[part 3 of 23: packages /E3_1_1_UNECE_Gen2 to /Cluster]
AUTOSAR XML (schema 4-3-0)
package /E3_1_1_UNECE_Gen2  (continued)
  system System  (continued)
    system mapping System_Mappings  (continued)
      data-mappings:  (continued)
        communication-direction=IN, data-element=Grundumfang_XIX_Klima.Geltungsbereich_E3_1_1_UNECE_Gen2.RP_IF_PTC_HVb_Err_Intern_TNCTOC_XIX_Grundumfang_XIX_Klima.DE_PTC_HVb_Err_Intern_TNCTOC, system-signal=PTC_HVb_Err_Intern_TNCTOC
        communication-direction=IN, data-element=Grundumfang_XIX_Klima.Geltungsbereich_E3_1_1_UNECE_Gen2.RP_IF_PTC_HVb_Err_Leckagestrom_XIX_Grundumfang_XIX_Klima.DE_PTC_HVb_Err_Leckagestrom, system-signal=PTC_HVb_Err_Leckagestrom
        communication-direction=IN, data-element=Grundumfang_XIX_Klima.Geltungsbereich_E3_1_1_UNECE_Gen2.RP_IF_PTC_HVb_Err_Leckagestrom_TNCTOC_XIX_Grundumfang_XIX_Klima.DE_PTC_HVb_Err_Leckagestrom_TNCTOC, system-signal=PTC_HVb_Err_Leckagestrom_TNCTOC
        communication-direction=IN, data-element=Grundumfang_XIX_Klima.Geltungsbereich_E3_1_1_UNECE_Gen2.RP_IF_PTC_HVb_Err_Temperaturschutz_XIX_Grundumfang_XIX_Klima.DE_PTC_HVb_Err_Temperaturschutz, system-signal=PTC_HVb_Err_Temperaturschutz
        communication-direction=IN, data-element=Grundumfang_XIX_Klima.Geltungsbereich_E3_1_1_UNECE_Gen2.RP_IF_PTC_HVb_Err_TempSchutz_TNCTOC_XIX_Grundumfang_XIX_Klima.DE_PTC_HVb_Err_TempSchutz_TNCTOC, system-signal=PTC_HVb_Err_TempSchutz_TNCTOC
        communication-direction=IN, data-element=Grundumfang_XIX_Klima.Geltungsbereich_E3_1_1_UNECE_Gen2.RP_IF_PTC_HVb_ERR_TNCTOC_XIX_Grundumfang_XIX_Klima.DE_PTC_HVb_ERR_TNCTOC, system-signal=PTC_HVb_ERR_TNCTOC
        communication-direction=IN, data-element=Grundumfang_XIX_Klima.Geltungsbereich_E3_1_1_UNECE_Gen2.RP_IF_PTC_HVb_Err_Ueberstromabs_TNCTOC_XIX_Grundumfang_XIX_Klima.DE_PTC_HVb_Err_Ueberstromabs_TNCTOC, system-signal=PTC_HVb_Err_Ueberstromabs_TNCTOC
        communication-direction=IN, data-element=Grundumfang_XIX_Klima.Geltungsbereich_E3_1_1_UNECE_Gen2.RP_IF_PTC_HVb_Err_Ueberstromabschaltung_XIX_Grundumfang_XIX_Klima.DE_PTC_HVb_Err_Ueberstromabschaltung, system-signal=PTC_HVb_Err_Ueberstromabschaltung
        communication-direction=IN, data-element=Grundumfang_XIX_Klima.Geltungsbereich_E3_1_1_UNECE_Gen2.RP_IF_PTC_HVb_Heizmedium_Sensor_1_XIX_Grundumfang_XIX_Klima.DE_PTC_HVb_Heizmedium_Sensor_1, system-signal=PTC_HVb_Heizmedium_Sensor_1
        communication-direction=IN, data-element=Grundumfang_XIX_Klima.Geltungsbereich_E3_1_1_UNECE_Gen2.RP_IF_PTC_HVb_Heizmedium_Sensor_2_XIX_Grundumfang_XIX_Klima.DE_PTC_HVb_Heizmedium_Sensor_2, system-signal=PTC_HVb_Heizmedium_Sensor_2
        communication-direction=IN, data-element=Grundumfang_XIX_Klima.Geltungsbereich_E3_1_1_UNECE_Gen2.RP_IF_PTC_HVb_I_ist_XIX_Grundumfang_XIX_Klima.DE_PTC_HVb_I_ist, system-signal=PTC_HVb_I_ist
        communication-direction=IN, data-element=Grundumfang_XIX_Klima.Geltungsbereich_E3_1_1_UNECE_Gen2.RP_IF_PTC_HVb_ResponseError_XIX_Grundumfang_XIX_Klima.DE_PTC_HVb_ResponseError, system-signal=PTC_HVb_ResponseError
        communication-direction=IN, data-element=Grundumfang_XIX_Klima.Geltungsbereich_E3_1_1_UNECE_Gen2.RP_IF_PTC_HVb_Status_PTC_XIX_Grundumfang_XIX_Klima.DE_PTC_HVb_Status_PTC, system-signal=PTC_HVb_Status_PTC
        communication-direction=IN, data-element=Grundumfang_XIX_Klima.Geltungsbereich_E3_1_1_UNECE_Gen2.RP_IF_PTC_HVb_Status_UBatt_XIX_Grundumfang_XIX_Klima.DE_PTC_HVb_Status_UBatt, system-signal=PTC_HVb_Status_UBatt
        communication-direction=IN, data-element=Grundumfang_XIX_Klima.Geltungsbereich_E3_1_1_UNECE_Gen2.RP_IF_PTC_HVb_Temp_PCB_XIX_Grundumfang_XIX_Klima.DE_PTC_HVb_Temp_PCB, system-signal=PTC_HVb_Temp_PCB
        communication-direction=IN, data-element=Grundumfang_XIX_Klima.Geltungsbereich_E3_1_1_UNECE_Gen2.RP_IF_PTC_HVb_TimeOut_Fehler_XIX_Grundumfang_XIX_Klima.DE_PTC_HVb_TimeOut_Fehler, system-signal=PTC_HVb_TimeOut_Fehler
        communication-direction=IN, data-element=Grundumfang_XIX_Klima.Geltungsbereich_E3_1_1_UNECE_Gen2.RP_IF_PTC_HVb_UBatt_XIX_Grundumfang_XIX_Klima.DE_PTC_HVb_UBatt, system-signal=PTC_HVb_UBatt
        communication-direction=IN, data-element=Grundumfang_XIX_Klima.Geltungsbereich_E3_1_1_UNECE_Gen2.RP_IF_PTC_HW_XIX_Grundumfang_XIX_Klima.DE_PTC_HW, system-signal=PTC_HW
        communication-direction=IN, data-element=Grundumfang_XIX_Klima.Geltungsbereich_E3_1_1_UNECE_Gen2.RP_IF_PTC_I_ist_XIX_Grundumfang_XIX_Klima.DE_PTC_I_ist, system-signal=PTC_I_ist
        communication-direction=OUT, data-element=Grundumfang_XIX_Klima.Geltungsbereich_E3_1_1_UNECE_Gen2.SP_IF_PTC_I_ist_XIX_Grundumfang_XIX_Klima.DE_PTC_I_ist, system-signal=PTC_I_ist
        communication-direction=OUT, data-element=Grundumfang_XIX_Klima.Geltungsbereich_E3_1_1_UNECE_Gen2.SP_IF_PTC_Nenn_Strom_XIX_Grundumfang_XIX_Klima.DE_PTC_Nenn_Strom, system-signal=PTC_Nenn_Strom
        communication-direction=IN, data-element=Grundumfang_XIX_Klima.Geltungsbereich_E3_1_1_UNECE_Gen2.RP_IF_PTC_P_ist_XIX_Grundumfang_XIX_Klima.DE_PTC_P_ist, system-signal=PTC_P_ist
        communication-direction=OUT, data-element=Grundumfang_XIX_Klima.Geltungsbereich_E3_1_1_UNECE_Gen2.SP_IF_PTC_P_ist_XIX_Grundumfang_XIX_Klima.DE_PTC_P_ist, system-signal=PTC_P_ist
        communication-direction=IN, data-element=Grundumfang_XIX_Klima.Geltungsbereich_E3_1_1_UNECE_Gen2.RP_IF_PTC_ResponseError_XIX_Grundumfang_XIX_Klima.DE_PTC_ResponseError, system-signal=PTC_ResponseError
        communication-direction=IN, data-element=Grundumfang_XIX_Klima.Geltungsbereich_E3_1_1_UNECE_Gen2.RP_IF_PTC_Status_XIX_Grundumfang_XIX_Klima.DE_PTC_Status, system-signal=PTC_Status
        communication-direction=IN, data-element=Grundumfang_XIX_Klima.Geltungsbereich_E3_1_1_UNECE_Gen2.RP_IF_PTC_Status_PTC_XIX_Grundumfang_XIX_Klima.DE_PTC_Status_PTC, system-signal=PTC_Status_PTC
        communication-direction=IN, data-element=Grundumfang_XIX_Klima.Geltungsbereich_E3_1_1_UNECE_Gen2.RP_IF_PTC_Status_UBatt_XIX_Grundumfang_XIX_Klima.DE_PTC_Status_UBatt, system-signal=PTC_Status_UBatt
        communication-direction=IN, data-element=Grundumfang_XIX_Klima.Geltungsbereich_E3_1_1_UNECE_Gen2.RP_IF_PTC_SW_XIX_Grundumfang_XIX_Klima.DE_PTC_SW, system-signal=PTC_SW
        communication-direction=IN, data-element=Grundumfang_XIX_Klima.Geltungsbereich_E3_1_1_UNECE_Gen2.RP_IF_PTC_Temp_PCB_XIX_Grundumfang_XIX_Klima.DE_PTC_Temp_PCB, system-signal=PTC_Temp_PCB
        communication-direction=IN, data-element=Grundumfang_XIX_Klima.Geltungsbereich_E3_1_1_UNECE_Gen2.RP_IF_PTC_TimeOut_Fehler_XIX_Grundumfang_XIX_Klima.DE_PTC_TimeOut_Fehler, system-signal=PTC_TimeOut_Fehler
        communication-direction=IN, data-element=Grundumfang_XIX_Klima.Geltungsbereich_E3_1_1_UNECE_Gen2.RP_IF_PTC_UBatt_XIX_Grundumfang_XIX_Klima.DE_PTC_UBatt, system-signal=PTC_UBatt
        communication-direction=OUT, data-element=Grundumfang_XIX_Klima.Geltungsbereich_E3_1_1_UNECE_Gen2.SP_IF_PTCs_01_alt_XIX_Grundumfang_XIX_Klima.DE_PTCs_01_alt, system-signal=PTCs_01_alt
        communication-direction=IN, data-element=Grundumfang_XIX_Klima.Geltungsbereich_E3_1_1_UNECE_Gen2.RP_IF_RS_defekt_XIX_Grundumfang_XIX_Klima.DE_RS_defekt, system-signal=RS_defekt
        communication-direction=IN, data-element=Grundumfang_XIX_Klima.Geltungsbereich_E3_1_1_UNECE_Gen2.RP_IF_RS_Regenmenge_XIX_Grundumfang_XIX_Klima.DE_RS_Regenmenge, system-signal=RS_Regenmenge
        communication-direction=IN, data-element=Grundumfang_XIX_Klima.Geltungsbereich_E3_1_1_UNECE_Gen2.RP_IF_RS_Wischergeschwindigkeit_XIX_Grundumfang_XIX_Klima.DE_RS_Wischergeschwindigkeit, system-signal=RS_Wischergeschwindigkeit
        communication-direction=OUT, data-element=Grundumfang_XIX_Klima.Geltungsbereich_E3_1_1_UNECE_Gen2.SP_IF_Scheibenreinigung_XIX_Grundumfang_XIX_Klima.DE_Scheibenreinigung, system-signal=Scheibenreinigung
        communication-direction=IN, data-element=Grundumfang_XIX_Klima.Geltungsbereich_E3_1_1_UNECE_Gen2.RP_IF_SI_BUS_04_XIX_Grundumfang_XIX_Klima.DE_SI_BUS_04, system-signal=SI_BUS_04
        communication-direction=IN, data-element=Grundumfang_XIX_Klima.Geltungsbereich_E3_1_1_UNECE_Gen2.RP_IF_SI_CAB_V15_XIX_Grundumfang_XIX_Klima.DE_SI_CAB_V15, system-signal=SI_CAB_V15
        communication-direction=IN, data-element=Grundumfang_XIX_Klima.Geltungsbereich_E3_1_1_UNECE_Gen2.RP_IF_SI_NWDF_XIX_Grundumfang_XIX_Klima.DE_SI_NWDF, system-signal=SI_NWDF
        communication-direction=IN, data-element=Grundumfang_XIX_Klima.Geltungsbereich_E3_1_1_UNECE_Gen2.RP_IF_SI_NWDF_gueltig_XIX_Grundumfang_XIX_Klima.DE_SI_NWDF_gueltig, system-signal=SI_NWDF_gueltig
        communication-direction=IN, data-element=Grundumfang_XIX_Klima.Geltungsbereich_E3_1_1_UNECE_Gen2.RP_IF_SI_P_Mode_XIX_Grundumfang_XIX_Klima.DE_SI_P_Mode, system-signal=SI_P_Mode
        communication-direction=IN, data-element=Grundumfang_XIX_Klima.Geltungsbereich_E3_1_1_UNECE_Gen2.RP_IF_SI_P_Mode_gueltig_XIX_Grundumfang_XIX_Klima.DE_SI_P_Mode_gueltig, system-signal=SI_P_Mode_gueltig
        communication-direction=IN, data-element=Grundumfang_XIX_Klima.Geltungsbereich_E3_1_1_UNECE_Gen2.RP_IF_SI_QRS_Mode_XIX_Grundumfang_XIX_Klima.DE_SI_QRS_Mode, system-signal=SI_QRS_Mode
        communication-direction=IN, data-element=Grundumfang_XIX_Klima.Geltungsbereich_E3_1_1_UNECE_Gen2.RP_IF_SI_T_Mode_XIX_Grundumfang_XIX_Klima.DE_SI_T_Mode, system-signal=SI_T_Mode
        communication-direction=OUT, data-element=Grundumfang_XIX_Klima.Geltungsbereich_E3_1_1_UNECE_Gen2.SP_IF_SI_T_Mode_XIX_Grundumfang_XIX_Klima.DE_SI_T_Mode, system-signal=SI_T_Mode
        communication-direction=IN, data-element=Grundumfang_XIX_Klima.Geltungsbereich_E3_1_1_UNECE_Gen2.RP_IF_SI_T_Schutz_XIX_Grundumfang_XIX_Klima.DE_SI_T_Schutz, system-signal=SI_T_Schutz
        communication-direction=OUT, data-element=Grundumfang_XIX_Klima.Geltungsbereich_E3_1_1_UNECE_Gen2.SP_IF_SI_T_Schutz_XIX_Grundumfang_XIX_Klima.DE_SI_T_Schutz, system-signal=SI_T_Schutz
        communication-direction=OUT, data-element=Grundumfang_XIX_Klima.Geltungsbereich_E3_1_1_UNECE_Gen2.SP_IF_SIL_Stufe_LED_HL_XIX_Grundumfang_XIX_Klima.DE_SIL_Stufe_LED_HL, system-signal=SIL_Stufe_LED_HL
        communication-direction=OUT, data-element=Grundumfang_XIX_Klima.Geltungsbereich_E3_1_1_UNECE_Gen2.SP_IF_SIL_Stufe_LED_HR_XIX_Grundumfang_XIX_Klima.DE_SIL_Stufe_LED_HR, system-signal=SIL_Stufe_LED_HR
        communication-direction=IN, data-element=Grundumfang_XIX_Klima.Geltungsbereich_E3_1_1_UNECE_Gen2.RP_IF_SIL_Stufe_LED_li_XIX_Grundumfang_XIX_Klima.DE_SIL_Stufe_LED_li, system-signal=SIL_Stufe_LED_li
        communication-direction=IN, data-element=Grundumfang_XIX_Klima.Geltungsbereich_E3_1_1_UNECE_Gen2.RP_IF_SIL_Stufe_LED_re_XIX_Grundumfang_XIX_Klima.DE_SIL_Stufe_LED_re, system-signal=SIL_Stufe_LED_re
        communication-direction=IN, data-element=Grundumfang_XIX_Klima.Geltungsbereich_E3_1_1_UNECE_Gen2.RP_IF_SMod_SIH_Stufe_hl_XIX_Grundumfang_XIX_Klima.DE_SMod_SIH_Stufe_hl, system-signal=SMod_SIH_Stufe_hl
        communication-direction=IN, data-element=Grundumfang_XIX_Klima.Geltungsbereich_E3_1_1_UNECE_Gen2.RP_IF_SMod_SIH_Stufe_hr_XIX_Grundumfang_XIX_Klima.DE_SMod_SIH_Stufe_hr, system-signal=SMod_SIH_Stufe_hr
        communication-direction=IN, data-element=Grundumfang_XIX_Klima.Geltungsbereich_E3_1_1_UNECE_Gen2.RP_IF_SMod_SIL_Stufe_hl_XIX_Grundumfang_XIX_Klima.DE_SMod_SIL_Stufe_hl, system-signal=SMod_SIL_Stufe_hl
        communication-direction=IN, data-element=Grundumfang_XIX_Klima.Geltungsbereich_E3_1_1_UNECE_Gen2.RP_IF_SMod_SIL_Stufe_hr_XIX_Grundumfang_XIX_Klima.DE_SMod_SIL_Stufe_hr, system-signal=SMod_SIL_Stufe_hr
        communication-direction=IN, data-element=Grundumfang_XIX_Klima.Geltungsbereich_E3_1_1_UNECE_Gen2.RP_IF_SMod_SRH_Fehler_XIX_Grundumfang_XIX_Klima.DE_SMod_SRH_Fehler, system-signal=SMod_SRH_Fehler
        communication-direction=IN, data-element=Grundumfang_XIX_Klima.Geltungsbereich_E3_1_1_UNECE_Gen2.RP_IF_SMod_SRH_ResponseError_XIX_Grundumfang_XIX_Klima.DE_SMod_SRH_ResponseError, system-signal=SMod_SRH_ResponseError
        communication-direction=OUT, data-element=Grundumfang_XIX_Klima.Geltungsbereich_E3_1_1_UNECE_Gen2.SP_IF_SOK_FoD_Klima_Req_Challenge_XIX_Grundumfang_XIX_Klima.DE_SOK_FoD_Klima_Req_Challenge, system-signal=SOK_FoD_Klima_Req_Challenge
        communication-direction=IN, data-element=Grundumfang_XIX_Klima.Geltungsbereich_E3_1_1_UNECE_Gen2.RP_IF_SOK_FoD_Klima_Resp_Challenge_XIX_Grundumfang_XIX_Klima.DE_SOK_FoD_Klima_Resp_Challenge, system-signal=SOK_FoD_Klima_Resp_Challenge
        communication-direction=OUT, data-element=Grundumfang_XIX_Klima.Geltungsbereich_E3_1_1_UNECE_Gen2.SP_IF_Soll_Lehne_LLR_li_1_XIX_Grundumfang_XIX_Klima.DE_Soll_Lehne_LLR_li_1, system-signal=Soll_Lehne_LLR_li_1
        communication-direction=OUT, data-element=Grundumfang_XIX_Klima.Geltungsbereich_E3_1_1_UNECE_Gen2.SP_IF_Soll_Lehne_LLR_li_2_XIX_Grundumfang_XIX_Klima.DE_Soll_Lehne_LLR_li_2, system-signal=Soll_Lehne_LLR_li_2
        communication-direction=OUT, data-element=Grundumfang_XIX_Klima.Geltungsbereich_E3_1_1_UNECE_Gen2.SP_IF_Soll_Lehne_LLR_re_1_XIX_Grundumfang_XIX_Klima.DE_Soll_Lehne_LLR_re_1, system-signal=Soll_Lehne_LLR_re_1
        communication-direction=OUT, data-element=Grundumfang_XIX_Klima.Geltungsbereich_E3_1_1_UNECE_Gen2.SP_IF_Soll_Lehne_LLR_re_2_XIX_Grundumfang_XIX_Klima.DE_Soll_Lehne_LLR_re_2, system-signal=Soll_Lehne_LLR_re_2
        communication-direction=OUT, data-element=Grundumfang_XIX_Klima.Geltungsbereich_E3_1_1_UNECE_Gen2.SP_IF_Soll_Sitz_LLR_li_1_XIX_Grundumfang_XIX_Klima.DE_Soll_Sitz_LLR_li_1, system-signal=Soll_Sitz_LLR_li_1
        communication-direction=OUT, data-element=Grundumfang_XIX_Klima.Geltungsbereich_E3_1_1_UNECE_Gen2.SP_IF_Soll_Sitz_LLR_li_2_XIX_Grundumfang_XIX_Klima.DE_Soll_Sitz_LLR_li_2, system-signal=Soll_Sitz_LLR_li_2
        communication-direction=OUT, data-element=Grundumfang_XIX_Klima.Geltungsbereich_E3_1_1_UNECE_Gen2.SP_IF_Soll_Sitz_LLR_re_1_XIX_Grundumfang_XIX_Klima.DE_Soll_Sitz_LLR_re_1, system-signal=Soll_Sitz_LLR_re_1
        communication-direction=OUT, data-element=Grundumfang_XIX_Klima.Geltungsbereich_E3_1_1_UNECE_Gen2.SP_IF_Soll_Sitz_LLR_re_2_XIX_Grundumfang_XIX_Klima.DE_Soll_Sitz_LLR_re_2, system-signal=Soll_Sitz_LLR_re_2
        communication-direction=IN, data-element=Grundumfang_XIX_Klima.Geltungsbereich_E3_1_1_UNECE_Gen2.RP_IF_SoSe_SunInt_2D_Li_XIX_Grundumfang_XIX_Klima.DE_SoSe_SunInt_2D_Li, system-signal=SoSe_SunInt_2D_Li
        communication-direction=IN, data-element=Grundumfang_XIX_Klima.Geltungsbereich_E3_1_1_UNECE_Gen2.RP_IF_SoSe_SunInt_2D_Re_XIX_Grundumfang_XIX_Klima.DE_SoSe_SunInt_2D_Re, system-signal=SoSe_SunInt_2D_Re
        communication-direction=IN, data-element=Grundumfang_XIX_Klima.Geltungsbereich_E3_1_1_UNECE_Gen2.RP_IF_ST_VLD_BLW_CTRL_1_LIN_XIX_Grundumfang_XIX_Klima.DE_ST_VLD_BLW_CTRL_1_LIN, system-signal=ST_VLD_BLW_CTRL_1_LIN
        communication-direction=IN, data-element=Grundumfang_XIX_Klima.Geltungsbereich_E3_1_1_UNECE_Gen2.RP_IF_ST_VLD_BLWb_CTRL_1_LIN_XIX_Grundumfang_XIX_Klima.DE_ST_VLD_BLWb_CTRL_1_LIN, system-signal=ST_VLD_BLWb_CTRL_1_LIN
        communication-direction=IN, data-element=Grundumfang_XIX_Klima.Geltungsbereich_E3_1_1_UNECE_Gen2.RP_IF_ST_VLD_BLWc_CTRL_1_LIN_XIX_Grundumfang_XIX_Klima.DE_ST_VLD_BLWc_CTRL_1_LIN, system-signal=ST_VLD_BLWc_CTRL_1_LIN
        communication-direction=IN, data-element=Grundumfang_XIX_Klima.Geltungsbereich_E3_1_1_UNECE_Gen2.RP_IF_STK_AirCLeaner_Anf_XIX_Grundumfang_XIX_Klima.DE_STK_AirCLeaner_Anf, system-signal=STK_AirCLeaner_Anf
        communication-direction=IN, data-element=Grundumfang_XIX_Klima.Geltungsbereich_E3_1_1_UNECE_Gen2.RP_IF_STK_Anf_AussenspiegelHZ_XIX_Grundumfang_XIX_Klima.DE_STK_Anf_AussenspiegelHZ, system-signal=STK_Anf_AussenspiegelHZ
        communication-direction=IN, data-element=Grundumfang_XIX_Klima.Geltungsbereich_E3_1_1_UNECE_Gen2.RP_IF_STK_Berechnungsphase_XIX_Grundumfang_XIX_Klima.DE_STK_Berechnungsphase, system-signal=STK_Berechnungsphase
        communication-direction=IN, data-element=Grundumfang_XIX_Klima.Geltungsbereich_E3_1_1_UNECE_Gen2.RP_IF_STK_Betriebsdauer_XIX_Grundumfang_XIX_Klima.DE_STK_Betriebsdauer, system-signal=STK_Betriebsdauer
        communication-direction=IN, data-element=Grundumfang_XIX_Klima.Geltungsbereich_E3_1_1_UNECE_Gen2.RP_IF_STK_ErwVK_Anf_XIX_Grundumfang_XIX_Klima.DE_STK_ErwVK_Anf, system-signal=STK_ErwVK_Anf
        communication-direction=IN, data-element=Grundumfang_XIX_Klima.Geltungsbereich_E3_1_1_UNECE_Gen2.RP_IF_STK_ErwVK_Beifahrerzone_XIX_Grundumfang_XIX_Klima.DE_STK_ErwVK_Beifahrerzone, system-signal=STK_ErwVK_Beifahrerzone
        communication-direction=IN, data-element=Grundumfang_XIX_Klima.Geltungsbereich_E3_1_1_UNECE_Gen2.RP_IF_STK_ErwVK_Fahrerzone_XIX_Grundumfang_XIX_Klima.DE_STK_ErwVK_Fahrerzone, system-signal=STK_ErwVK_Fahrerzone
        communication-direction=IN, data-element=Grundumfang_XIX_Klima.Geltungsbereich_E3_1_1_UNECE_Gen2.RP_IF_STK_ErwVK_Heckzone_links_XIX_Grundumfang_XIX_Klima.DE_STK_ErwVK_Heckzone_links, system-signal=STK_ErwVK_Heckzone_links
        communication-direction=IN, data-element=Grundumfang_XIX_Klima.Geltungsbereich_E3_1_1_UNECE_Gen2.RP_IF_STK_ErwVK_Heckzone_rechts_XIX_Grundumfang_XIX_Klima.DE_STK_ErwVK_Heckzone_rechts, system-signal=STK_ErwVK_Heckzone_rechts
        communication-direction=IN, data-element=Grundumfang_XIX_Klima.Geltungsbereich_E3_1_1_UNECE_Gen2.RP_IF_STK_ErwVK_Modus_XIX_Grundumfang_XIX_Klima.DE_STK_ErwVK_Modus, system-signal=STK_ErwVK_Modus
        communication-direction=IN, data-element=Grundumfang_XIX_Klima.Geltungsbereich_E3_1_1_UNECE_Gen2.RP_IF_STK_ErwVK_Scheibenheizung_XIX_Grundumfang_XIX_Klima.DE_STK_ErwVK_Scheibenheizung, system-signal=STK_ErwVK_Scheibenheizung
        communication-direction=IN, data-element=Grundumfang_XIX_Klima.Geltungsbereich_E3_1_1_UNECE_Gen2.RP_IF_STK_FSH_Anf_XIX_Grundumfang_XIX_Klima.DE_STK_FSH_Anf, system-signal=STK_FSH_Anf
        communication-direction=IN, data-element=Grundumfang_XIX_Klima.Geltungsbereich_E3_1_1_UNECE_Gen2.RP_IF_STK_HSH_Anf_XIX_Grundumfang_XIX_Klima.DE_STK_HSH_Anf, system-signal=STK_HSH_Anf
        communication-direction=IN, data-element=Grundumfang_XIX_Klima.Geltungsbereich_E3_1_1_UNECE_Gen2.RP_IF_STK_Klima_Temp_XIX_Grundumfang_XIX_Klima.DE_STK_Klima_Temp, system-signal=STK_Klima_Temp
        communication-direction=IN, data-element=Grundumfang_XIX_Klima.Geltungsbereich_E3_1_1_UNECE_Gen2.RP_IF_STK_KurzVK_Anf_XIX_Grundumfang_XIX_Klima.DE_STK_KurzVK_Anf, system-signal=STK_KurzVK_Anf
        communication-direction=IN, data-element=KlimaStandklimatisierung_Klima_C_XIX_Standklima_XIX_Klima.Geltungsbereich_E3_1_1_UNECE_Gen2.RP_IF_STK_Sofortstart_Sperre_FFB_XIX_KlimaStandklimatisierung_Klima_C_XIX_Standklima_XIX_Klima.DE_STK_Sofortstart_Sperre_FFB, system-signal=STK_Sofortstart_Sperre_FFB
        communication-direction=IN, data-element=Grundumfang_XIX_Klima.Geltungsbereich_E3_1_1_UNECE_Gen2.RP_IF_STK_Standklima_Anf_XIX_Grundumfang_XIX_Klima.DE_STK_Standklima_Anf, system-signal=STK_Standklima_Anf
        communication-direction=IN, data-element=Grundumfang_XIX_Klima.Geltungsbereich_E3_1_1_UNECE_Gen2.RP_IF_STK_Standklima_Timer_Status_XIX_Grundumfang_XIX_Klima.DE_STK_Standklima_Timer_Status, system-signal=STK_Standklima_Timer_Status
        communication-direction=IN, data-element=Grundumfang_XIX_Klima.Geltungsbereich_E3_1_1_UNECE_Gen2.RP_IF_STK_VK_Modus_XIX_Grundumfang_XIX_Klima.DE_STK_VK_Modus, system-signal=STK_VK_Modus
        communication-direction=OUT, data-element=Grundumfang_XIX_Klima.Geltungsbereich_E3_1_1_UNECE_Gen2.SP_IF_STRG1_Adresse_Aktuator_XIX_Grundumfang_XIX_Klima.DE_STRG1_Adresse_Aktuator, system-signal=STRG1_Adresse_Aktuator
        communication-direction=OUT, data-element=Grundumfang_XIX_Klima.Geltungsbereich_E3_1_1_UNECE_Gen2.SP_IF_STRG1_Geschwindigkeitsvorgabe_XIX_Grundumfang_XIX_Klima.DE_STRG1_Geschwindigkeitsvorgabe, system-signal=STRG1_Geschwindigkeitsvorgabe
        communication-direction=OUT, data-element=Grundumfang_XIX_Klima.Geltungsbereich_E3_1_1_UNECE_Gen2.SP_IF_STRG1_Notlauffreigabe_XIX_Grundumfang_XIX_Klima.DE_STRG1_Notlauffreigabe, system-signal=STRG1_Notlauffreigabe
        communication-direction=OUT, data-element=Grundumfang_XIX_Klima.Geltungsbereich_E3_1_1_UNECE_Gen2.SP_IF_STRG1_Select_Positionsvorgabe_XIX_Grundumfang_XIX_Klima.DE_STRG1_Select_Positionsvorgabe, system-signal=STRG1_Select_Positionsvorgabe
        communication-direction=OUT, data-element=Grundumfang_XIX_Klima.Geltungsbereich_E3_1_1_UNECE_Gen2.SP_IF_STRG1_Soll_Position_Aktuator_XIX_Grundumfang_XIX_Klima.DE_STRG1_Soll_Position_Aktuator, system-signal=STRG1_Soll_Position_Aktuator
        communication-direction=OUT, data-element=Grundumfang_XIX_Klima.Geltungsbereich_E3_1_1_UNECE_Gen2.SP_IF_STRG1_Spulenbestromung_XIX_Grundumfang_XIX_Klima.DE_STRG1_Spulenbestromung, system-signal=STRG1_Spulenbestromung
        communication-direction=OUT, data-element=Grundumfang_XIX_Klima.Geltungsbereich_E3_1_1_UNECE_Gen2.SP_IF_STRG4_Adresse_Aktuator_XIX_Grundumfang_XIX_Klima.DE_STRG4_Adresse_Aktuator, system-signal=STRG4_Adresse_Aktuator
        communication-direction=OUT, data-element=Grundumfang_XIX_Klima.Geltungsbereich_E3_1_1_UNECE_Gen2.SP_IF_STRG4_Clear_Event_Flags_XIX_Grundumfang_XIX_Klima.DE_STRG4_Clear_Event_Flags, system-signal=STRG4_Clear_Event_Flags
        communication-direction=OUT, data-element=Grundumfang_XIX_Klima.Geltungsbereich_E3_1_1_UNECE_Gen2.SP_IF_STRG4_Drehrichtung_XIX_Grundumfang_XIX_Klima.DE_STRG4_Drehrichtung, system-signal=STRG4_Drehrichtung
        communication-direction=OUT, data-element=Grundumfang_XIX_Klima.Geltungsbereich_E3_1_1_UNECE_Gen2.SP_IF_STRG4_Freigabe_Blockiererkennung_XIX_Grundumfang_XIX_Klima.DE_STRG4_Freigabe_Blockiererkennung, system-signal=STRG4_Freigabe_Blockiererkennung
        communication-direction=OUT, data-element=Grundumfang_XIX_Klima.Geltungsbereich_E3_1_1_UNECE_Gen2.SP_IF_STRG4_Geschwindigkeitsvorgabe_XIX_Grundumfang_XIX_Klima.DE_STRG4_Geschwindigkeitsvorgabe, system-signal=STRG4_Geschwindigkeitsvorgabe
        communication-direction=OUT, data-element=Grundumfang_XIX_Klima.Geltungsbereich_E3_1_1_UNECE_Gen2.SP_IF_STRG4_Notlauffreigabe_XIX_Grundumfang_XIX_Klima.DE_STRG4_Notlauffreigabe, system-signal=STRG4_Notlauffreigabe
        communication-direction=OUT, data-element=Grundumfang_XIX_Klima.Geltungsbereich_E3_1_1_UNECE_Gen2.SP_IF_STRG4_Notlaufposition_XIX_Grundumfang_XIX_Klima.DE_STRG4_Notlaufposition, system-signal=STRG4_Notlaufposition
        communication-direction=OUT, data-element=Grundumfang_XIX_Klima.Geltungsbereich_E3_1_1_UNECE_Gen2.SP_IF_STRG4_Programmierdaten_speichern_XIX_Grundumfang_XIX_Klima.DE_STRG4_Programmierdaten_speichern, system-signal=STRG4_Programmierdaten_speichern
        communication-direction=OUT, data-element=Grundumfang_XIX_Klima.Geltungsbereich_E3_1_1_UNECE_Gen2.SP_IF_STRG4_Select_Positionsvorgabe_XIX_Grundumfang_XIX_Klima.DE_STRG4_Select_Positionsvorgabe, system-signal=STRG4_Select_Positionsvorgabe
        communication-direction=OUT, data-element=Grundumfang_XIX_Klima.Geltungsbereich_E3_1_1_UNECE_Gen2.SP_IF_STRG4_Soll_Position_Aktuator_XIX_Grundumfang_XIX_Klima.DE_STRG4_Soll_Position_Aktuator, system-signal=STRG4_Soll_Position_Aktuator
        communication-direction=OUT, data-element=Grundumfang_XIX_Klima.Geltungsbereich_E3_1_1_UNECE_Gen2.SP_IF_STRG4_Spulenbestromung_XIX_Grundumfang_XIX_Klima.DE_STRG4_Spulenbestromung, system-signal=STRG4_Spulenbestromung
        communication-direction=OUT, data-element=Grundumfang_XIX_Klima.Geltungsbereich_E3_1_1_UNECE_Gen2.SP_IF_STRG4_Start_Position_Aktuator_XIX_Grundumfang_XIX_Klima.DE_STRG4_Start_Position_Aktuator, system-signal=STRG4_Start_Position_Aktuator
        communication-direction=OUT, data-element=Grundumfang_XIX_Klima.Geltungsbereich_E3_1_1_UNECE_Gen2.SP_IF_STRG4_Stopmodus_XIX_Grundumfang_XIX_Klima.DE_STRG4_Stopmodus, system-signal=STRG4_Stopmodus
        communication-direction=OUT, data-element=Grundumfang_XIX_Klima.Geltungsbereich_E3_1_1_UNECE_Gen2.SP_IF_Thermo_Pred_Innen_Kunde_Anf_XIX_Grundumfang_XIX_Klima.DE_Thermo_Pred_Innen_Kunde_Anf, system-signal=Thermo_Pred_Innen_Kunde_Anf
        communication-direction=OUT, data-element=Grundumfang_XIX_Klima.Geltungsbereich_E3_1_1_UNECE_Gen2.SP_IF_Thermo_Pred_Innen_System_Anf_XIX_Grundumfang_XIX_Klima.DE_Thermo_Pred_Innen_System_Anf, system-signal=Thermo_Pred_Innen_System_Anf
        communication-direction=OUT, data-element=Grundumfang_XIX_Klima.Geltungsbereich_E3_1_1_UNECE_Gen2.SP_IF_Thermo_Pred_P_dyn_In_Efficien1_XIX_Grundumfang_XIX_Klima.DE_Thermo_Pred_P_dyn_In_Efficien1, system-signal=Thermo_Pred_P_dyn_In_Efficien1
        communication-direction=OUT, data-element=Grundumfang_XIX_Klima.Geltungsbereich_E3_1_1_UNECE_Gen2.SP_IF_Thermo_Pred_P_dyn_In_Efficien2_XIX_Grundumfang_XIX_Klima.DE_Thermo_Pred_P_dyn_In_Efficien2, system-signal=Thermo_Pred_P_dyn_In_Efficien2
        communication-direction=OUT, data-element=Grundumfang_XIX_Klima.Geltungsbereich_E3_1_1_UNECE_Gen2.SP_IF_Thermo_Pred_P_dyn_In_Standard_XIX_Grundumfang_XIX_Klima.DE_Thermo_Pred_P_dyn_In_Standard, system-signal=Thermo_Pred_P_dyn_In_Standard
        communication-direction=OUT, data-element=Grundumfang_XIX_Klima.Geltungsbereich_E3_1_1_UNECE_Gen2.SP_IF_Thermo_Pred_P_dyn_Innen_XIX_Grundumfang_XIX_Klima.DE_Thermo_Pred_P_dyn_Innen, system-signal=Thermo_Pred_P_dyn_Innen
        communication-direction=OUT, data-element=Grundumfang_XIX_Klima.Geltungsbereich_E3_1_1_UNECE_Gen2.SP_IF_Thermo_Pred_P_stat_In_Efficien1_XIX_Grundumfang_XIX_Klima.DE_Thermo_Pred_P_stat_In_Efficien1, system-signal=Thermo_Pred_P_stat_In_Efficien1
        communication-direction=OUT, data-element=Grundumfang_XIX_Klima.Geltungsbereich_E3_1_1_UNECE_Gen2.SP_IF_Thermo_Pred_P_stat_In_Efficien2_XIX_Grundumfang_XIX_Klima.DE_Thermo_Pred_P_stat_In_Efficien2, system-signal=Thermo_Pred_P_stat_In_Efficien2
        communication-direction=OUT, data-element=Grundumfang_XIX_Klima.Geltungsbereich_E3_1_1_UNECE_Gen2.SP_IF_Thermo_Pred_P_stat_In_Standard_XIX_Grundumfang_XIX_Klima.DE_Thermo_Pred_P_stat_In_Standard, system-signal=Thermo_Pred_P_stat_In_Standard
        communication-direction=OUT, data-element=Grundumfang_XIX_Klima.Geltungsbereich_E3_1_1_UNECE_Gen2.SP_IF_Thermo_Pred_P_stat_Innen_XIX_Grundumfang_XIX_Klima.DE_Thermo_Pred_P_stat_Innen, system-signal=Thermo_Pred_P_stat_Innen
        communication-direction=OUT, data-element=Grundumfang_XIX_Klima.Geltungsbereich_E3_1_1_UNECE_Gen2.SP_IF_Thermo_Pred_T_dyn_In_Efficien1_XIX_Grundumfang_XIX_Klima.DE_Thermo_Pred_T_dyn_In_Efficien1, system-signal=Thermo_Pred_T_dyn_In_Efficien1
        communication-direction=OUT, data-element=Grundumfang_XIX_Klima.Geltungsbereich_E3_1_1_UNECE_Gen2.SP_IF_Thermo_Pred_T_dyn_In_Efficien2_XIX_Grundumfang_XIX_Klima.DE_Thermo_Pred_T_dyn_In_Efficien2, system-signal=Thermo_Pred_T_dyn_In_Efficien2
        communication-direction=OUT, data-element=Grundumfang_XIX_Klima.Geltungsbereich_E3_1_1_UNECE_Gen2.SP_IF_Thermo_Pred_T_dyn_In_Standard_XIX_Grundumfang_XIX_Klima.DE_Thermo_Pred_T_dyn_In_Standard, system-signal=Thermo_Pred_T_dyn_In_Standard
        communication-direction=OUT, data-element=Grundumfang_XIX_Klima.Geltungsbereich_E3_1_1_UNECE_Gen2.SP_IF_Thermo_Pred_T_dyn_Innen_XIX_Grundumfang_XIX_Klima.DE_Thermo_Pred_T_dyn_Innen, system-signal=Thermo_Pred_T_dyn_Innen
        communication-direction=OUT, data-element=Grundumfang_XIX_Klima.Geltungsbereich_E3_1_1_UNECE_Gen2.SP_IF_Thermo_Verbrauch_BTL_XIX_Grundumfang_XIX_Klima.DE_Thermo_Verbrauch_BTL, system-signal=Thermo_Verbrauch_BTL
        communication-direction=OUT, data-element=Grundumfang_XIX_Klima.Geltungsbereich_E3_1_1_UNECE_Gen2.SP_IF_Thermo_Verbrauch_BTL_Ueberlauf_XIX_Grundumfang_XIX_Klima.DE_Thermo_Verbrauch_BTL_Ueberlauf, system-signal=Thermo_Verbrauch_BTL_Ueberlauf
        communication-direction=OUT, data-element=Grundumfang_XIX_Klima.Geltungsbereich_E3_1_1_UNECE_Gen2.SP_IF_Thermo_Verbrauch_Innen_XIX_Grundumfang_XIX_Klima.DE_Thermo_Verbrauch_Innen, system-signal=Thermo_Verbrauch_Innen
        communication-direction=OUT, data-element=Grundumfang_XIX_Klima.Geltungsbereich_E3_1_1_UNECE_Gen2.SP_IF_Thermo_Verbrauch_Innen_Ueberlauf_XIX_Grundumfang_XIX_Klima.DE_Thermo_Verbrauch_Innen_Ueberlauf, system-signal=Thermo_Verbrauch_Innen_Ueberlauf
        communication-direction=IN, data-element=Grundumfang_XIX_Klima.Geltungsbereich_E3_1_1_UNECE_Gen2.RP_IF_TSK_QBit_Steigung_XIX_Grundumfang_XIX_Klima.DE_TSK_QBit_Steigung, system-signal=TSK_QBit_Steigung
        communication-direction=IN, data-element=Grundumfang_XIX_Klima.Geltungsbereich_E3_1_1_UNECE_Gen2.RP_IF_TSK_Steigung_02_XIX_Grundumfang_XIX_Klima.DE_TSK_Steigung_02, system-signal=TSK_Steigung_02
        communication-direction=IN, data-element=Grundumfang_XIX_Klima.Geltungsbereich_E3_1_1_UNECE_Gen2.RP_IF_UH_Jahr_XIX_Grundumfang_XIX_Klima.DE_UH_Jahr, system-signal=UH_Jahr
        communication-direction=OUT, data-element=Grundumfang_XIX_Klima.Geltungsbereich_E3_1_1_UNECE_Gen2.SP_IF_UH_Jahr_XIX_Grundumfang_XIX_Klima.DE_UH_Jahr, system-signal=UH_Jahr
        communication-direction=IN, data-element=Grundumfang_XIX_Klima.Geltungsbereich_E3_1_1_UNECE_Gen2.RP_IF_UH_Minute_XIX_Grundumfang_XIX_Klima.DE_UH_Minute, system-signal=UH_Minute
        communication-direction=IN, data-element=Grundumfang_XIX_Klima.Geltungsbereich_E3_1_1_UNECE_Gen2.RP_IF_UH_Monat_XIX_Grundumfang_XIX_Klima.DE_UH_Monat, system-signal=UH_Monat
        communication-direction=OUT, data-element=Grundumfang_XIX_Klima.Geltungsbereich_E3_1_1_UNECE_Gen2.SP_IF_UH_Monat_XIX_Grundumfang_XIX_Klima.DE_UH_Monat, system-signal=UH_Monat
        communication-direction=IN, data-element=Grundumfang_XIX_Klima.Geltungsbereich_E3_1_1_UNECE_Gen2.RP_IF_UH_Sekunde_XIX_Grundumfang_XIX_Klima.DE_UH_Sekunde, system-signal=UH_Sekunde
        communication-direction=IN, data-element=Grundumfang_XIX_Klima.Geltungsbereich_E3_1_1_UNECE_Gen2.RP_IF_UH_Stunde_XIX_Grundumfang_XIX_Klima.DE_UH_Stunde, system-signal=UH_Stunde
        communication-direction=IN, data-element=Grundumfang_XIX_Klima.Geltungsbereich_E3_1_1_UNECE_Gen2.RP_IF_UH_Tag_XIX_Grundumfang_XIX_Klima.DE_UH_Tag, system-signal=UH_Tag
        communication-direction=OUT, data-element=Grundumfang_XIX_Klima.Geltungsbereich_E3_1_1_UNECE_Gen2.SP_IF_UH_Tag_XIX_Grundumfang_XIX_Klima.DE_UH_Tag, system-signal=UH_Tag
        communication-direction=IN, data-element=Grundumfang_XIX_Klima.Geltungsbereich_E3_1_1_UNECE_Gen2.RP_IF_UIF_Itos_roh_XIX_Grundumfang_XIX_Klima.DE_UIF_Itos_roh, system-signal=UIF_Itos_roh
        communication-direction=IN, data-element=Grundumfang_XIX_Klima.Geltungsbereich_E3_1_1_UNECE_Gen2.RP_IF_UIF_Ref_roh_XIX_Grundumfang_XIX_Klima.DE_UIF_Ref_roh, system-signal=UIF_Ref_roh
        communication-direction=IN, data-element=Grundumfang_XIX_Klima.Geltungsbereich_E3_1_1_UNECE_Gen2.RP_IF_UIF_ResponseError_XIX_Grundumfang_XIX_Klima.DE_UIF_ResponseError, system-signal=UIF_ResponseError
        communication-direction=IN, data-element=Grundumfang_XIX_Klima.Geltungsbereich_E3_1_1_UNECE_Gen2.RP_IF_UIF_Status_XIX_Grundumfang_XIX_Klima.DE_UIF_Status, system-signal=UIF_Status
        communication-direction=IN, data-element=Grundumfang_XIX_Klima.Geltungsbereich_E3_1_1_UNECE_Gen2.RP_IF_UIF_Sun_roh_XIX_Grundumfang_XIX_Klima.DE_UIF_Sun_roh, system-signal=UIF_Sun_roh
        communication-direction=IN, data-element=Grundumfang_XIX_Klima.Geltungsbereich_E3_1_1_UNECE_Gen2.RP_IF_UIF_SunInt_XIX_Grundumfang_XIX_Klima.DE_UIF_SunInt, system-signal=UIF_SunInt
        communication-direction=IN, data-element=Grundumfang_XIX_Klima.Geltungsbereich_E3_1_1_UNECE_Gen2.RP_IF_UIF_Temp_OutOfRange_XIX_Grundumfang_XIX_Klima.DE_UIF_Temp_OutOfRange, system-signal=UIF_Temp_OutOfRange
        communication-direction=IN, data-element=Grundumfang_XIX_Klima.Geltungsbereich_E3_1_1_UNECE_Gen2.RP_IF_UIF_Temperatur_XIX_Grundumfang_XIX_Klima.DE_UIF_Temperatur, system-signal=UIF_Temperatur
        communication-direction=OUT, data-element=Grundumfang_XIX_Klima.Geltungsbereich_E3_1_1_UNECE_Gen2.SP_IF_Umluft_XIX_Grundumfang_XIX_Klima.DE_Umluft, system-signal=Umluft
        communication-direction=IN, data-element=Grundumfang_XIX_Klima.Geltungsbereich_E3_1_1_UNECE_Gen2.RP_IF_Vehicle_Driving_Cycle_XIX_Grundumfang_XIX_Klima.DE_Vehicle_Driving_Cycle, system-signal=Vehicle_Driving_Cycle
        communication-direction=OUT, data-element=Grundumfang_XIX_Klima.Geltungsbereich_E3_1_1_UNECE_Gen2.SP_IF_Verbauposition_LLR_li_XIX_Grundumfang_XIX_Klima.DE_Verbauposition_LLR_li, system-signal=Verbauposition_LLR_li
        communication-direction=OUT, data-element=Grundumfang_XIX_Klima.Geltungsbereich_E3_1_1_UNECE_Gen2.SP_IF_Verbauposition_LLR_re_XIX_Grundumfang_XIX_Klima.DE_Verbauposition_LLR_re, system-signal=Verbauposition_LLR_re
        communication-direction=IN, data-element=VKMS_XIX_Klima.Geltungsbereich_E3_1_1_UNECE_Gen2.RP_IF_VIN_01_MUX_XIX_VKMS_XIX_Klima.DE_VIN_01_MUX, system-signal=VIN_01_MUX
        communication-direction=IN, data-element=VKMS_XIX_Klima.Geltungsbereich_E3_1_1_UNECE_Gen2.RP_IF_VIN_1_XIX_VKMS_XIX_Klima.DE_VIN_1, system-signal=VIN_1
        communication-direction=IN, data-element=VKMS_XIX_Klima.Geltungsbereich_E3_1_1_UNECE_Gen2.RP_IF_VIN_{10..17}_XIX_VKMS_XIX_Klima.DE_VIN_{10..17}, system-signal=VIN_{10..17}
        communication-direction=IN, data-element=VKMS_XIX_Klima.Geltungsbereich_E3_1_1_UNECE_Gen2.RP_IF_VIN_{2..9}_XIX_VKMS_XIX_Klima.DE_VIN_{2..9}, system-signal=VIN_{2..9}
        communication-direction=IN, data-element=Grundumfang_XIX_Klima.Geltungsbereich_E3_1_1_UNECE_Gen2.RP_IF_Waschen_vorne_aktiv_XIX_Grundumfang_XIX_Klima.DE_Waschen_vorne_aktiv, system-signal=Waschen_vorne_aktiv
        communication-direction=IN, data-element=Grundumfang_XIX_Klima.Geltungsbereich_E3_1_1_UNECE_Gen2.RP_IF_Wischer1_Wischgeschwindigkeit_XIX_Grundumfang_XIX_Klima.DE_Wischer1_Wischgeschwindigkeit, system-signal=Wischer1_Wischgeschwindigkeit
        communication-direction=IN, data-element=Grundumfang_XIX_Klima.Geltungsbereich_E3_1_1_UNECE_Gen2.RP_IF_Wischer_vorne_aktiv_XIX_Grundumfang_XIX_Klima.DE_Wischer_vorne_aktiv, system-signal=Wischer_vorne_aktiv
        communication-direction=IN, data-element=Grundumfang_XIX_Klima.Geltungsbereich_E3_1_1_UNECE_Gen2.RP_IF_Wischer_vorne_defekt_XIX_Grundumfang_XIX_Klima.DE_Wischer_vorne_defekt, system-signal=Wischer_vorne_defekt
        communication-direction=IN, data-element=Grundumfang_XIX_Klima.Geltungsbereich_E3_1_1_UNECE_Gen2.RP_IF_ZAS_Kl_15_XIX_Grundumfang_XIX_Klima.DE_ZAS_Kl_15, system-signal=ZAS_Kl_15
        communication-direction=OUT, data-element=Grundumfang_XIX_Klima.Geltungsbereich_E3_1_1_UNECE_Gen2.SP_IF_ZAS_Kl_15_XIX_Grundumfang_XIX_Klima.DE_ZAS_Kl_15, system-signal=ZAS_Kl_15
        communication-direction=IN, data-element=Grundumfang_XIX_Klima.Geltungsbereich_E3_1_1_UNECE_Gen2.RP_IF_ZAS_Kl_S_XIX_Grundumfang_XIX_Klima.DE_ZAS_Kl_S, system-signal=ZAS_Kl_S
        communication-direction=OUT, data-element=Grundumfang_XIX_Klima.Geltungsbereich_E3_1_1_UNECE_Gen2.SP_IF_ZAS_Kl_S_XIX_Grundumfang_XIX_Klima.DE_ZAS_Kl_S, system-signal=ZAS_Kl_S
        communication-direction=IN, data-element=Grundumfang_XIX_Klima.Geltungsbereich_E3_1_1_UNECE_Gen2.RP_IF_ZM_Standzeit_XIX_Grundumfang_XIX_Klima.DE_ZM_Standzeit, system-signal=ZM_Standzeit
        communication-direction=IN, data-element=Grundumfang_XIX_Klima.Geltungsbereich_E3_1_1_UNECE_Gen2.RP_IF_ZV_BT_offen_XIX_Grundumfang_XIX_Klima.DE_ZV_BT_offen, system-signal=ZV_BT_offen
        communication-direction=IN, data-element=Grundumfang_XIX_Klima.Geltungsbereich_E3_1_1_UNECE_Gen2.RP_IF_ZV_FT_offen_XIX_Grundumfang_XIX_Klima.DE_ZV_FT_offen, system-signal=ZV_FT_offen
        communication-direction=IN, data-element=Grundumfang_XIX_Klima.Geltungsbereich_E3_1_1_UNECE_Gen2.RP_IF_ZV_gesafet_extern_ist_XIX_Grundumfang_XIX_Klima.DE_ZV_gesafet_extern_ist, system-signal=ZV_gesafet_extern_ist
        communication-direction=IN, data-element=Grundumfang_XIX_Klima.Geltungsbereich_E3_1_1_UNECE_Gen2.RP_IF_ZV_HBFS_offen_XIX_Grundumfang_XIX_Klima.DE_ZV_HBFS_offen, system-signal=ZV_HBFS_offen
        communication-direction=IN, data-element=Grundumfang_XIX_Klima.Geltungsbereich_E3_1_1_UNECE_Gen2.RP_IF_ZV_HD_offen_XIX_Grundumfang_XIX_Klima.DE_ZV_HD_offen, system-signal=ZV_HD_offen
        communication-direction=IN, data-element=Grundumfang_XIX_Klima.Geltungsbereich_E3_1_1_UNECE_Gen2.RP_IF_ZV_HFS_offen_XIX_Grundumfang_XIX_Klima.DE_ZV_HFS_offen, system-signal=ZV_HFS_offen
        communication-direction=IN, data-element=Grundumfang_XIX_Klima.Geltungsbereich_E3_1_1_UNECE_Gen2.RP_IF_ZV_Schluessel_Zugang_XIX_Grundumfang_XIX_Klima.DE_ZV_Schluessel_Zugang, system-signal=ZV_Schluessel_Zugang
        communication-direction=IN, data-element=Grundumfang_XIX_Klima.Geltungsbereich_E3_1_1_UNECE_Gen2.RP_IF_ZV_verriegelt_extern_ist_XIX_Grundumfang_XIX_Klima.DE_ZV_verriegelt_extern_ist, system-signal=ZV_verriegelt_extern_ist
        communication-direction=IN, data-element=Grundumfang_XIX_Klima.Geltungsbereich_E3_1_1_UNECE_Gen2.RP_IF_ZV_verriegelt_extern_soll_XIX_Grundumfang_XIX_Klima.DE_ZV_verriegelt_extern_soll, system-signal=ZV_verriegelt_extern_soll
        communication-direction=IN, data-element=Grundumfang_XIX_Klima.Geltungsbereich_E3_1_1_UNECE_Gen2.RP_IF_ZV_verriegelt_intern_ist_XIX_Grundumfang_XIX_Klima.DE_ZV_verriegelt_intern_ist, system-signal=ZV_verriegelt_intern_ist
        communication-direction=IN, data-element=Grundumfang_XIX_Klima.Geltungsbereich_E3_1_1_UNECE_Gen2.RP_IF_ZV_verriegelt_intern_soll_XIX_Grundumfang_XIX_Klima.DE_ZV_verriegelt_intern_soll, system-signal=ZV_verriegelt_intern_soll
      sw-mappings:
        5 x swc to ecu mapping, all with ecu-instance=Klima:
          MAPPING_HVEM_Auto_NL_XIX_Klima: component=Geltungsbereich_E3_1_1_UNECE_Gen2.HVEM_Auto_NL_XIX_Klima
          MAPPING_VKMS_XIX_Klima: component=Geltungsbereich_E3_1_1_UNECE_Gen2.VKMS_XIX_Klima
          MAPPING_SC_447_FoD_Slave_8_XIX_Softwareblock_XIX_Klima: component=Geltungsbereich_E3_1_1_UNECE_Gen2.SC_447_FoD_Slave_8_XIX_Softwareblock_XIX_Klima
          MAPPING_KlimaStandklimatisierung_Klima_C_XIX_Standklima_XIX_Klima: component=Geltungsbereich_E3_1_1_UNECE_Gen2.KlimaStandklimatisierung_Klima_C_XIX_Standklima_XIX_Klima
          MAPPING_Grundumfang_XIX_Klima: component=Geltungsbereich_E3_1_1_UNECE_Gen2.Grundumfang_XIX_Klima
    root-software-compositions:
      root sw composition prototype Geltungsbereich_E3_1_1_UNECE_Gen2: software-composition=Geltungsbereich_E3_1_1_UNECE_Gen2
package /ECU
  ecu instance Klima:  # Klima im MEB
    associated-com-i-pdu-group=[Klima_XIX_E3V_EVCANFD_Rx, Klima_XIX_E3V_EVCANFD_Tx, Klima_XIX_Klima_LIN1_Rx, Klima_XIX_Klima_LIN1_Tx, Klima_XIX_Klima_LIN2_Rx, Klima_XIX_Klima_LIN2_Tx, Klima_XIX_Klima_LIN3_Rx, Klima_XIX_Klima_LIN3_Tx, Klima_XIX_Klima_LIN4_Rx, Klima_XIX_Klima_LIN4_Tx, Klima_XIX_Klima_LIN5_Rx, Klima_XIX_Klima_LIN5_Tx, Klima_XIX_Klima_LIN6_Rx, Klima_XIX_Klima_LIN6_Tx, Klima_XIX_Klima_LIN7_Rx, Klima_XIX_Klima_LIN7_Tx]
    diagnostic-address=8
    sleep-mode-supported=true
    wake-up-over-bus-supported=true
    can communication controller CT_E3V_EVCANFD: wake-up-by-controller-supported=true, can-controller-attributes=can-controller-configuration-requirements={can-controller-fd-requirements={max-number-of-time-quanta-per-bit=20, max-sample-point=70.0, max-sync-jump-width=30.0, max-trcv-delay-compensation-offset=3.5E-07, min-number-of-time-quanta-per-bit=20, min-sample-point=70.0, min-sync-jump-width=30.0, min-trcv-delay-compensation-offset=3.5E-07, tx-bit-rate-switch=true}, max-number-of-time-quanta-per-bit=80, max-sample-point=80.0, max-sync-jump-width=20.0, min-number-of-time-quanta-per-bit=80, min-sample-point=80.0, min-sync-jump-width=20.0}
    7 x lin master, all with protocol-version=2.0, time-base=0.01, time-base-jitter=9.0E-4:
      CT_Klima_LIN2
      CT_Klima_LIN1
      CT_Klima_LIN3
      CT_Klima_LIN4
      CT_Klima_LIN7
      CT_Klima_LIN6
      CT_Klima_LIN5
    can communication connector CN_E3V_EVCANFD: comm-controller=CT_E3V_EVCANFD, pnc-gateway-type=NONE
    lin communication connector CN_Klima_LIN2: comm-controller=CT_Klima_LIN2
    lin communication connector CN_Klima_LIN1: comm-controller=CT_Klima_LIN1
    lin communication connector CN_Klima_LIN3: comm-controller=CT_Klima_LIN3
    lin communication connector CN_Klima_LIN4: comm-controller=CT_Klima_LIN4
    lin communication connector CN_Klima_LIN7: comm-controller=CT_Klima_LIN7
    lin communication connector CN_Klima_LIN6: comm-controller=CT_Klima_LIN6
    lin communication connector CN_Klima_LIN5: comm-controller=CT_Klima_LIN5
package /Cluster
  can cluster E3V_EVCANFD: baudrate=500000, protocol-name=CAN, protocol-version=2.0, bus-off-recovery={bor-counter-l-1-to-l-2=1, bor-time-l-1=0.05, bor-time-l-2=0.2}, can-fd-baudrate=2000000  # CAN FD Elektrifizierung
    can physical channel CHNL: comm-connectors=CN_E3V_EVCANFD
      frame Airbag_01_XIX_E3V_EVCANFD: id 0x40, to Klima, frame-length=8, can-addressing-mode=STANDARD, can-frame-rx-behavior=CAN-FD, can-frame-tx-behavior=CAN-FD
        pdu Airbag_01_XIX_E3V_EVCANFD: length=8, minimum-delay=0.01, transmission-mode-true-timing={cyclic-timing={time-offset=0.0, time-period=0.04}, event-controlled-timing={number-of-repetitions=5, repetition-period=0.01}}, unused-bit-pattern=0
          signal Airbag_01_CRC_XIX_Airbag_01_XIX_E3V_EVCANFD: start 0, 8 bit, little-endian, data-type-policy=OVERRIDE, i-signal-type=PRIMITIVE, base-type=BT_Airbag_01_CRC, compu {phys=raw for raw 0..255}, range phys 0..255, raw 0..255, transfer-property=PENDING  # Für MLB: "Berechnung siehe Lastenheft "Kommunikationsabsicherung für FlexRay und CAN"" Ab MQB und MLBevo: "Berechnung siehe Lastenheft "End-to-End Kommunikationsabsicherung"" Endwerte siehe Begleitdokument "S-PDU Kennungsfolgen"
          signal Airbag_01_BZ_XIX_Airbag_01_XIX_E3V_EVCANFD: start 8, 4 bit, little-endian, data-type-policy=OVERRIDE, i-signal-type=PRIMITIVE, base-type=BT_Airbag_01_BZ, compu {phys=raw for raw 0..15}, range phys 0..15, raw 0..15, transfer-property=PENDING
          signal AB_RGS_Anst_XIX_Airbag_01_XIX_E3V_EVCANFD: start 12, 4 bit, little-endian, data-type-policy=OVERRIDE, i-signal-type=PRIMITIVE, init-value=8, base-type=BT_AB_RGS_Anst, compu {4=Cx4_aktiv_Niveau_1 (CM_AB_RGS_Anst_Cx4_aktiv_Niveau_1), 5=Cx5_aktiv_Niveau_2 (CM_AB_RGS_Anst_Cx5_aktiv_Niveau_2), 6=Cx6_aktiv_Niveau_3 (CM_AB_RGS_Anst_Cx6_aktiv_Niveau_3), 7=Cx7_aktiv_Niveau_4 (CM_AB_RGS_Anst_Cx7_aktiv_Niveau_4), 8=Cx8_deaktiviert (CM_AB_RGS_Anst_Cx8_deaktiviert)}, range raw 4..8, transfer-property=TRIGGERED-ON-CHANGE-WITHOUT-REPETITION  # PreCrash-Ansteuerung reversibler Gurtstraffer (Aktivierung und Kraftniveau) 10xx = deaktiviert
          signal AB_Front_Crash_XIX_Airbag_01_XIX_E3V_EVCANFD: start 16, 1 bit, little-endian, data-type-policy=OVERRIDE, i-signal-type=PRIMITIVE, init-value=0, base-type=BT_AB_Front_Crash, compu {0=Cx0_kein_Front_Crash (CM_AB_Front_Crash_Cx0_kein_Front_Crash), 1=Cx1_Front_Crash (CM_AB_Front_Crash_Cx1_Front_Crash)}, range raw 0..1, transfer-property=TRIGGERED-ON-CHANGE  # Bit wird bei Überschreitung der Gurtstraffer-, US- und RdW-Schwelle gesetzt
          signal AB_Heck_Crash_XIX_Airbag_01_XIX_E3V_EVCANFD: start 17, 1 bit, little-endian, data-type-policy=OVERRIDE, i-signal-type=PRIMITIVE, init-value=0, base-type=BT_AB_Heck_Crash, compu {0=Cx0_kein_Heck_Crash (CM_AB_Heck_Crash_Cx0_kein_Heck_Crash), 1=Cx1_Heck_Crash (CM_AB_Heck_Crash_Cx1_Heck_Crash)}, range raw 0..1, transfer-property=TRIGGERED-ON-CHANGE  # Wird für alle neu anlaufenden Projekte umgesetzt: AB8.4, Audi8/VW8
          signal AB_SF_Crash_XIX_Airbag_01_XIX_E3V_EVCANFD: start 18, 1 bit, little-endian, data-type-policy=OVERRIDE, i-signal-type=PRIMITIVE, init-value=0, base-type=BT_AB_SF_Crash, compu {0=Cx0_kein_Seiten_Crash_Fahrer (CM_AB_SF_Crash_Cx0_kein_Seiten_Crash_Fahrer), 1=Cx1_Seiten_Crash_Fahrer (CM_AB_SF_Crash_Cx1_Seiten_Crash_Fahrer)}, range raw 0..1, transfer-property=TRIGGERED-ON-CHANGE  # Z.Zt. nur in Verbindung mit Crash-Intensität >= 100b (Kraftstoffpumpenabschaltung) verwendet.
          signal AB_SB_Crash_XIX_Airbag_01_XIX_E3V_EVCANFD: start 19, 1 bit, little-endian, data-type-policy=OVERRIDE, i-signal-type=PRIMITIVE, init-value=0, base-type=BT_AB_SB_Crash, compu {0=Cx0_kein_Seiten_Crash_Beifahrer (CM_AB_SB_Crash_Cx0_kein_Seiten_Crash_Beifahrer), 1=Cx1_Seiten_Crash_Beifahrer (CM_AB_SB_Crash_Cx1_Seiten_Crash_Beifahrer)}, range raw 0..1, transfer-property=TRIGGERED-ON-CHANGE  # Z.Zt. nur in Verbindung mit Crash-Intensität >= 100b (Kraftstoffpumpenabschaltung) verwendet.
          signal AB_Rollover_Crash_XIX_Airbag_01_XIX_E3V_EVCANFD: start 20, 1 bit, little-endian, data-type-policy=OVERRIDE, i-signal-type=PRIMITIVE, init-value=0, base-type=BT_AB_Rollover_Crash, compu {0=Cx0_kein_Rollover (CM_AB_Rollover_Crash_Cx0_kein_Rollover), 1=Cx1_Rollover (CM_AB_Rollover_Crash_Cx1_Rollover)}, range raw 0..1, transfer-property=TRIGGERED-ON-CHANGE  # Wird im B6/B7 Cabrio und New Beetle Cabrio bedient.
          signal AB_Crash_Int_XIX_Airbag_01_XIX_E3V_EVCANFD: start 21, 3 bit, little-endian, data-type-policy=OVERRIDE, i-signal-type=PRIMITIVE, init-value=0, base-type=BT_AB_Crash_Int, compu {0=Cx0_kein_Crash (CM_AB_Crash_Int_Cx0_kein_Crash), 1=Cx1_Crash_Intensitaet_1 (CM_AB_Crash_Int_Cx1_Crash_Intensitaet_1), 2=Cx2_Crash_Intensitaet_2_nur_Stellgliedtest_MLB_B8 (CM_AB_Crash_Int_Cx2_Crash_Intensitaet_2_nur_Stellgliedtest_MLB_B8) (Crash_Intensitaet_2_(nur_Stellgliedtest_MLB_B8)), 3=Cx3_Crash_Intensitaet_2_nur_D4_C7_Colorado_NF_PAG_Crash_im_MLB_B8 (CM_AB_Crash_Int_Cx3_Crash_Intensitaet_2_nur_D4_C7_Colorado_NF_PAG_Crash_im_MLB_B8) (Crash_Intensitaet_2_(nur_D4_C7_Colorado_NF_PAG__Crash_im_MLB_B8)), 4=Cx4_Crash_Intensitaet_3_alt_VW_AUDI_Stellgliedtest_MLB_B8 (CM_AB_Crash_Int_Cx4_Crash_Intensitaet_3_alt_VW_AUDI_Stellgliedtest_MLB_B8) (Crash_Intensitaet_3_(alt_VW/AUDI__Stellgliedtest_MLB_B8)), 5=Cx5_Crash_Intensitaet_3_alt_PAG (CM_AB_Crash_Int_Cx5_Crash_Intensitaet_3_alt_PAG) (Crash_Intensitaet_3_(alt_PAG)), 7=Cx7_Crash_Intensitaet_3 (CM_AB_Crash_Int_Cx7_Crash_Intensitaet_3)}, range raw 0..7, transfer-property=TRIGGERED-ON-CHANGE, to Klima(timeout 0.5 s)  # Crash_Intensität_1 = fahrzeugabhängige Reaktionen im Crash Crash_Intensität_2 = fahrzeugabhängige Reaktionen im Crash Crash_Intensität_3 = fahrzeugabhängige Reaktionen im Crash Die jeweiligen fahrzeugabhängigen Reaktionen im Crash sind in einem separaten Doors Modul im Airbag-SG beschrieben. Die Information bleibt bei jeder Schwellwert-überschreitung für ~10 s bestehen (Achtung: Energiereserve bei abgetrennter Batterie reicht worstcase nur für 150 ms)
          signal AB_Lampe_XIX_Airbag_01_XIX_E3V_EVCANFD: start 24, 1 bit, little-endian, data-type-policy=OVERRIDE, i-signal-type=PRIMITIVE, init-value=1, base-type=BT_AB_Lampe, compu {0=Cx0_Aus (CM_AB_Lampe_Cx0_Aus), 1=Cx1_Ein (CM_AB_Lampe_Cx1_Ein)}, range raw 0..1, transfer-property=PENDING  # Sicherheitswarnlampe im Kombi wird vom Airbag-SG angesteuert; Zustand der Lampe wird auf dem CAN-Bus ausgegeben (auch Blinkinformation).
          signal AB_Deaktiviert_XIX_Airbag_01_XIX_E3V_EVCANFD: start 25, 1 bit, little-endian, data-type-policy=OVERRIDE, i-signal-type=PRIMITIVE, init-value=0, base-type=BT_AB_Deaktiviert, compu {0=Cx0_aktiv (CM_AB_Deaktiviert_Cx0_aktiv), 1=Cx1_deaktiviert (CM_AB_Deaktiviert_Cx1_deaktiviert)}, range raw 0..1, transfer-property=PENDING  # Airbag oder Gurtstraffer wurden per Anpassung deaktiviert: Aktualisierung erst nach Selbsttest
          signal AB_VB_deaktiviert_XIX_Airbag_01_XIX_E3V_EVCANFD: start 26, 1 bit, little-endian, data-type-policy=OVERRIDE, i-signal-type=PRIMITIVE, init-value=1, base-type=BT_AB_VB_deaktiviert, compu {0=Cx0_Beifahrerairbag_aktiv (CM_AB_VB_deaktiviert_Cx0_Beifahrerairbag_aktiv), 1=Cx1_Beifahrerairbag_deaktiviert (CM_AB_VB_deaktiviert_Cx1_Beifahrerairbag_deaktiviert)}, range raw 0..1, transfer-property=PENDING  # Als Option vorgehalten, Beifahrerairbag wurden per Schlüsselschalter oder Insassenerkennung deaktiviert
          signal AB_Systemfehler_XIX_Airbag_01_XIX_E3V_EVCANFD: start 27, 1 bit, little-endian, data-type-policy=OVERRIDE, i-signal-type=PRIMITIVE, init-value=0, base-type=BT_AB_Systemfehler, compu {0=Cx0_kein_Fehler (CM_AB_Systemfehler_Cx0_kein_Fehler), 1=Cx1_Airbag_Systemfehler (CM_AB_Systemfehler_Cx1_Airbag_Systemfehler)}, range raw 0..1, transfer-property=PENDING  # Systemfehler Ggf. wird Warnlampe dauernd eingeschaltet.
          signal AB_Diagnose_XIX_Airbag_01_XIX_E3V_EVCANFD: start 28, 1 bit, little-endian, data-type-policy=OVERRIDE, i-signal-type=PRIMITIVE, init-value=0, base-type=BT_AB_Diagnose, compu {0=Cx0_nicht_in_Diagnose (CM_AB_Diagnose_Cx0_nicht_in_Diagnose), 1=Cx1_in_Diagnose (CM_AB_Diagnose_Cx1_in_Diagnose)}, range raw 0..1, transfer-property=PENDING  # Airbag in Diagnose
          signal AB_Stellgliedtest_XIX_Airbag_01_XIX_E3V_EVCANFD: start 29, 1 bit, little-endian, data-type-policy=OVERRIDE, i-signal-type=PRIMITIVE, init-value=0, base-type=BT_AB_Stellgliedtest, compu {0=Cx0_nicht_im_Stellgliedtest (CM_AB_Stellgliedtest_Cx0_nicht_im_Stellgliedtest), 1=Cx1_Airbag_im_Stellgliedtest (CM_AB_Stellgliedtest_Cx1_Airbag_im_Stellgliedtest)}, range raw 0..1, transfer-property=PENDING, to Klima(timeout 0.5 s)  # Information, ob Airbag im Stellgliedtest ist, um eine Notrufauflösung beim Stellgliedtest zu verhindern
          signal AB_Erh_Auf_VB_XIX_Airbag_01_XIX_E3V_EVCANFD: start 30, 2 bit, little-endian, data-type-policy=OVERRIDE, i-signal-type=PRIMITIVE, init-value=0, base-type=BT_AB_Erh_Auf_VB, compu {0=Cx0_keine_Anzeige (CM_AB_Erh_Auf_VB_Cx0_keine_Anzeige), 1=Cx1_Beifahrerairbag_deaktiviert (CM_AB_Erh_Auf_VB_Cx1_Beifahrerairbag_deaktiviert), 2=Cx2_Beifahrerairbag_aktiviert (CM_AB_Erh_Auf_VB_Cx2_Beifahrerairbag_aktiviert), 3=Cx3_nicht_definiert (CM_AB_Erh_Auf_VB_Cx3_nicht_definiert)}, range raw 0..3, transfer-property=PENDING  # Der Fahrer soll bei einem Statuswechsel des Beifahrerairbags (ausgelöst durch die Beifahrerinsassenerkennung oder den Schlüsselschloßschalter) aufmerksam gemacht werden durch eine Anzeige im Kombi. Nur Audi: gültig für: AB2 (4-Türer AU352), B7, C6, D3
          signal AB_Gurtwarn_VF_XIX_Airbag_01_XIX_E3V_EVCANFD: start 32, 1 bit, little-endian, data-type-policy=OVERRIDE, i-signal-type=PRIMITIVE, init-value=0, base-type=BT_AB_Gurtwarn_VF, compu {0=Cx0_keine_Warnung (CM_AB_Gurtwarn_VF_Cx0_keine_Warnung), 1=Cx1_Gurtwarnung_ausloesen (CM_AB_Gurtwarn_VF_Cx1_Gurtwarnung_ausloesen)}, range raw 0..1, transfer-property=PENDING  # Fahrer hat Gurt nicht gesteckt, Anzeige im Kombi
          signal AB_Gurtwarn_VB_XIX_Airbag_01_XIX_E3V_EVCANFD: start 33, 1 bit, little-endian, data-type-policy=OVERRIDE, i-signal-type=PRIMITIVE, init-value=0, base-type=BT_AB_Gurtwarn_VB, compu {0=Cx0_keine_Warnung (CM_AB_Gurtwarn_VB_Cx0_keine_Warnung), 1=Cx1_Gurtwarnung_ausloesen (CM_AB_Gurtwarn_VB_Cx1_Gurtwarnung_ausloesen)}, range raw 0..1, transfer-property=PENDING  # Beifahrer hat Gurt nicht gesteckt, Anzeige im Kombi
          signal AB_Anzeige_Fussg_XIX_Airbag_01_XIX_E3V_EVCANFD: start 34, 2 bit, little-endian, data-type-policy=OVERRIDE, i-signal-type=PRIMITIVE, init-value=0, base-type=BT_AB_Anzeige_Fussg, compu {0=Cx0_keine_FSG_Aktion_ausgeloest (CM_AB_Anzeige_Fussg_Cx0_keine_FSG_Aktion_ausgeloest), 1=Cx1_Motorhaube_offen (CM_AB_Anzeige_Fussg_Cx1_Motorhaube_offen), 2=Cx2_Systemfehler (CM_AB_Anzeige_Fussg_Cx2_Systemfehler)}, range raw 0..2, transfer-property=PENDING  # Anzeige für ausgelöste Fussgängerschutz-Aktuatorik
          signal AB_Texte_AKS_XIX_Airbag_01_XIX_E3V_EVCANFD: start 36, 2 bit, little-endian, data-type-policy=OVERRIDE, i-signal-type=PRIMITIVE, init-value=0, base-type=BT_AB_Texte_AKS, compu {0=Cx0_keine_AKS_Ausloesung (CM_AB_Texte_AKS_Cx0_keine_AKS_Ausloesung), 1=Cx1_AKS_ausgeloest (CM_AB_Texte_AKS_Cx1_AKS_ausgeloest), 2=Cx2_AKS_Systemfehler (CM_AB_Texte_AKS_Cx2_AKS_Systemfehler)}, range raw 0..2, transfer-property=PENDING  # Textanzeige für pyrotechnische Auslösung der aktiven Kopfstütze (AKS)
          signal AB_PAO_Leuchte_Anf_XIX_Airbag_01_XIX_E3V_EVCANFD: start 38, 1 bit, little-endian, data-type-policy=OVERRIDE, i-signal-type=PRIMITIVE, init-value=1, base-type=BT_AB_PAO_Leuchte_Anf, compu {0=Cx0_Leuchte_ausschalten (CM_AB_PAO_Leuchte_Anf_Cx0_Leuchte_ausschalten), 1=Cx1_Leuchte_einschalten (CM_AB_PAO_Leuchte_Anf_Cx1_Leuchte_einschalten)}, range raw 0..1, transfer-property=PENDING  # Anforderung an die Passenger-Airbag-Off Leuchte in der Dachkonsole (ein / aus), Einsatz nur bei PAG
          signal AB_MKB_gueltig_XIX_Airbag_01_XIX_E3V_EVCANFD: start 39, 1 bit, little-endian, data-type-policy=OVERRIDE, i-signal-type=PRIMITIVE, init-value=0, base-type=BT_AB_MKB_gueltig, compu {0=Cx0_Multikollisionsbremsung_nicht_freigeschaltet (CM_AB_MKB_gueltig_Cx0_Multikollisionsbremsung_nicht_freigeschaltet), 1=Cx1_Multikollisionsbremsung_freigeschaltet (CM_AB_MKB_gueltig_Cx1_Multikollisionsbremsung_freigeschaltet)}, range raw 0..1, transfer-property=PENDING  # Multi-Kollisions-Bremsung im Airbag freigeschaltet
          signal AB_MKB_Anforderung_XIX_Airbag_01_XIX_E3V_EVCANFD: start 40, 1 bit, little-endian, data-type-policy=OVERRIDE, i-signal-type=PRIMITIVE, init-value=0, base-type=BT_AB_MKB_Anforderung, compu {0=Cx0_Multikollisionsbremsung_nicht_angefordert (CM_AB_MKB_Anforderung_Cx0_Multikollisionsbremsung_nicht_angefordert), 1=Cx1_Multikollisionsbremsung_angefordert (CM_AB_MKB_Anforderung_Cx1_Multikollisionsbremsung_angefordert)}, range raw 0..1, transfer-property=TRIGGERED-ON-CHANGE  # Anforderung Multi-Kollisions-Bremsung
          signal AB_Versorgungsspannung_XIX_Airbag_01_XIX_E3V_EVCANFD: start 41, 1 bit, little-endian, data-type-policy=OVERRIDE, i-signal-type=PRIMITIVE, init-value=0, base-type=BT_AB_Versorgungsspannung, compu {0=Cx0_plausibel (CM_AB_Versorgungsspannung_Cx0_plausibel), 1=Cx1_unplausibel (CM_AB_Versorgungsspannung_Cx1_unplausibel)}, range raw 0..1, transfer-property=PENDING  # Übertragung der Plausibilitätsinformation Kl.15-Last vs. Kl.15-CAN. Bedienung im Fall Kl.15-Last "EIN" und Kl.15-CAN "AUS" mit Ausgabe Warnung/Akustik im Kombi.
          signal AB_Deaktivierung_HV_XIX_Airbag_01_XIX_E3V_EVCANFD: start 42, 3 bit, little-endian, data-type-policy=OVERRIDE, i-signal-type=PRIMITIVE, init-value=0, base-type=BT_AB_Deaktivierung_HV, invalid-value=Invalid_AB_Deaktivierung_HV_XIX_Airbag_01_XIX_E3V_EVCANFD:7, compu {0=Cx0_keine_Deaktivierung (CM_AB_Deaktivierung_HV_Cx0_keine_Deaktivierung), 1=Cx1_Deaktivierung_1 (CM_AB_Deaktivierung_HV_Cx1_Deaktivierung_1), 2=Cx2_Deaktivierung_2 (CM_AB_Deaktivierung_HV_Cx2_Deaktivierung_2), 3=Cx3_Deaktivierung_3 (CM_AB_Deaktivierung_HV_Cx3_Deaktivierung_3), 4=Cx4_Deaktivierung_4 (CM_AB_Deaktivierung_HV_Cx4_Deaktivierung_4), 5=Cx5_Deaktivierung_5 (CM_AB_Deaktivierung_HV_Cx5_Deaktivierung_5), 6=Cx6_Deaktivierung_6 (CM_AB_Deaktivierung_HV_Cx6_Deaktivierung_6), 7=Cx7_Fehler (CM_AB_Deaktivierung_HV_Cx7_Fehler)}, range raw 0..7, transfer-property=TRIGGERED-ON-CHANGE, to Klima(timeout 0.5 s)  # Deaktivierung des HV-Systems und der HV-Teilnehmer im Crash (u.a. Hybrid- und Elektrofahrzeuge)
          signal AB_EDR_Trigger_XIX_Airbag_01_XIX_E3V_EVCANFD: start 45, 2 bit, little-endian, data-type-policy=OVERRIDE, i-signal-type=PRIMITIVE, init-value=0, base-type=BT_AB_EDR_Trigger, compu {0=Cx0_No_Event (CM_AB_EDR_Trigger_Cx0_No_Event), 1=Cx1_Start_Event (CM_AB_EDR_Trigger_Cx1_Start_Event), 2=Cx2_NonDeployment_Event (CM_AB_EDR_Trigger_Cx2_NonDeployment_Event), 3=Cx3_Deployment_Event (CM_AB_EDR_Trigger_Cx3_Deployment_Event)}, range raw 0..3, transfer-property=TRIGGERED-ON-CHANGE-WITHOUT-REPETITION  # Triggerbedingung zur dezentralen Aufzeichnung unfallrelevanter Daten im Event Data Recorder
          signal AB_Belegung_VF_XIX_Airbag_01_XIX_E3V_EVCANFD: start 47, 2 bit, little-endian, data-type-policy=OVERRIDE, i-signal-type=PRIMITIVE, init-value=0, base-type=BT_AB_Belegung_VF, invalid-value=Invalid_AB_Belegung_VF_XIX_Airbag_01_XIX_E3V_EVCANFD:1, compu {0=Cx0_nicht_verfuegbar (CM_AB_Belegung_VF_Cx0_nicht_verfuegbar), 1=Cx1_Fehler (CM_AB_Belegung_VF_Cx1_Fehler), 2=Cx2_nicht_belegt (CM_AB_Belegung_VF_Cx2_nicht_belegt), 3=Cx3_belegt (CM_AB_Belegung_VF_Cx3_belegt)}, range raw 0..3, transfer-property=PENDING, to Klima(timeout 0.5 s)  # Belegungserkennung vorne Fahrer.
          signal AB_Gurtschloss_FA_ext_XIX_Airbag_01_XIX_E3V_EVCANFD: start 49, 3 bit, little-endian, data-type-policy=OVERRIDE, i-signal-type=PRIMITIVE, init-value=6, base-type=BT_AB_Gurtschloss_FA_ext, invalid-value=Invalid_AB_Gurtschloss_FA_ext_XIX_Airbag_01_XIX_E3V_EVCANFD:7, compu {0=Cx0_nicht_verbaut (CM_AB_Gurtschloss_FA_ext_Cx0_nicht_verbaut), 1=Cx1_reserviert (CM_AB_Gurtschloss_FA_ext_Cx1_reserviert), 2=Cx2_nicht_gesteckt (CM_AB_Gurtschloss_FA_ext_Cx2_nicht_gesteckt), 3=Cx3_gesteckt (CM_AB_Gurtschloss_FA_ext_Cx3_gesteckt), 4=Cx4_dauerhaft_nicht_gesteckt (CM_AB_Gurtschloss_FA_ext_Cx4_dauerhaft_nicht_gesteckt), 5=Cx5_dauerhaft_gesteckt (CM_AB_Gurtschloss_FA_ext_Cx5_dauerhaft_gesteckt), 6=Cx6_Init (CM_AB_Gurtschloss_FA_ext_Cx6_Init), 7=Cx7_Fehler (CM_AB_Gurtschloss_FA_ext_Cx7_Fehler)}, range raw 0..7, transfer-property=TRIGGERED-ON-CHANGE-WITHOUT-REPETITION  # Das Ergebnis der Basisfunktion "Plausibilisierung Gurtschloss" des Verlassenskonzepts wird im Signal dargestellt.
          signal AB_Gurtschloss_FA_ext_aktiv_XIX_Airbag_01_XIX_E3V_EVCANFD: start 52, 1 bit, little-endian, data-type-policy=OVERRIDE, i-signal-type=PRIMITIVE, init-value=0, base-type=BT_AB_Gurtschloss_FA_ext_aktiv, compu {0=Cx0_inaktiv (CM_AB_Gurtschloss_FA_ext_aktiv_Cx0_inaktiv), 1=Cx1_aktiv (CM_AB_Gurtschloss_FA_ext_aktiv_Cx1_aktiv)}, range raw 0..1, transfer-property=PENDING  # Über dieses Signal wird signalisiert ob die Erweiterte Gurtdiagnose (Ergebnis wird im Signal AB_Gurtschloss_FA_ext dargestellt) aktiviert oder deaktiviert ist.
          signal AB_eCS_Error_XIX_Airbag_01_XIX_E3V_EVCANFD: start 53, 1 bit, little-endian, data-type-policy=OVERRIDE, i-signal-type=PRIMITIVE, init-value=0, base-type=BT_AB_eCS_Error, compu {0=Cx0_keine_Anzeige (CM_AB_eCS_Error_Cx0_keine_Anzeige), 1=Cx1_Anzeige_anfordern (CM_AB_eCS_Error_Cx1_Anzeige_anfordern)}, range raw 0..1, transfer-property=PENDING  # Signal zur Anforderung der Anzeige von Störungen im System der elektrischen Gurtverriegelung
          signal AB_PSS_SollZustand_XIX_Airbag_01_XIX_E3V_EVCANFD: start 54, 1 bit, little-endian, data-type-policy=OVERRIDE, i-signal-type=PRIMITIVE, init-value=0, base-type=BT_AB_PSS_SollZustand, compu {0=Cx0_disabled (CM_AB_PSS_SollZustand_Cx0_disabled), 1=Cx1_enabled (CM_AB_PSS_SollZustand_Cx1_enabled)}, range raw 0..1, transfer-property=PENDING  # Erwartete Auslösefähigkeit
          signal ASM_Masterzeit_02_XIX_Airbag_01_XIX_E3V_EVCANFD: start 56, 8 bit, little-endian, data-type-policy=OVERRIDE, i-signal-type=PRIMITIVE, init-value=255, base-type=BT_ASM_Masterzeit_02, compu {phys=raw*0.04 for raw 0..254, 255=Cxff_Init (CM_ASM_Masterzeit_02_Cxff_Init); unit Unit_Secon}, range phys 0..10.16 Unit_Secon, raw 0..255, unit=Unit_Secon, transfer-property=PENDING  # Masterzeit für alle ASM Sender
      frame Airbag_02_XIX_E3V_EVCANFD: id 0x520, to Klima, frame-length=8, can-addressing-mode=STANDARD, can-frame-rx-behavior=CAN-FD, can-frame-tx-behavior=CAN-FD
        pdu Airbag_02_XIX_E3V_EVCANFD: length=8, minimum-delay=0.02, transmission-mode-true-timing={cyclic-timing={time-offset=0.0, time-period=0.2}, event-controlled-timing={number-of-repetitions=0, repetition-period=0.0}}, unused-bit-pattern=0
          signal Airbag_02_CRC_XIX_Airbag_02_XIX_E3V_EVCANFD: start 0, 8 bit, little-endian, data-type-policy=OVERRIDE, i-signal-type=PRIMITIVE, base-type=BT_Airbag_02_CRC, compu {phys=raw for raw 0..255}, range phys 0..255, raw 0..255, transfer-property=PENDING  # Für MLB: "Berechnung siehe Lastenheft "Kommunikationsabsicherung für FlexRay und CAN"" Ab MQB und MLBevo: "Berechnung siehe Lastenheft "End-to-End Kommunikationsabsicherung"" Endwerte siehe Begleitdokument "S-PDU Kennungsfolgen"
          signal Airbag_02_BZ_XIX_Airbag_02_XIX_E3V_EVCANFD: start 8, 4 bit, little-endian, data-type-policy=OVERRIDE, i-signal-type=PRIMITIVE, base-type=BT_Airbag_02_BZ, compu {phys=raw for raw 0..15}, range phys 0..15, raw 0..15, transfer-property=PENDING
          signal LoGeWa_Event_Kombiwarnung_XIX_Airbag_02_XIX_E3V_EVCANFD: start 12, 4 bit, little-endian, data-type-policy=OVERRIDE, i-signal-type=PRIMITIVE, init-value=0, base-type=BT_LoGeWa_Event_Kombiwarnung, compu {0=Cx0_Init (CM_LoGeWa_Event_Kombiwarnung_Cx0_Init), 1=Cx1_Unfall (CM_LoGeWa_Event_Kombiwarnung_Cx1_Unfall), 2=Cx2_Traktionsverlust (CM_LoGeWa_Event_Kombiwarnung_Cx2_Traktionsverlust), 3=Cx3_Panne (CM_LoGeWa_Event_Kombiwarnung_Cx3_Panne), 4=Cx4_Sichtbehinderung (CM_LoGeWa_Event_Kombiwarnung_Cx4_Sichtbehinderung), 5=Cx5_Aquaplaning (CM_LoGeWa_Event_Kombiwarnung_Cx5_Aquaplaning)}, range raw 0..5, transfer-property=TRIGGERED-ON-CHANGE-WITHOUT-REPETITION  # Event für Kombiwarnung
          signal AB_Anforderung_eCall_XIX_Airbag_02_XIX_E3V_EVCANFD: start 16, 1 bit, little-endian, data-type-policy=OVERRIDE, i-signal-type=PRIMITIVE, init-value=0, base-type=BT_AB_Anforderung_eCall, compu {0=Cx0_keine_Anforderung (CM_AB_Anforderung_eCall_Cx0_keine_Anforderung), 1=Cx1_Anforderung (CM_AB_Anforderung_eCall_Cx1_Anforderung)}, range raw 0..1, transfer-property=PENDING  # Trigger für Car2X Steuergerät das ein eCall Ereignis erkannt wurde.
          signal AB_Anprall_Seite_Beifahrer_XIX_Airbag_02_XIX_E3V_EVCANFD: start 17, 1 bit, little-endian, data-type-policy=OVERRIDE, i-signal-type=PRIMITIVE, init-value=0, base-type=BT_AB_Anprall_Seite_Beifahrer, compu {0=Cx0_kein_Anprall (CM_AB_Anprall_Seite_Beifahrer_Cx0_kein_Anprall), 1=Cx1_Anprall_erkannt (CM_AB_Anprall_Seite_Beifahrer_Cx1_Anprall_erkannt)}, range raw 0..1, transfer-property=TRIGGERED-ON-CHANGE-WITHOUT-REPETITION  # Uebermittlung der Lage einer Kollision, Anprallzone Beifahrerseite Seite
          signal AB_Anprall_FGS_XIX_Airbag_02_XIX_E3V_EVCANFD: start 19, 1 bit, little-endian, data-type-policy=OVERRIDE, i-signal-type=PRIMITIVE, init-value=0, base-type=BT_AB_Anprall_FGS, compu {0=Cx0_kein_Anprall (CM_AB_Anprall_FGS_Cx0_kein_Anprall), 1=Cx1_Anprall_erkannt (CM_AB_Anprall_FGS_Cx1_Anprall_erkannt)}, range raw 0..1, transfer-property=TRIGGERED-ON-CHANGE-WITHOUT-REPETITION  # Uebermittlung der Lage einer Kollision, Fussgaengerschutz-Aktorik
          signal AB_Anprall_Front_Beifahrer_XIX_Airbag_02_XIX_E3V_EVCANFD: start 20, 1 bit, little-endian, data-type-policy=OVERRIDE, i-signal-type=PRIMITIVE, init-value=0, base-type=BT_AB_Anprall_Front_Beifahrer, compu {0=Cx0_kein_Anprall (CM_AB_Anprall_Front_Beifahrer_Cx0_kein_Anprall), 1=Cx1_Anprall_erkannt (CM_AB_Anprall_Front_Beifahrer_Cx1_Anprall_erkannt)}, range raw 0..1, transfer-property=TRIGGERED-ON-CHANGE-WITHOUT-REPETITION  # Uebermittlung der Lage einer Kollision, Anprallzone Front Beifahrerseite
          signal AB_Anprall_Front_Fahrer_XIX_Airbag_02_XIX_E3V_EVCANFD: start 21, 1 bit, little-endian, data-type-policy=OVERRIDE, i-signal-type=PRIMITIVE, init-value=0, base-type=BT_AB_Anprall_Front_Fahrer, compu {0=Cx0_kein_Anprall (CM_AB_Anprall_Front_Fahrer_Cx0_kein_Anprall), 1=Cx1_Anprall_erkannt (CM_AB_Anprall_Front_Fahrer_Cx1_Anprall_erkannt)}, range raw 0..1, transfer-property=TRIGGERED-ON-CHANGE-WITHOUT-REPETITION  # Uebermittlung der Lage einer Kollision, Anprallzone Front Fahrerseite
          signal AB_Wickelklappung_Reihe2_MI_XIX_Airbag_02_XIX_E3V_EVCANFD: start 24, 2 bit, little-endian, data-type-policy=OVERRIDE, i-signal-type=PRIMITIVE, init-value=1, base-type=BT_AB_Wickelklappung_Reihe2_MI, compu {0=Cx0_nicht_verbaut (CM_AB_Wickelklappung_Reihe2_MI_Cx0_nicht_verbaut), 1=Cx1_nicht_verfuegbar_Fehler_oder_Init (CM_AB_Wickelklappung_Reihe2_MI_Cx1_nicht_verfuegbar_Fehler_oder_Init) (nicht_verfuegbar__Fehler_oder_Init), 2=Cx2_nicht_verriegelt (CM_AB_Wickelklappung_Reihe2_MI_Cx2_nicht_verriegelt), 3=Cx3_verriegelt (CM_AB_Wickelklappung_Reihe2_MI_Cx3_verriegelt)}, range raw 0..3, transfer-property=TRIGGERED-ON-CHANGE-WITHOUT-REPETITION  # Status Wickelklappung 2. Reihe Mitte, Mehrausstattung
          signal AB_Belegung_VB_XIX_Airbag_02_XIX_E3V_EVCANFD: start 26, 2 bit, little-endian, data-type-policy=OVERRIDE, i-signal-type=PRIMITIVE, init-value=0, base-type=BT_AB_Belegung_VB, invalid-value=Invalid_AB_Belegung_VB_XIX_Airbag_02_XIX_E3V_EVCANFD:1, compu {0=Cx0_nicht_verfuegbar (CM_AB_Belegung_VB_Cx0_nicht_verfuegbar), 1=Cx1_Fehler (CM_AB_Belegung_VB_Cx1_Fehler), 2=Cx2_nicht_belegt (CM_AB_Belegung_VB_Cx2_nicht_belegt), 3=Cx3_belegt (CM_AB_Belegung_VB_Cx3_belegt)}, range raw 0..3, transfer-property=PENDING, to Klima(timeout 2 s)  # Belegungserkennung vorne Beifahrer. Wird in US-Steuergeräten über Bladder-Matte bedient, optional bei RdW, falls SBE_EuroNCAP entschieden wird.
          signal AB_Abschaltanf_SIH_BF_XIX_Airbag_02_XIX_E3V_EVCANFD: start 28, 1 bit, little-endian, data-type-policy=OVERRIDE, i-signal-type=PRIMITIVE, init-value=0, base-type=BT_AB_Abschaltanf_SIH_BF, compu {0=Cx0_Normalbetrieb (CM_AB_Abschaltanf_SIH_BF_Cx0_Normalbetrieb), 1=Cx1_Abschaltung_angefordert (CM_AB_Abschaltanf_SIH_BF_Cx1_Abschaltung_angefordert)}, range raw 0..1, transfer-property=TRIGGERED-ON-CHANGE-WITHOUT-REPETITION, to Klima(timeout 2 s)  # Die Insassenerkennung auf der Beifahrerseite fordert bei Übertemperatur eine Abschaltung der Sitzheizung an. Die Übertemperatur kann bei niederohmigen Nebenschlüssen der Sitzheizungsmatte als Folge von zu hohem resultierenden Strom auftreten.
          signal AB_Anprall_Seite_Fahrer_XIX_Airbag_02_XIX_E3V_EVCANFD: start 29, 1 bit, little-endian, data-type-policy=OVERRIDE, i-signal-type=PRIMITIVE, init-value=0, base-type=BT_AB_Anprall_Seite_Fahrer, compu {0=Cx0_kein_Anprall (CM_AB_Anprall_Seite_Fahrer_Cx0_kein_Anprall), 1=Cx1_Anprall_erkannt (CM_AB_Anprall_Seite_Fahrer_Cx1_Anprall_erkannt)}, range raw 0..1, transfer-property=TRIGGERED-ON-CHANGE-WITHOUT-REPETITION  # Uebermittlung der Lage einer Kollision, Anprallzone Fahrerseite Seite
          signal SC_PAO_Schriftzug_Anf_XIX_Airbag_02_XIX_E3V_EVCANFD: start 30, 2 bit, little-endian, data-type-policy=OVERRIDE, i-signal-type=PRIMITIVE, init-value=0, base-type=BT_SC_PAO_Schriftzug_Anf, compu {0=Cx0_LED_aus (CM_SC_PAO_Schriftzug_Anf_Cx0_LED_aus) (LED aus), 1=Cx1_LED_an (CM_SC_PAO_Schriftzug_Anf_Cx1_LED_an) (LED an), 2=Cx2_LED_blinken (CM_SC_PAO_Schriftzug_Anf_Cx2_LED_blinken) (LED blinken), 3=Cx3_reserviert (CM_SC_PAO_Schriftzug_Anf_Cx3_reserviert)}, range raw 0..3, transfer-property=TRIGGERED-ON-CHANGE-WITHOUT-REPETITION  # Sollwert für LED "PASSENGER AIRBAG" in Anzeige Passenger Airbag On/Off
          signal SC_PAO_ON_Anf_XIX_Airbag_02_XIX_E3V_EVCANFD: start 32, 2 bit, little-endian, data-type-policy=OVERRIDE, i-signal-type=PRIMITIVE, init-value=0, base-type=BT_SC_PAO_ON_Anf, compu {0=Cx0_LED_aus (CM_SC_PAO_ON_Anf_Cx0_LED_aus) (LED aus), 1=Cx1_LED_an (CM_SC_PAO_ON_Anf_Cx1_LED_an) (LED an), 2=Cx2_LED_blinken (CM_SC_PAO_ON_Anf_Cx2_LED_blinken) (LED blinken), 3=Cx3_reserviert (CM_SC_PAO_ON_Anf_Cx3_reserviert)}, range raw 0..3, transfer-property=TRIGGERED-ON-CHANGE-WITHOUT-REPETITION  # Sollwert für LED "ON" in Anzeige Passenger Airbag On/Off
          signal SC_PAO_OFF_Anf_XIX_Airbag_02_XIX_E3V_EVCANFD: start 34, 2 bit, little-endian, data-type-policy=OVERRIDE, i-signal-type=PRIMITIVE, init-value=0, base-type=BT_SC_PAO_OFF_Anf, compu {0=Cx0_LED_aus (CM_SC_PAO_OFF_Anf_Cx0_LED_aus) (LED aus), 1=Cx1_LED_an (CM_SC_PAO_OFF_Anf_Cx1_LED_an) (LED an), 2=Cx2_LED_blinken (CM_SC_PAO_OFF_Anf_Cx2_LED_blinken) (LED blinken), 3=Cx3_reserviert (CM_SC_PAO_OFF_Anf_Cx3_reserviert)}, range raw 0..3, transfer-property=TRIGGERED-ON-CHANGE-WITHOUT-REPETITION  # Sollwert für LED "OFF" in Anzeige Passenger Airbag On/Off
          signal AB_Crashschwere_XIX_Airbag_02_XIX_E3V_EVCANFD: start 36, 3 bit, little-endian, data-type-policy=OVERRIDE, i-signal-type=PRIMITIVE, init-value=0, base-type=BT_AB_Crashschwere, invalid-value=Invalid_AB_Crashschwere_XIX_Airbag_02_XIX_E3V_EVCANFD:7, compu {0=Cx0_kein_Ereignis (CM_AB_Crashschwere_Cx0_kein_Ereignis), 1=Cx1_Crashschwere_1 (CM_AB_Crashschwere_Cx1_Crashschwere_1), 2=Cx2_Crashschwere_2 (CM_AB_Crashschwere_Cx2_Crashschwere_2), 3=Cx3_Crashschwere_3 (CM_AB_Crashschwere_Cx3_Crashschwere_3), 4=Cx4_Crashschwere_4 (CM_AB_Crashschwere_Cx4_Crashschwere_4), 5=Cx5_Crashschwere_5 (CM_AB_Crashschwere_Cx5_Crashschwere_5), 6=Cx6_Crashschwere_2_bis_5 (CM_AB_Crashschwere_Cx6_Crashschwere_2_bis_5), 7=Cx7_Fehler (CM_AB_Crashschwere_Cx7_Fehler)}, range raw 0..7, transfer-property=TRIGGERED-ON-CHANGE-WITHOUT-REPETITION  # Übermittlung der Crashschwere an das Gateway (OBDC)
          signal AB_Anforderung_USM_XIX_Airbag_02_XIX_E3V_EVCANFD: start 39, 1 bit, little-endian, data-type-policy=OVERRIDE, i-signal-type=PRIMITIVE, init-value=0, base-type=BT_AB_Anforderung_USM, compu {0=Cx0_keine_Anforderung (CM_AB_Anforderung_USM_Cx0_keine_Anforderung), 1=Cx1_Anforderung (CM_AB_Anforderung_USM_Cx1_Anforderung)}, range raw 0..1, transfer-property=PENDING  # Trigger für Gateway (OBDC) und MIB/MMI, dass ein USM-Ereignis erkannt wurde.
          signal AB_Gurtschloss_FA_XIX_Airbag_02_XIX_E3V_EVCANFD: start 40, 2 bit, little-endian, data-type-policy=OVERRIDE, i-signal-type=PRIMITIVE, init-value=1, base-type=BT_AB_Gurtschloss_FA, compu {0=Cx0_nicht_verbaut (CM_AB_Gurtschloss_FA_Cx0_nicht_verbaut), 1=Cx1_nicht_verfuegbar_Fehler_oder_Init (CM_AB_Gurtschloss_FA_Cx1_nicht_verfuegbar_Fehler_oder_Init) (nicht_verfügbar (Fehler oder Init)), 2=Cx2_nicht_gesteckt (CM_AB_Gurtschloss_FA_Cx2_nicht_gesteckt), 3=Cx3_gesteckt (CM_AB_Gurtschloss_FA_Cx3_gesteckt)}, range raw 0..3, transfer-property=TRIGGERED-ON-CHANGE-WITHOUT-REPETITION, to Klima(timeout 2 s)  # Gurtschlosstatatus Fahrerseite
          signal AB_Gurtschloss_BF_XIX_Airbag_02_XIX_E3V_EVCANFD: start 42, 2 bit, little-endian, data-type-policy=OVERRIDE, i-signal-type=PRIMITIVE, init-value=1, base-type=BT_AB_Gurtschloss_BF, compu {0=Cx0_nicht_verbaut (CM_AB_Gurtschloss_BF_Cx0_nicht_verbaut), 1=Cx1_nicht_verfuegbar_Fehler_oder_Init (CM_AB_Gurtschloss_BF_Cx1_nicht_verfuegbar_Fehler_oder_Init) (nicht_verfügbar (Fehler oder Init)), 2=Cx2_nicht_gesteckt (CM_AB_Gurtschloss_BF_Cx2_nicht_gesteckt), 3=Cx3_gesteckt (CM_AB_Gurtschloss_BF_Cx3_gesteckt)}, range raw 0..3, transfer-property=TRIGGERED-ON-CHANGE-WITHOUT-REPETITION, to Klima(timeout 2 s)  # Gurtschlossstatus Beifahrerseite
          signal AB_Gurtschloss_Reihe2_FA_XIX_Airbag_02_XIX_E3V_EVCANFD: start 44, 2 bit, little-endian, data-type-policy=OVERRIDE, i-signal-type=PRIMITIVE, init-value=1, base-type=BT_AB_Gurtschloss_Reihe2_FA, compu {0=Cx0_nicht_verbaut (CM_AB_Gurtschloss_Reihe2_FA_Cx0_nicht_verbaut), 1=Cx1_nicht_verfuegbar_Fehler_oder_Init (CM_AB_Gurtschloss_Reihe2_FA_Cx1_nicht_verfuegbar_Fehler_oder_Init) (nicht_verfügbar (Fehler oder Init)), 2=Cx2_nicht_gesteckt (CM_AB_Gurtschloss_Reihe2_FA_Cx2_nicht_gesteckt), 3=Cx3_gesteckt (CM_AB_Gurtschloss_Reihe2_FA_Cx3_gesteckt)}, range raw 0..3, transfer-property=TRIGGERED-ON-CHANGE-WITHOUT-REPETITION, to Klima(timeout 2 s)  # Gurtschlossstatus 2. Reihe Fahrerseite, Mehrausstattung
          signal AB_Gurtschloss_Reihe2_MI_XIX_Airbag_02_XIX_E3V_EVCANFD: start 46, 2 bit, little-endian, data-type-policy=OVERRIDE, i-signal-type=PRIMITIVE, init-value=1, base-type=BT_AB_Gurtschloss_Reihe2_MI, compu {0=Cx0_nicht_verbaut (CM_AB_Gurtschloss_Reihe2_MI_Cx0_nicht_verbaut), 1=Cx1_nicht_verfuegbar_Fehler_oder_Init (CM_AB_Gurtschloss_Reihe2_MI_Cx1_nicht_verfuegbar_Fehler_oder_Init) (nicht_verfügbar (Fehler oder Init)), 2=Cx2_nicht_gesteckt (CM_AB_Gurtschloss_Reihe2_MI_Cx2_nicht_gesteckt), 3=Cx3_gesteckt (CM_AB_Gurtschloss_Reihe2_MI_Cx3_gesteckt)}, range raw 0..3, transfer-property=TRIGGERED-ON-CHANGE-WITHOUT-REPETITION, to Klima(timeout 2 s)  # Gurtschlossstatus 2. Reihe Mitte, Mehrausstattung
          signal AB_Gurtschloss_Reihe2_BF_XIX_Airbag_02_XIX_E3V_EVCANFD: start 48, 2 bit, little-endian, data-type-policy=OVERRIDE, i-signal-type=PRIMITIVE, init-value=1, base-type=BT_AB_Gurtschloss_Reihe2_BF, compu {0=Cx0_nicht_verbaut (CM_AB_Gurtschloss_Reihe2_BF_Cx0_nicht_verbaut), 1=Cx1_nicht_verfuegbar_Fehler_oder_Init (CM_AB_Gurtschloss_Reihe2_BF_Cx1_nicht_verfuegbar_Fehler_oder_Init) (nicht_verfügbar (Fehler oder Init)), 2=Cx2_nicht_gesteckt (CM_AB_Gurtschloss_Reihe2_BF_Cx2_nicht_gesteckt), 3=Cx3_gesteckt (CM_AB_Gurtschloss_Reihe2_BF_Cx3_gesteckt)}, range raw 0..3, transfer-property=TRIGGERED-ON-CHANGE-WITHOUT-REPETITION, to Klima(timeout 2 s)  # Gurtschlossstatus 2. Reihe Beifahrerseite, Mehrausstattung
          signal AB_Gurtschloss_Reihe3_FA_XIX_Airbag_02_XIX_E3V_EVCANFD: start 50, 2 bit, little-endian, data-type-policy=OVERRIDE, i-signal-type=PRIMITIVE, init-value=1, base-type=BT_AB_Gurtschloss_Reihe3_FA, compu {0=Cx0_nicht_verbaut (CM_AB_Gurtschloss_Reihe3_FA_Cx0_nicht_verbaut), 1=Cx1_nicht_verfuegbar_Fehler_oder_Init (CM_AB_Gurtschloss_Reihe3_FA_Cx1_nicht_verfuegbar_Fehler_oder_Init) (nicht_verfügbar (Fehler oder Init)), 2=Cx2_nicht_gesteckt (CM_AB_Gurtschloss_Reihe3_FA_Cx2_nicht_gesteckt), 3=Cx3_gesteckt (CM_AB_Gurtschloss_Reihe3_FA_Cx3_gesteckt)}, range raw 0..3, transfer-property=TRIGGERED-ON-CHANGE-WITHOUT-REPETITION, to Klima(timeout 2 s)  # Gurtschlossstatus 3. Reihe Fahrerseite, Mehrausstattung
          signal AB_Gurtschloss_Reihe3_MI_XIX_Airbag_02_XIX_E3V_EVCANFD: start 52, 2 bit, little-endian, data-type-policy=OVERRIDE, i-signal-type=PRIMITIVE, init-value=1, base-type=BT_AB_Gurtschloss_Reihe3_MI, compu {0=Cx0_nicht_verbaut (CM_AB_Gurtschloss_Reihe3_MI_Cx0_nicht_verbaut), 1=Cx1_nicht_verfuegbar_Fehler_oder_Init (CM_AB_Gurtschloss_Reihe3_MI_Cx1_nicht_verfuegbar_Fehler_oder_Init) (nicht_verfügbar (Fehler oder Init)), 2=Cx2_nicht_gesteckt (CM_AB_Gurtschloss_Reihe3_MI_Cx2_nicht_gesteckt), 3=Cx3_gesteckt (CM_AB_Gurtschloss_Reihe3_MI_Cx3_gesteckt)}, range raw 0..3, transfer-property=TRIGGERED-ON-CHANGE-WITHOUT-REPETITION, to Klima(timeout 2 s)  # Gurtschlossstatus 3. Reihe Mitte, Mehrausstattung
          signal AB_Gurtschloss_Reihe3_BF_XIX_Airbag_02_XIX_E3V_EVCANFD: start 54, 2 bit, little-endian, data-type-policy=OVERRIDE, i-signal-type=PRIMITIVE, init-value=1, base-type=BT_AB_Gurtschloss_Reihe3_BF, compu {0=Cx0_nicht_verbaut (CM_AB_Gurtschloss_Reihe3_BF_Cx0_nicht_verbaut), 1=Cx1_nicht_verfuegbar_Fehler_oder_Init (CM_AB_Gurtschloss_Reihe3_BF_Cx1_nicht_verfuegbar_Fehler_oder_Init) (nicht_verfügbar (Fehler oder Init)), 2=Cx2_nicht_gesteckt (CM_AB_Gurtschloss_Reihe3_BF_Cx2_nicht_gesteckt), 3=Cx3_gesteckt (CM_AB_Gurtschloss_Reihe3_BF_Cx3_gesteckt)}, range raw 0..3, transfer-property=TRIGGERED-ON-CHANGE-WITHOUT-REPETITION, to Klima(timeout 2 s)  # Gurtschlossstatus 3. Reihe Beifahrerseite, Mehrausstattung
          signal AB_Sitzpos_Sens_FA_XIX_Airbag_02_XIX_E3V_EVCANFD: start 56, 2 bit, little-endian, data-type-policy=OVERRIDE, i-signal-type=PRIMITIVE, init-value=0, base-type=BT_AB_Sitzpos_Sens_FA, invalid-value=Invalid_AB_Sitzpos_Sens_FA_XIX_Airbag_02_XIX_E3V_EVCANFD:1, compu {0=Cx0_nicht_verfuegbar (CM_AB_Sitzpos_Sens_FA_Cx0_nicht_verfuegbar), 1=Cx1_Fehler (CM_AB_Sitzpos_Sens_FA_Cx1_Fehler), 2=Cx2_Sitz_nicht_vorne (CM_AB_Sitzpos_Sens_FA_Cx2_Sitz_nicht_vorne), 3=Cx3_Sitz_vorne (CM_AB_Sitzpos_Sens_FA_Cx3_Sitz_vorne)}, range raw 0..3, transfer-property=PENDING  # Ausgabe Sitzposition Fahrer
          signal AB_Sitzpos_Sens_BF_XIX_Airbag_02_XIX_E3V_EVCANFD: start 58, 2 bit, little-endian, data-type-policy=OVERRIDE, i-signal-type=PRIMITIVE, init-value=0, base-type=BT_AB_Sitzpos_Sens_BF, invalid-value=Invalid_AB_Sitzpos_Sens_BF_XIX_Airbag_02_XIX_E3V_EVCANFD:1, compu {0=Cx0_nicht_verfuegbar (CM_AB_Sitzpos_Sens_BF_Cx0_nicht_verfuegbar), 1=Cx1_Fehler (CM_AB_Sitzpos_Sens_BF_Cx1_Fehler), 2=Cx2_Sitz_nicht_vorne (CM_AB_Sitzpos_Sens_BF_Cx2_Sitz_nicht_vorne), 3=Cx3_Sitz_vorne (CM_AB_Sitzpos_Sens_BF_Cx3_Sitz_vorne)}, range raw 0..3, transfer-property=PENDING  # Ausgabe Sitzposition Beifahrer
          signal AB_Wickelklappung_Reihe2_BF_XIX_Airbag_02_XIX_E3V_EVCANFD: start 60, 2 bit, little-endian, data-type-policy=OVERRIDE, i-signal-type=PRIMITIVE, init-value=1, base-type=BT_AB_Wickelklappung_Reihe2_BF, compu {0=Cx0_nicht_verbaut (CM_AB_Wickelklappung_Reihe2_BF_Cx0_nicht_verbaut), 1=Cx1_nicht_verfuegbar_Fehler_oder_Init (CM_AB_Wickelklappung_Reihe2_BF_Cx1_nicht_verfuegbar_Fehler_oder_Init) (nicht_verfuegbar__Fehler_oder_Init), 2=Cx2_nicht_verriegelt (CM_AB_Wickelklappung_Reihe2_BF_Cx2_nicht_verriegelt), 3=Cx3_verriegelt (CM_AB_Wickelklappung_Reihe2_BF_Cx3_verriegelt)}, range raw 0..3, transfer-property=TRIGGERED-ON-CHANGE-WITHOUT-REPETITION  # Status Wickelklappung 2. Reihe Beifahrerseite, Mehrausstattung
          signal AB_Wickelklappung_Reihe2_FA_XIX_Airbag_02_XIX_E3V_EVCANFD: start 62, 2 bit, little-endian, data-type-policy=OVERRIDE, i-signal-type=PRIMITIVE, init-value=1, base-type=BT_AB_Wickelklappung_Reihe2_FA, compu {0=Cx0_nicht_verbaut (CM_AB_Wickelklappung_Reihe2_FA_Cx0_nicht_verbaut), 1=Cx1_nicht_verfuegbar_Fehler_oder_Init (CM_AB_Wickelklappung_Reihe2_FA_Cx1_nicht_verfuegbar_Fehler_oder_Init) (nicht_verfuegbar__Fehler_oder_Init), 2=Cx2_nicht_verriegelt (CM_AB_Wickelklappung_Reihe2_FA_Cx2_nicht_verriegelt), 3=Cx3_verriegelt (CM_AB_Wickelklappung_Reihe2_FA_Cx3_verriegelt)}, range raw 0..3, transfer-property=TRIGGERED-ON-CHANGE-WITHOUT-REPETITION  # Status Wickelklappung 2. Reihe Fahrerseite, Mehrausstattung
      frame Airbag_04_XIX_E3V_EVCANFD: id 0x545, to Klima, frame-length=8, can-addressing-mode=STANDARD, can-frame-rx-behavior=CAN-FD, can-frame-tx-behavior=CAN-FD
        pdu Airbag_04_XIX_E3V_EVCANFD: length=8, minimum-delay=0.04, transmission-mode-true-timing={cyclic-timing={time-offset=0.0, time-period=0.2}, event-controlled-timing={number-of-repetitions=0, repetition-period=0.0}}, unused-bit-pattern=0
          signal Airbag_04_CRC_XIX_Airbag_04_XIX_E3V_EVCANFD: start 0, 8 bit, little-endian, data-type-policy=OVERRIDE, i-signal-type=PRIMITIVE, base-type=BT_Airbag_04_CRC, compu {phys=raw for raw 0..255}, range phys 0..255, raw 0..255, transfer-property=PENDING  # Für MLB: Berechnung siehe Lastenheft "Kommunikationsabsicherung für FlexRay und CAN" Ab MQB und MLBevo: Berechnung siehe Lastenheft "End-to-End Kommunikationsabsicherung" Endwerte siehe Begleitdokument "S-PDU Kennungsfolgen"
          signal Airbag_04_BZ_XIX_Airbag_04_XIX_E3V_EVCANFD: start 8, 4 bit, little-endian, data-type-policy=OVERRIDE, i-signal-type=PRIMITIVE, base-type=BT_Airbag_04_BZ, compu {phys=raw for raw 0..15}, range phys 0..15, raw 0..15, transfer-property=PENDING  # 4bit Botschaftszähler, wird mit jeder Sendebotschaft inkrementiert
          signal AB_Anprall_Heck_XIX_Airbag_04_XIX_E3V_EVCANFD: start 13, 1 bit, little-endian, data-type-policy=OVERRIDE, i-signal-type=PRIMITIVE, init-value=0, base-type=BT_AB_Anprall_Heck, compu {0=Cx0_kein_Anprall (CM_AB_Anprall_Heck_Cx0_kein_Anprall), 1=Cx1_Anprall_erkannt (CM_AB_Anprall_Heck_Cx1_Anprall_erkannt)}, range raw 0..1, transfer-property=TRIGGERED-ON-CHANGE-WITHOUT-REPETITION  # Uebermittlung der Lage einer Kollision, Anprallzone Heck
          signal AB_Gurtwarn_Reihe4_FA_XIX_Airbag_04_XIX_E3V_EVCANFD: start 14, 2 bit, little-endian, data-type-policy=OVERRIDE, i-signal-type=PRIMITIVE, init-value=0, base-type=BT_AB_Gurtwarn_Reihe4_FA, compu {0=Cx0_nicht_verbaut (CM_AB_Gurtwarn_Reihe4_FA_Cx0_nicht_verbaut), 1=Cx1_keine_Gurtwarnung_Sitz_leer (CM_AB_Gurtwarn_Reihe4_FA_Cx1_keine_Gurtwarnung_Sitz_leer), 2=Cx2_keine_Gurtwarnung_Sitz_belegt (CM_AB_Gurtwarn_Reihe4_FA_Cx2_keine_Gurtwarnung_Sitz_belegt), 3=Cx3_Gurtwarnung_Sitz_belegt (CM_AB_Gurtwarn_Reihe4_FA_Cx3_Gurtwarnung_Sitz_belegt)}, range raw 0..3, transfer-property=PENDING  # Status Gurtwarnung 4. Sitzreihe Fahrerseite
          signal AB_Gurtwarn_Reihe4_BF_XIX_Airbag_04_XIX_E3V_EVCANFD: start 16, 2 bit, little-endian, data-type-policy=OVERRIDE, i-signal-type=PRIMITIVE, init-value=0, base-type=BT_AB_Gurtwarn_Reihe4_BF, compu {0=Cx0_nicht_verbaut (CM_AB_Gurtwarn_Reihe4_BF_Cx0_nicht_verbaut), 1=Cx1_keine_Gurtwarnung_Sitz_leer (CM_AB_Gurtwarn_Reihe4_BF_Cx1_keine_Gurtwarnung_Sitz_leer), 2=Cx2_keine_Gurtwarnung_Sitz_belegt (CM_AB_Gurtwarn_Reihe4_BF_Cx2_keine_Gurtwarnung_Sitz_belegt), 3=Cx3_Gurtwarnung_Sitz_belegt (CM_AB_Gurtwarn_Reihe4_BF_Cx3_Gurtwarnung_Sitz_belegt)}, range raw 0..3, transfer-property=PENDING  # Status Gurtwarnung 4. Sitzreihe Beifahrerseite
          signal AB_Gurtwarn_Reihe4_MI_XIX_Airbag_04_XIX_E3V_EVCANFD: start 18, 2 bit, little-endian, data-type-policy=OVERRIDE, i-signal-type=PRIMITIVE, init-value=0, base-type=BT_AB_Gurtwarn_Reihe4_MI, compu {0=Cx0_nicht_verbaut (CM_AB_Gurtwarn_Reihe4_MI_Cx0_nicht_verbaut), 1=Cx1_keine_Gurtwarnung_Sitz_leer (CM_AB_Gurtwarn_Reihe4_MI_Cx1_keine_Gurtwarnung_Sitz_leer), 2=Cx2_keine_Gurtwarnung_Sitz_belegt (CM_AB_Gurtwarn_Reihe4_MI_Cx2_keine_Gurtwarnung_Sitz_belegt), 3=Cx3_Gurtwarnung_Sitz_belegt (CM_AB_Gurtwarn_Reihe4_MI_Cx3_Gurtwarnung_Sitz_belegt)}, range raw 0..3, transfer-property=PENDING  # Status Gurtwarnung 4. Sitzreihe Mitte
          signal AB_Gurtwarn_Reihe2_FA_XIX_Airbag_04_XIX_E3V_EVCANFD: start 20, 2 bit, little-endian, data-type-policy=OVERRIDE, i-signal-type=PRIMITIVE, init-value=0, base-type=BT_AB_Gurtwarn_Reihe2_FA, compu {0=Cx0_nicht_verbaut (CM_AB_Gurtwarn_Reihe2_FA_Cx0_nicht_verbaut), 1=Cx1_keine_Gurtwarnung_Sitz_leer (CM_AB_Gurtwarn_Reihe2_FA_Cx1_keine_Gurtwarnung_Sitz_leer), 2=Cx2_keine_Gurtwarnung_Sitz_belegt (CM_AB_Gurtwarn_Reihe2_FA_Cx2_keine_Gurtwarnung_Sitz_belegt), 3=Cx3_Gurtwarnung_Sitz_belegt (CM_AB_Gurtwarn_Reihe2_FA_Cx3_Gurtwarnung_Sitz_belegt)}, range raw 0..3, transfer-property=PENDING, to Klima(timeout 2 s)  # Status Gurtwarnung 2. Sitzreihe Fahrerseite
          signal AB_Gurtwarn_Reihe2_BF_XIX_Airbag_04_XIX_E3V_EVCANFD: start 22, 2 bit, little-endian, data-type-policy=OVERRIDE, i-signal-type=PRIMITIVE, init-value=0, base-type=BT_AB_Gurtwarn_Reihe2_BF, compu {0=Cx0_nicht_verbaut (CM_AB_Gurtwarn_Reihe2_BF_Cx0_nicht_verbaut), 1=Cx1_keine_Gurtwarnung_Sitz_leer (CM_AB_Gurtwarn_Reihe2_BF_Cx1_keine_Gurtwarnung_Sitz_leer), 2=Cx2_keine_Gurtwarnung_Sitz_belegt (CM_AB_Gurtwarn_Reihe2_BF_Cx2_keine_Gurtwarnung_Sitz_belegt), 3=Cx3_Gurtwarnung_Sitz_belegt (CM_AB_Gurtwarn_Reihe2_BF_Cx3_Gurtwarnung_Sitz_belegt)}, range raw 0..3, transfer-property=PENDING, to Klima(timeout 2 s)  # Status Gurtwarnung 2. Sitzreihe Beifahrerseite
          signal AbstWarn_MV_FAS_Fkt_Status_XIX_Airbag_04_XIX_E3V_EVCANFD: start 24, 2 bit, little-endian, data-type-policy=OVERRIDE, i-signal-type=PRIMITIVE, init-value=0, base-type=BT_AbstWarn_MV_FAS_Fkt_Status, invalid-value=Invalid_AbstWarn_MV_FAS_Fkt_Status_XIX_Airbag_04_XIX_E3V_EVCANFD:3, compu {0=Cx0_Init (CM_AbstWarn_MV_FAS_Fkt_Status_Cx0_Init), 1=Cx1_Funktion_Ist_Ein (CM_AbstWarn_MV_FAS_Fkt_Status_Cx1_Funktion_Ist_Ein), 2=Cx2_Funktion_Ist_Aus (CM_AbstWarn_MV_FAS_Fkt_Status_Cx2_Funktion_Ist_Aus), 3=Cx3_Fehler (CM_AbstWarn_MV_FAS_Fkt_Status_Cx3_Fehler)}, range raw 0..3, transfer-property=TRIGGERED-ON-CHANGE-WITHOUT-REPETITION  # FAS-ProfileMaster Iststatus der Kundenfunktion
          signal WarnBrems_Charisma_Status_XIX_Airbag_04_XIX_E3V_EVCANFD: start 26, 2 bit, little-endian, data-type-policy=OVERRIDE, i-signal-type=PRIMITIVE, init-value=0, base-type=BT_WarnBrems_Charisma_Status, compu {0=Cx0_Init (CM_WarnBrems_Charisma_Status_Cx0_Init), 1=Cx1_verfuegbar (CM_WarnBrems_Charisma_Status_Cx1_verfuegbar) (verfügbar), 2=Cx2_nicht_verfuegbar (CM_WarnBrems_Charisma_Status_Cx2_nicht_verfuegbar) (nicht verfügbar), 3=Cx3_asynchron_durch_Fahrerwunsch (CM_WarnBrems_Charisma_Status_Cx3_asynchron_durch_Fahrerwunsch) (asynchron durch Fahrerwunsch)}, range raw 0..3, transfer-property=PENDING  # Verfügbarkeit der Funktion Warn- und/oder Notbremsfunktion für die Ansteuerung durch den Charisma-Koordinator.
          signal WarnBrems_Charisma_FahrPr_XIX_Airbag_04_XIX_E3V_EVCANFD: start 28, 4 bit, little-endian, data-type-policy=OVERRIDE, i-signal-type=PRIMITIVE, init-value=0, base-type=BT_WarnBrems_Charisma_FahrPr, compu {0=Cx0_keine_Funktion (CM_WarnBrems_Charisma_FahrPr_Cx0_keine_Funktion), 1=Cx1_Programm_1 (CM_WarnBrems_Charisma_FahrPr_Cx1_Programm_1), 2=Cx2_Programm_2 (CM_WarnBrems_Charisma_FahrPr_Cx2_Programm_2), 3=Cx3_Programm_3 (CM_WarnBrems_Charisma_FahrPr_Cx3_Programm_3), 4=Cx4_Programm_4 (CM_WarnBrems_Charisma_FahrPr_Cx4_Programm_4), 5=Cx5_Programm_5 (CM_WarnBrems_Charisma_FahrPr_Cx5_Programm_5), 6=Cx6_Programm_6 (CM_WarnBrems_Charisma_FahrPr_Cx6_Programm_6), 7=Cx7_Programm_7 (CM_WarnBrems_Charisma_FahrPr_Cx7_Programm_7), 8=Cx8_Programm_8 (CM_WarnBrems_Charisma_FahrPr_Cx8_Programm_8), 9=Cx9_Programm_9 (CM_WarnBrems_Charisma_FahrPr_Cx9_Programm_9), 10=Cxa_Programm_10 (CM_WarnBrems_Charisma_FahrPr_Cxa_Programm_10), 11=Cxb_Programm_11 (CM_WarnBrems_Charisma_FahrPr_Cxb_Programm_11), 12=Cxc_Programm_12 (CM_WarnBrems_Charisma_FahrPr_Cxc_Programm_12), 13=Cxd_Programm_13 (CM_WarnBrems_Charisma_FahrPr_Cxd_Programm_13), 14=Cxe_Programm_14 (CM_WarnBrems_Charisma_FahrPr_Cxe_Programm_14), 15=Cxf_Programm_15 (CM_WarnBrems_Charisma_FahrPr_Cxf_Programm_15)}, range raw 0..15, transfer-property=PENDING  # Aktuell eingestelltes Fahrprogramm der Funktion Warn- und/oder Notbremsfunktion
          signal AB_Gurtwarn_Reihe2_MI_XIX_Airbag_04_XIX_E3V_EVCANFD: start 32, 2 bit, little-endian, data-type-policy=OVERRIDE, i-signal-type=PRIMITIVE, init-value=0, base-type=BT_AB_Gurtwarn_Reihe2_MI, compu {0=Cx0_nicht_verbaut (CM_AB_Gurtwarn_Reihe2_MI_Cx0_nicht_verbaut), 1=Cx1_keine_Gurtwarnung_Sitz_leer (CM_AB_Gurtwarn_Reihe2_MI_Cx1_keine_Gurtwarnung_Sitz_leer), 2=Cx2_keine_Gurtwarnung_Sitz_belegt (CM_AB_Gurtwarn_Reihe2_MI_Cx2_keine_Gurtwarnung_Sitz_belegt), 3=Cx3_Gurtwarnung_Sitz_belegt (CM_AB_Gurtwarn_Reihe2_MI_Cx3_Gurtwarnung_Sitz_belegt)}, range raw 0..3, transfer-property=PENDING, to Klima(timeout 2 s)  # Status Gurtwarnung 2. Sitzreihe Mitte
          signal AB_Gurtwarn_Reihe3_FA_XIX_Airbag_04_XIX_E3V_EVCANFD: start 34, 2 bit, little-endian, data-type-policy=OVERRIDE, i-signal-type=PRIMITIVE, init-value=0, base-type=BT_AB_Gurtwarn_Reihe3_FA, compu {0=Cx0_nicht_verbaut (CM_AB_Gurtwarn_Reihe3_FA_Cx0_nicht_verbaut), 1=Cx1_keine_Gurtwarnung_Sitz_leer (CM_AB_Gurtwarn_Reihe3_FA_Cx1_keine_Gurtwarnung_Sitz_leer), 2=Cx2_keine_Gurtwarnung_Sitz_belegt (CM_AB_Gurtwarn_Reihe3_FA_Cx2_keine_Gurtwarnung_Sitz_belegt), 3=Cx3_Gurtwarnung_Sitz_belegt (CM_AB_Gurtwarn_Reihe3_FA_Cx3_Gurtwarnung_Sitz_belegt)}, range raw 0..3, transfer-property=PENDING, to Klima(timeout 2 s)  # Status Gurtwarnung 3. Sitzreihe Fahrerseite
          signal AB_Gurtwarn_Reihe3_MI_XIX_Airbag_04_XIX_E3V_EVCANFD: start 36, 2 bit, little-endian, data-type-policy=OVERRIDE, i-signal-type=PRIMITIVE, init-value=0, base-type=BT_AB_Gurtwarn_Reihe3_MI, compu {0=Cx0_nicht_verbaut (CM_AB_Gurtwarn_Reihe3_MI_Cx0_nicht_verbaut), 1=Cx1_keine_Gurtwarnung_Sitz_leer (CM_AB_Gurtwarn_Reihe3_MI_Cx1_keine_Gurtwarnung_Sitz_leer), 2=Cx2_keine_Gurtwarnung_Sitz_belegt (CM_AB_Gurtwarn_Reihe3_MI_Cx2_keine_Gurtwarnung_Sitz_belegt), 3=Cx3_Gurtwarnung_Sitz_belegt (CM_AB_Gurtwarn_Reihe3_MI_Cx3_Gurtwarnung_Sitz_belegt)}, range raw 0..3, transfer-property=PENDING, to Klima(timeout 2 s)  # Status Gurtwarnung 3. Sitzreihe Mitte
          signal AB_Gurtwarn_Reihe3_BF_XIX_Airbag_04_XIX_E3V_EVCANFD: start 38, 2 bit, little-endian, data-type-policy=OVERRIDE, i-signal-type=PRIMITIVE, init-value=0, base-type=BT_AB_Gurtwarn_Reihe3_BF, compu {0=Cx0_nicht_verbaut (CM_AB_Gurtwarn_Reihe3_BF_Cx0_nicht_verbaut), 1=Cx1_keine_Gurtwarnung_Sitz_leer (CM_AB_Gurtwarn_Reihe3_BF_Cx1_keine_Gurtwarnung_Sitz_leer), 2=Cx2_keine_Gurtwarnung_Sitz_belegt (CM_AB_Gurtwarn_Reihe3_BF_Cx2_keine_Gurtwarnung_Sitz_belegt), 3=Cx3_Gurtwarnung_Sitz_belegt (CM_AB_Gurtwarn_Reihe3_BF_Cx3_Gurtwarnung_Sitz_belegt)}, range raw 0..3, transfer-property=PENDING, to Klima(timeout 2 s)  # Status Gurtwarnung 3. Sitzreihe Beifahrerseite
          signal LGI_FAS_Fkt_Status_XIX_Airbag_04_XIX_E3V_EVCANFD: start 40, 2 bit, little-endian, data-type-policy=OVERRIDE, i-signal-type=PRIMITIVE, init-value=0, base-type=BT_LGI_FAS_Fkt_Status, invalid-value=Invalid_LGI_FAS_Fkt_Status_XIX_Airbag_04_XIX_E3V_EVCANFD:3, compu {0=Cx0_Init (CM_LGI_FAS_Fkt_Status_Cx0_Init), 1=Cx1_Funktion_Ist_Ein (CM_LGI_FAS_Fkt_Status_Cx1_Funktion_Ist_Ein), 2=Cx2_Funktion_Ist_Aus (CM_LGI_FAS_Fkt_Status_Cx2_Funktion_Ist_Aus), 3=Cx3_Fehler (CM_LGI_FAS_Fkt_Status_Cx3_Fehler)}, range raw 0..3, transfer-property=TRIGGERED-ON-CHANGE-WITHOUT-REPETITION  # FAS-ProfileMaster Iststatus der Kundenfunktion (LGI: Lokale Gefahreninformation)
          signal PreCrash_FAS_Fkt_Status_XIX_Airbag_04_XIX_E3V_EVCANFD: start 42, 3 bit, little-endian, data-type-policy=OVERRIDE, i-signal-type=PRIMITIVE, init-value=0, base-type=BT_PreCrash_FAS_Fkt_Status, invalid-value=Invalid_PreCrash_FAS_Fkt_Status_XIX_Airbag_04_XIX_E3V_EVCANFD:3, compu {0=Cx0_Init (CM_PreCrash_FAS_Fkt_Status_Cx0_Init), 1=Cx1_Funktion_Ist_Ein (CM_PreCrash_FAS_Fkt_Status_Cx1_Funktion_Ist_Ein), 2=Cx2_Funktion_Ist_Aus (CM_PreCrash_FAS_Fkt_Status_Cx2_Funktion_Ist_Aus), 3=Cx3_Fehler (CM_PreCrash_FAS_Fkt_Status_Cx3_Fehler)}, range raw 0..3, transfer-property=TRIGGERED-ON-CHANGE-WITHOUT-REPETITION  # FAS-ProfileMaster Iststatus der Kundenfunktion
          signal AB_Belegung_VF_ext_XIX_Airbag_04_XIX_E3V_EVCANFD: start 45, 3 bit, little-endian, data-type-policy=OVERRIDE, i-signal-type=PRIMITIVE, init-value=6, base-type=BT_AB_Belegung_VF_ext, invalid-value=Invalid_AB_Belegung_VF_ext_XIX_Airbag_04_XIX_E3V_EVCANFD:7, compu {0=Cx0_nicht_verbaut (CM_AB_Belegung_VF_ext_Cx0_nicht_verbaut), 1=Cx1_reserviert (CM_AB_Belegung_VF_ext_Cx1_reserviert), 2=Cx2_nicht_belegt (CM_AB_Belegung_VF_ext_Cx2_nicht_belegt), 3=Cx3_belegt (CM_AB_Belegung_VF_ext_Cx3_belegt), 4=Cx4_dauerhaft_nicht_belegt (CM_AB_Belegung_VF_ext_Cx4_dauerhaft_nicht_belegt), 5=Cx5_dauerhaft_belegt (CM_AB_Belegung_VF_ext_Cx5_dauerhaft_belegt), 6=Cx6_Init (CM_AB_Belegung_VF_ext_Cx6_Init), 7=Cx7_Fehler (CM_AB_Belegung_VF_ext_Cx7_Fehler)}, range raw 0..7, transfer-property=TRIGGERED-ON-CHANGE-WITHOUT-REPETITION, to Klima(timeout 2 s)  # Das Signal kommuniziert den Status des Sitzbelegsensors Fahrer incl. dauerhafter Zustände mit Signalqualität ASIL A.
          signal AB_SBR_hinten_verbau_XIX_Airbag_04_XIX_E3V_EVCANFD: start 48, 2 bit, little-endian, data-type-policy=OVERRIDE, i-signal-type=PRIMITIVE, init-value=3, base-type=BT_AB_SBR_hinten_verbau, compu {0=Cx0_ohne_SBR_hinten (CM_AB_SBR_hinten_verbau_Cx0_ohne_SBR_hinten), 1=Cx1_mit_SBR_hinten (CM_AB_SBR_hinten_verbau_Cx1_mit_SBR_hinten), 2=Cx2_nicht_definiert (CM_AB_SBR_hinten_verbau_Cx2_nicht_definiert), 3=Cx3_Init (CM_AB_SBR_hinten_verbau_Cx3_Init)}, range raw 0..3, transfer-property=PENDING, to Klima(timeout 2 s)  # Verbauinformation Sitzbelegungssensor hinten (2. und 3. Sitzreihe)
          signal AB_Belegung_VF_ext_aktiv_XIX_Airbag_04_XIX_E3V_EVCANFD: start 50, 1 bit, little-endian, data-type-policy=OVERRIDE, i-signal-type=PRIMITIVE, init-value=0, base-type=BT_AB_Belegung_VF_ext_aktiv, compu {0=Cx0_inaktiv (CM_AB_Belegung_VF_ext_aktiv_Cx0_inaktiv), 1=Cx1_aktiv (CM_AB_Belegung_VF_ext_aktiv_Cx1_aktiv)}, range raw 0..1, transfer-property=TRIGGERED-ON-CHANGE-WITHOUT-REPETITION  # Kennzeichnet aktive Funktion "Erweiterte Sitzbelegdiagnose" für Signal AB_Belegung_VF_ext
          signal AWV_Einstellung_System_ASG_XIX_Airbag_04_XIX_E3V_EVCANFD: start 51, 1 bit, little-endian, data-type-policy=OVERRIDE, i-signal-type=PRIMITIVE, init-value=0, base-type=BT_AWV_Einstellung_System_ASG, compu {0=Cx0_deaktiviert (CM_AWV_Einstellung_System_ASG_Cx0_deaktiviert), 1=Cx1_aktiviert (CM_AWV_Einstellung_System_ASG_Cx1_aktiviert)}, range raw 0..1, transfer-property=TRIGGERED-ON-CHANGE-WITHOUT-REPETITION  # Signal zur Realisierung des BAP-Koordinators
          signal AWV_Einstellung_Warnung_ASG_XIX_Airbag_04_XIX_E3V_EVCANFD: start 52, 3 bit, little-endian, data-type-policy=OVERRIDE, i-signal-type=PRIMITIVE, init-value=0, base-type=BT_AWV_Einstellung_Warnung_ASG, compu {0=Cx0_Aus (CM_AWV_Einstellung_Warnung_ASG_Cx0_Aus), 1=Cx1_Setting_2 (CM_AWV_Einstellung_Warnung_ASG_Cx1_Setting_2), 2=Cx2_Setting_3 (CM_AWV_Einstellung_Warnung_ASG_Cx2_Setting_3), 3=Cx3_Setting_4 (CM_AWV_Einstellung_Warnung_ASG_Cx3_Setting_4), 4=Cx4_Setting_5 (CM_AWV_Einstellung_Warnung_ASG_Cx4_Setting_5), 5=Cx5_Ein (CM_AWV_Einstellung_Warnung_ASG_Cx5_Ein)}, range raw 0..5, transfer-property=TRIGGERED-ON-CHANGE-WITHOUT-REPETITION  # Signal zur Realisierung des BAP-Koordinators
          signal SC_PreSense_Modus_Warnung_NV_XIX_Airbag_04_XIX_E3V_EVCANFD: start 55, 3 bit, little-endian, data-type-policy=OVERRIDE, i-signal-type=PRIMITIVE, init-value=0, base-type=BT_SC_PreSense_Modus_Warnung_NV, compu {0=Cx0_Aus (CM_SC_PreSense_Modus_Warnung_NV_Cx0_Aus), 1=Cx1_Setting_2 (CM_SC_PreSense_Modus_Warnung_NV_Cx1_Setting_2), 2=Cx2_Setting_3 (CM_SC_PreSense_Modus_Warnung_NV_Cx2_Setting_3), 3=Cx3_Setting_4 (CM_SC_PreSense_Modus_Warnung_NV_Cx3_Setting_4), 4=Cx4_Setting_5 (CM_SC_PreSense_Modus_Warnung_NV_Cx4_Setting_5), 5=Cx5_Ein (CM_SC_PreSense_Modus_Warnung_NV_Cx5_Ein)}, range raw 0..5, transfer-property=TRIGGERED-ON-CHANGE-WITHOUT-REPETITION  # Signal zur Realisierung der BAP-Kommunikation für PreSense
          signal SC_PreSense_Modus_Warnung_MV_XIX_Airbag_04_XIX_E3V_EVCANFD: start 58, 3 bit, little-endian, data-type-policy=OVERRIDE, i-signal-type=PRIMITIVE, init-value=0, base-type=BT_SC_PreSense_Modus_Warnung_MV, compu {0=Cx0_Aus (CM_SC_PreSense_Modus_Warnung_MV_Cx0_Aus), 1=Cx1_Setting_2 (CM_SC_PreSense_Modus_Warnung_MV_Cx1_Setting_2), 2=Cx2_Setting_3 (CM_SC_PreSense_Modus_Warnung_MV_Cx2_Setting_3), 3=Cx3_Setting_4 (CM_SC_PreSense_Modus_Warnung_MV_Cx3_Setting_4), 4=Cx4_Setting_5 (CM_SC_PreSense_Modus_Warnung_MV_Cx4_Setting_5), 5=Cx5_Ein (CM_SC_PreSense_Modus_Warnung_MV_Cx5_Ein)}, range raw 0..5, transfer-property=TRIGGERED-ON-CHANGE-WITHOUT-REPETITION  # Signal zur Realisierung der BAP-Kommunikation für PreSense
          signal SC_PreSense_Modus_System_MV_XIX_Airbag_04_XIX_E3V_EVCANFD: start 61, 1 bit, little-endian, data-type-policy=OVERRIDE, i-signal-type=PRIMITIVE, init-value=0, base-type=BT_SC_PreSense_Modus_System_MV, compu {0=Cx0_deaktiviert (CM_SC_PreSense_Modus_System_MV_Cx0_deaktiviert), 1=Cx1_aktiviert (CM_SC_PreSense_Modus_System_MV_Cx1_aktiviert)}, range raw 0..1, transfer-property=TRIGGERED-ON-CHANGE-WITHOUT-REPETITION  # Signal zur Realisierung der BAP-Kommunikation für PreSense
          signal SC_PreSense_Modus_System_NV_XIX_Airbag_04_XIX_E3V_EVCANFD: start 62, 1 bit, little-endian, data-type-policy=OVERRIDE, i-signal-type=PRIMITIVE, init-value=0, base-type=BT_SC_PreSense_Modus_System_NV, compu {0=Cx0_deaktiviert (CM_SC_PreSense_Modus_System_NV_Cx0_deaktiviert), 1=Cx1_aktiviert (CM_SC_PreSense_Modus_System_NV_Cx1_aktiviert)}, range raw 0..1, transfer-property=TRIGGERED-ON-CHANGE-WITHOUT-REPETITION  # Signal zur Realisierung der BAP-Kommunikation für PreSense
          signal SC_PreSense_Modus_System_KAS_XIX_Airbag_04_XIX_E3V_EVCANFD: start 63, 1 bit, little-endian, data-type-policy=OVERRIDE, i-signal-type=PRIMITIVE, init-value=0, base-type=BT_SC_PreSense_Modus_System_KAS, compu {0=Cx0_deaktiviert (CM_SC_PreSense_Modus_System_KAS_Cx0_deaktiviert), 1=Cx1_aktiviert (CM_SC_PreSense_Modus_System_KAS_Cx1_aktiviert)}, range raw 0..1, transfer-property=TRIGGERED-ON-CHANGE-WITHOUT-REPETITION  # BAP-Kommunikation zum Kreuzungsassistent
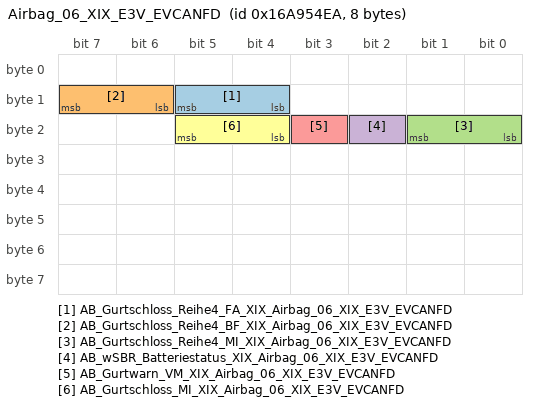
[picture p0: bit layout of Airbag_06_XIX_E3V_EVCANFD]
      frame Airbag_06_XIX_E3V_EVCANFD: id 0x16A954EA, to Klima, frame-length=8, can-addressing-mode=EXTENDED, can-frame-rx-behavior=CAN-FD, can-frame-tx-behavior=CAN-FD
        pdu Airbag_06_XIX_E3V_EVCANFD: length=8, transmission-mode-true-timing=cyclic-timing={time-offset=0, time-period=0.2}, unused-bit-pattern=0
          signal AB_Gurtschloss_Reihe4_FA_XIX_Airbag_06_XIX_E3V_EVCANFD: start 12, 2 bit, little-endian, data-type-policy=OVERRIDE, i-signal-type=PRIMITIVE, init-value=1, base-type=BT_AB_Gurtschloss_Reihe4_FA, compu {0=Cx0_nicht_verbaut (CM_AB_Gurtschloss_Reihe4_FA_Cx0_nicht_verbaut), 1=Cx1_nicht_verfuegbar_Fehler_oder_Init (CM_AB_Gurtschloss_Reihe4_FA_Cx1_nicht_verfuegbar_Fehler_oder_Init) (nicht_verfügbar (Fehler oder Init)), 2=Cx2_nicht_gesteckt (CM_AB_Gurtschloss_Reihe4_FA_Cx2_nicht_gesteckt), 3=Cx3_gesteckt (CM_AB_Gurtschloss_Reihe4_FA_Cx3_gesteckt)}, range raw 0..3, transfer-property=PENDING  # Gurtschlossstatus 4. Reihe Fahrerseite, Mehrausstattung
          signal AB_Gurtschloss_Reihe4_BF_XIX_Airbag_06_XIX_E3V_EVCANFD: start 14, 2 bit, little-endian, data-type-policy=OVERRIDE, i-signal-type=PRIMITIVE, init-value=1, base-type=BT_AB_Gurtschloss_Reihe4_BF, compu {0=Cx0_nicht_verbaut (CM_AB_Gurtschloss_Reihe4_BF_Cx0_nicht_verbaut), 1=Cx1_nicht_verfuegbar_Fehler_oder_Init (CM_AB_Gurtschloss_Reihe4_BF_Cx1_nicht_verfuegbar_Fehler_oder_Init) (nicht_verfügbar (Fehler oder Init)), 2=Cx2_nicht_gesteckt (CM_AB_Gurtschloss_Reihe4_BF_Cx2_nicht_gesteckt), 3=Cx3_gesteckt (CM_AB_Gurtschloss_Reihe4_BF_Cx3_gesteckt)}, range raw 0..3, transfer-property=PENDING  # Gurtschlossstatus 4. Reihe Beifahrerseite, Mehrausstattung
          signal AB_Gurtschloss_Reihe4_MI_XIX_Airbag_06_XIX_E3V_EVCANFD: start 16, 2 bit, little-endian, data-type-policy=OVERRIDE, i-signal-type=PRIMITIVE, init-value=1, base-type=BT_AB_Gurtschloss_Reihe4_MI, compu {0=Cx0_nicht_verbaut (CM_AB_Gurtschloss_Reihe4_MI_Cx0_nicht_verbaut), 1=Cx1_nicht_verfuegbar_Fehler_oder_Init (CM_AB_Gurtschloss_Reihe4_MI_Cx1_nicht_verfuegbar_Fehler_oder_Init) (nicht_verfügbar (Fehler oder Init)), 2=Cx2_nicht_gesteckt (CM_AB_Gurtschloss_Reihe4_MI_Cx2_nicht_gesteckt), 3=Cx3_gesteckt (CM_AB_Gurtschloss_Reihe4_MI_Cx3_gesteckt)}, range raw 0..3, transfer-property=PENDING  # Gurtschlossstatus 4. Reihe Mitte, Mehrausstattung
          signal AB_wSBR_Batteriestatus_XIX_Airbag_06_XIX_E3V_EVCANFD: start 18, 1 bit, little-endian, data-type-policy=OVERRIDE, i-signal-type=PRIMITIVE, init-value=0, base-type=BT_AB_wSBR_Batteriestatus, compu {0=Cx0_Batterien_OK (CM_AB_wSBR_Batteriestatus_Cx0_Batterien_OK), 1=Cx1_mindestens_eine_Batterie_schwach (CM_AB_wSBR_Batteriestatus_Cx1_mindestens_eine_Batterie_schwach)}, range raw 0..1, transfer-property=PENDING  # Anzeige einer schwachen Batterie in einer Sitzeinheit des wSBR-Systems im Kombi.
          signal AB_Gurtwarn_VM_XIX_Airbag_06_XIX_E3V_EVCANFD: start 19, 1 bit, little-endian, data-type-policy=OVERRIDE, i-signal-type=PRIMITIVE, init-value=0, base-type=BT_AB_Gurtwarn_VM, compu {0=Cx0_keine_Warnung (CM_AB_Gurtwarn_VM_Cx0_keine_Warnung), 1=Cx1_Gurtwarnung_ausloesen (CM_AB_Gurtwarn_VM_Cx1_Gurtwarnung_ausloesen)}, range raw 0..1, transfer-property=PENDING, to Klima(timeout 2 s)  # Beifahrer auf mittlerem Sitz (Nutzfahrzeug) hat Gurt nicht gesteckt, Anzeige im Kombi
          signal AB_Gurtschloss_MI_XIX_Airbag_06_XIX_E3V_EVCANFD: start 20, 2 bit, little-endian, data-type-policy=OVERRIDE, i-signal-type=PRIMITIVE, init-value=1, base-type=BT_AB_Gurtschloss_MI, compu {0=Cx0_nicht_verbaut (CM_AB_Gurtschloss_MI_Cx0_nicht_verbaut), 1=Cx1_nicht_verfuegbar_Fehler_oder_Init (CM_AB_Gurtschloss_MI_Cx1_nicht_verfuegbar_Fehler_oder_Init) (nicht_verfügbar (Fehler oder Init)), 2=Cx2_nicht_gesteckt (CM_AB_Gurtschloss_MI_Cx2_nicht_gesteckt), 3=Cx3_gesteckt (CM_AB_Gurtschloss_MI_Cx3_gesteckt)}, range raw 0..3, transfer-property=PENDING, to Klima(timeout 2 s)  # Gurtschloss-Status 1. Reihe Mitte Ersteinsetzer: T6PA
      frame BAP_Debug_Cmd_XIX_E3V_EVCANFD: id 0x1733FF20, to Klima, frame-length=8, can-addressing-mode=EXTENDED, can-frame-rx-behavior=CAN-FD, can-frame-tx-behavior=CAN-FD
        user defined pdu CDD_BAP_Debug_Cmd_XIX_E3V_EVCANFD: length=8, cdd-type=BAP
      frame BAP_Debug_Data_XIX_E3V_EVCANFD: id 0x1733FF30, from Klima, frame-length=8, can-addressing-mode=EXTENDED, can-frame-rx-behavior=CAN-FD, can-frame-tx-behavior=CAN-FD
        user defined pdu CDD_BAP_Debug_Data_XIX_E3V_EVCANFD: length=8, cdd-type=BAP
      frame BAP_Klima1_ASG_01_XIX_E3V_EVCANFD: id 0x17330100, to Klima, frame-length=8, can-addressing-mode=EXTENDED, can-frame-rx-behavior=CAN-FD, can-frame-tx-behavior=CAN-FD
        user defined pdu CDD_BAP_Klima1_ASG_01_XIX_E3V_EVCANFD: length=8, cdd-type=BAP
      frame BAP_Klima1_FSG_01_XIX_E3V_EVCANFD: id 0x17330110, from Klima, frame-length=8, can-addressing-mode=EXTENDED, can-frame-rx-behavior=CAN-FD, can-frame-tx-behavior=CAN-FD
        user defined pdu CDD_BAP_Klima1_FSG_01_XIX_E3V_EVCANFD: length=8, cdd-type=BAP
      frame BAP_Klima2_ASG_01_XIX_E3V_EVCANFD: id 0x17330200, to Klima, frame-length=8, can-addressing-mode=EXTENDED, can-frame-rx-behavior=CAN-FD, can-frame-tx-behavior=CAN-FD
        user defined pdu CDD_BAP_Klima2_ASG_01_XIX_E3V_EVCANFD: length=8, cdd-type=BAP
      frame BAP_Klima2_FSG_01_XIX_E3V_EVCANFD: id 0x17330210, from Klima, frame-length=8, can-addressing-mode=EXTENDED, can-frame-rx-behavior=CAN-FD, can-frame-tx-behavior=CAN-FD
        user defined pdu CDD_BAP_Klima2_FSG_01_XIX_E3V_EVCANFD: length=8, cdd-type=BAP
      frame BAP_KlimaMaster_ASG_01_XIX_E3V_EVCANFD: id 0x17334200, to Klima, frame-length=8, can-addressing-mode=EXTENDED, can-frame-rx-behavior=CAN-FD, can-frame-tx-behavior=CAN-FD
        user defined pdu CDD_BAP_KlimaMaster_ASG_01_XIX_E3V_EVCANFD: length=8, cdd-type=BAP
      frame BAP_KlimaMaster_ASG_02_XIX_E3V_EVCANFD: id 0x17334201, to Klima, frame-length=8, can-addressing-mode=EXTENDED, can-frame-rx-behavior=CAN-FD, can-frame-tx-behavior=CAN-FD
        user defined pdu CDD_BAP_KlimaMaster_ASG_02_XIX_E3V_EVCANFD: length=8, cdd-type=BAP
      frame BAP_KlimaMaster_FSG_01_XIX_E3V_EVCANFD: id 0x17334210, from Klima, frame-length=8, can-addressing-mode=EXTENDED, can-frame-rx-behavior=CAN-FD, can-frame-tx-behavior=CAN-FD
        user defined pdu CDD_BAP_KlimaMaster_FSG_01_XIX_E3V_EVCANFD: length=8, cdd-type=BAP
      frame BAP_Uhrzeit_ASG_02_XIX_E3V_EVCANFD: id 0x17331101, from Klima, frame-length=8, can-addressing-mode=EXTENDED, can-frame-rx-behavior=CAN-FD, can-frame-tx-behavior=CAN-FD
        user defined pdu CDD_BAP_Uhrzeit_ASG_02_XIX_E3V_EVCANFD: length=8, cdd-type=BAP
      frame BCM_01_XIX_E3V_EVCANFD: id 0x65A, to Klima, frame-length=8, can-addressing-mode=STANDARD, can-frame-rx-behavior=CAN-FD, can-frame-tx-behavior=CAN-FD
        pdu BCM_01_XIX_E3V_EVCANFD: length=8, minimum-delay=0.03, transmission-mode-true-timing={cyclic-timing={time-offset=0.0, time-period=1.0}, event-controlled-timing={number-of-repetitions=5, repetition-period=0.1}}, unused-bit-pattern=0
          signal BCM_01_CRC_XIX_BCM_01_XIX_E3V_EVCANFD: start 0, 8 bit, little-endian, data-type-policy=OVERRIDE, i-signal-type=PRIMITIVE, base-type=BT_BCM_01_CRC, compu {phys=raw for raw 0..255}, range phys 0..255, raw 0..255, transfer-property=PENDING  # Für MLB: "Berechnung siehe Lastenheft "Kommunikationsabsicherung für FlexRay und CAN"" Ab MQB und MLBevo: "Berechnung siehe Lastenheft "End-to-End Kommunikationsabsicherung"" Endwerte siehe Begleitdokument "S-PDU Kennungsfolgen"
          signal BCM_01_BZ_XIX_BCM_01_XIX_E3V_EVCANFD: start 8, 4 bit, little-endian, data-type-policy=OVERRIDE, i-signal-type=PRIMITIVE, base-type=BT_BCM_01_BZ, compu {phys=raw for raw 0..15}, range phys 0..15, raw 0..15, transfer-property=PENDING  # 4bit Botschaftszaehler; wird in jeder Sendebotschaft inkrementiert
          signal BCM_Bremsbelag_Sensor_XIX_BCM_01_XIX_E3V_EVCANFD: start 12, 1 bit, little-endian, data-type-policy=OVERRIDE, i-signal-type=PRIMITIVE, init-value=0, base-type=BT_BCM_Bremsbelag_Sensor, compu {0=Cx0_OK (CM_BCM_Bremsbelag_Sensor_Cx0_OK), 1=Cx1_Bremsbelag_unter_min (CM_BCM_Bremsbelag_Sensor_Cx1_Bremsbelag_unter_min)}, range raw 0..1, transfer-property=TRIGGERED-ON-CHANGE-WITHOUT-REPETITION  # Sensorsignal der Stromschleife für Bremsbelagverschleiß aktuell, entstört, unbewertet
          signal BCM_Bremsfluessigkeit_Sensor_XIX_BCM_01_XIX_E3V_EVCANFD: start 13, 1 bit, little-endian, data-type-policy=OVERRIDE, i-signal-type=PRIMITIVE, init-value=0, base-type=BT_BCM_Bremsfluessigkeit_Sensor, compu {0=Cx0_OK (CM_BCM_Bremsfluessigkeit_Sensor_Cx0_OK), 1=Cx1_Bremsfluessigkeit_unter_min (CM_BCM_Bremsfluessigkeit_Sensor_Cx1_Bremsfluessigkeit_unter_min)}, range raw 0..1, transfer-property=TRIGGERED-ON-CHANGE-WITHOUT-REPETITION  # Kontaktsignal des Sensorschalters für die Bremsflüssigkeitsreserve aktuell, entstört, unbewertet
          signal BCM_Waschwasser_Sensor_XIX_BCM_01_XIX_E3V_EVCANFD: start 15, 1 bit, little-endian, data-type-policy=OVERRIDE, i-signal-type=PRIMITIVE, init-value=0, base-type=BT_BCM_Waschwasser_Sensor, compu {0=Cx0_OK (CM_BCM_Waschwasser_Sensor_Cx0_OK), 1=Cx1_Waschwasser_unter_min (CM_BCM_Waschwasser_Sensor_Cx1_Waschwasser_unter_min)}, range raw 0..1, transfer-property=TRIGGERED-ON-CHANGE-WITHOUT-REPETITION  # Signal der Sensorelektroden für die Waschwasserreserve aktuell, entstört, bewertet (OK/Mangel)
          signal BCM_Kuehlmittel_Sensor_XIX_BCM_01_XIX_E3V_EVCANFD: start 16, 1 bit, little-endian, data-type-policy=OVERRIDE, i-signal-type=PRIMITIVE, init-value=0, base-type=BT_BCM_Kuehlmittel_Sensor, compu {0=Cx0_OK (CM_BCM_Kuehlmittel_Sensor_Cx0_OK), 1=Cx1_Kuehlmittel_unter_min (CM_BCM_Kuehlmittel_Sensor_Cx1_Kuehlmittel_unter_min)}, range raw 0..1, transfer-property=TRIGGERED-ON-CHANGE-WITHOUT-REPETITION  # Signal der Sensorelektroden für die Kühlmittelreserve aktuell, entstört, bewertet (OK/Mangel)
          signal BCM1_Kl_15_HW_erkannt_XIX_BCM_01_XIX_E3V_EVCANFD: start 17, 1 bit, little-endian, data-type-policy=OVERRIDE, i-signal-type=PRIMITIVE, init-value=0, base-type=BT_BCM1_Kl_15_HW_erkannt, compu {1=Cx1_Klemme_15_erkannt (CM_BCM1_Kl_15_HW_erkannt_Cx1_Klemme_15_erkannt) (Klemme 15 erkannt)}, range raw 1, transfer-property=TRIGGERED-ON-CHANGE-WITHOUT-REPETITION  # Erkennung Klemme 15 (Hardware) vom BCM1
          signal BCM1_Kl_15_Sig_HW_erkannt_XIX_BCM_01_XIX_E3V_EVCANFD: start 18, 1 bit, little-endian, data-type-policy=OVERRIDE, i-signal-type=PRIMITIVE, init-value=0, base-type=BT_BCM1_Kl_15_Sig_HW_erkannt, compu {0=Cx0_KL15_HW_Signal_von_BCM1_nicht_erkannt (CM_BCM1_Kl_15_Sig_HW_erkannt_Cx0_KL15_HW_Signal_von_BCM1_nicht_erkannt), 1=Cx1_KL15_HW_Signal_von_BCM1_erkannt (CM_BCM1_Kl_15_Sig_HW_erkannt_Cx1_KL15_HW_Signal_von_BCM1_erkannt)}, range raw 0..1, transfer-property=TRIGGERED-ON-CHANGE-WITHOUT-REPETITION  # Erkennung Klemme 15 Signal (Hardware) vom BCM1
          signal BCM_Kuehlmittel_Sensor_02_XIX_BCM_01_XIX_E3V_EVCANFD: start 19, 1 bit, little-endian, data-type-policy=OVERRIDE, i-signal-type=PRIMITIVE, init-value=0, base-type=BT_BCM_Kuehlmittel_Sensor_02, compu {0=Cx0_OK (CM_BCM_Kuehlmittel_Sensor_02_Cx0_OK), 1=Cx1_Kuehlmittel_unter_min (CM_BCM_Kuehlmittel_Sensor_02_Cx1_Kuehlmittel_unter_min)}, range raw 0..1, transfer-property=TRIGGERED-ON-CHANGE-WITHOUT-REPETITION  # Signal der zweiten Sensorelektroden für die Kühlmittelreserve aktuell, entstört, bewertet (OK/Mangel)
          signal BCM_Offroad_Taste_XIX_BCM_01_XIX_E3V_EVCANFD: start 21, 1 bit, little-endian, data-type-policy=OVERRIDE, i-signal-type=PRIMITIVE, init-value=0, base-type=BT_BCM_Offroad_Taste, compu {0=Cx0_Taster_nicht_betaetigt (CM_BCM_Offroad_Taste_Cx0_Taster_nicht_betaetigt), 1=Cx1_Taster_betaetigt (CM_BCM_Offroad_Taste_Cx1_Taster_betaetigt)}, range raw 0..1, transfer-property=TRIGGERED-ON-CHANGE-WITHOUT-REPETITION  # Betätigung der Offroad-Taste
          signal BCM_Charisma_Taste2_XIX_BCM_01_XIX_E3V_EVCANFD: start 22, 1 bit, little-endian, data-type-policy=OVERRIDE, i-signal-type=PRIMITIVE, init-value=0, base-type=BT_BCM_Charisma_Taste2, compu {0=Cx0_nicht_betaetigt (CM_BCM_Charisma_Taste2_Cx0_nicht_betaetigt), 1=Cx1_betaetigt (CM_BCM_Charisma_Taste2_Cx1_betaetigt)}, range raw 0..1, transfer-property=TRIGGERED-ON-CHANGE-WITHOUT-REPETITION  # Betätigung der Charisma-Taste 2
          signal BCM_Hybrid_StSt_Taste_Fehler_XIX_BCM_01_XIX_E3V_EVCANFD: start 23, 1 bit, little-endian, data-type-policy=OVERRIDE, i-signal-type=PRIMITIVE, init-value=0, base-type=BT_BCM_Hybrid_StSt_Taste_Fehler, compu {0=Cx0_kein_Fehler_StSt_Taster (CM_BCM_Hybrid_StSt_Taste_Fehler_Cx0_kein_Fehler_StSt_Taster), 1=Cx1_Fehler_StSt_Taster (CM_BCM_Hybrid_StSt_Taste_Fehler_Cx1_Fehler_StSt_Taster)}, range raw 0..1, transfer-property=TRIGGERED-ON-CHANGE-WITHOUT-REPETITION  # Fehlerflag, wenn Tasterdiagnose im BCM für den StSt-Taster anschlägt.
          signal BCM_Hybrid_StartStopp_Taste_XIX_BCM_01_XIX_E3V_EVCANFD: start 24, 1 bit, little-endian, data-type-policy=OVERRIDE, i-signal-type=PRIMITIVE, init-value=0, base-type=BT_BCM_Hybrid_StartStopp_Taste, compu {0=Cx0_nicht_betaetigt (CM_BCM_Hybrid_StartStopp_Taste_Cx0_nicht_betaetigt), 1=Cx1_betaetigt (CM_BCM_Hybrid_StartStopp_Taste_Cx1_betaetigt)}, range raw 0..1, transfer-property=TRIGGERED-ON-CHANGE-WITHOUT-REPETITION  # Betaetigung Taster "Hybrid" oder alternativ Taster "Start/Stopp Deaktivierung", je nach Verbau
          signal BCM1_Warnblink_Taster_XIX_BCM_01_XIX_E3V_EVCANFD: start 25, 1 bit, little-endian, data-type-policy=OVERRIDE, i-signal-type=PRIMITIVE, init-value=0, base-type=BT_BCM1_Warnblink_Taster, compu {0=Cx0_nicht_betaetigt (CM_BCM1_Warnblink_Taster_Cx0_nicht_betaetigt), 1=Cx1_betaetigt (CM_BCM1_Warnblink_Taster_Cx1_betaetigt)}, range raw 0..1, transfer-property=TRIGGERED-ON-CHANGE-WITHOUT-REPETITION  # Warnblinktaster
          signal BCM1_Valet_Parking_Taster_XIX_BCM_01_XIX_E3V_EVCANFD: start 26, 1 bit, little-endian, data-type-policy=OVERRIDE, i-signal-type=PRIMITIVE, init-value=0, base-type=BT_BCM1_Valet_Parking_Taster, compu {0=Cx0_nicht_betaetigt (CM_BCM1_Valet_Parking_Taster_Cx0_nicht_betaetigt), 1=Cx1_betaetigt (CM_BCM1_Valet_Parking_Taster_Cx1_betaetigt)}, range raw 0..1, transfer-property=PENDING  # Valet Parking Taster
          signal BCM1_Rueckfahrlicht_Schalter_XIX_BCM_01_XIX_E3V_EVCANFD: start 30, 1 bit, little-endian, data-type-policy=OVERRIDE, i-signal-type=PRIMITIVE, init-value=0, base-type=BT_BCM1_Rueckfahrlicht_Schalter, compu {0=Cx0_nicht_betaetigt (CM_BCM1_Rueckfahrlicht_Schalter_Cx0_nicht_betaetigt), 1=Cx1_betaetigt (CM_BCM1_Rueckfahrlicht_Schalter_Cx1_betaetigt)}, range raw 0..1, transfer-property=TRIGGERED-ON-CHANGE-WITHOUT-REPETITION, to Klima(timeout 5 s)  # Rückfahrlichtschalter ab MQB/ MLBevo: Die Ganginformation wird unentprellt übertragen, im AT-Getriebe wird evtl. kurzzeitig der R-Gang angezeigt. Eine Entprellung muß im Empfänger erfolgen (typisch 400ms).
          signal BCM1_MH_Schalter_XIX_BCM_01_XIX_E3V_EVCANFD: start 31, 1 bit, little-endian, data-type-policy=OVERRIDE, i-signal-type=PRIMITIVE, init-value=0, base-type=BT_BCM1_MH_Schalter, compu {0=Cx0_MH_geschlossen (CM_BCM1_MH_Schalter_Cx0_MH_geschlossen), 1=Cx1_MH_offen (CM_BCM1_MH_Schalter_Cx1_MH_offen)}, range raw 0..1, transfer-property=TRIGGERED-ON-CHANGE-WITHOUT-REPETITION  # Motorhaubenkontakt
          signal BCM1_MH_WIV_Schalter_XIX_BCM_01_XIX_E3V_EVCANFD: start 32, 1 bit, little-endian, data-type-policy=OVERRIDE, i-signal-type=PRIMITIVE, init-value=0, base-type=BT_BCM1_MH_WIV_Schalter, compu {0=Cx0_MH_geschlossen (CM_BCM1_MH_WIV_Schalter_Cx0_MH_geschlossen), 1=Cx1_MH_offen (CM_BCM1_MH_WIV_Schalter_Cx1_MH_offen)}, range raw 0..1, transfer-property=TRIGGERED-ON-CHANGE-WITHOUT-REPETITION  # Bewerteter Motorhaubenkontakt fuer WIV
          signal BCM_Eco_Charisma_Taste_XIX_BCM_01_XIX_E3V_EVCANFD: start 33, 1 bit, little-endian, data-type-policy=OVERRIDE, i-signal-type=PRIMITIVE, init-value=0, base-type=BT_BCM_Eco_Charisma_Taste, compu {0=Cx0_nicht_betaetigt (CM_BCM_Eco_Charisma_Taste_Cx0_nicht_betaetigt), 1=Cx1_betaetigt (CM_BCM_Eco_Charisma_Taste_Cx1_betaetigt)}, range raw 0..1, transfer-property=TRIGGERED-ON-CHANGE-WITHOUT-REPETITION  # Betätigung Taster ECO alias BlueKey oder Charisma
          signal BCM1_NV_Taster_XIX_BCM_01_XIX_E3V_EVCANFD: start 34, 1 bit, little-endian, data-type-policy=OVERRIDE, i-signal-type=PRIMITIVE, init-value=0, base-type=BT_BCM1_NV_Taster, compu {0=Cx0_Taster_nicht_betaetigt (CM_BCM1_NV_Taster_Cx0_Taster_nicht_betaetigt), 1=Cx1_Taster_betaetigt (CM_BCM1_NV_Taster_Cx1_Taster_betaetigt)}, range raw 0..1, transfer-property=PENDING  # BCM1_NV_Taster gibt an, ob der NightVision-Taster im Lichtdrehschalter-Modul aktuell betaetigt wird.
          signal BCM1_AFS_Lampe_XIX_BCM_01_XIX_E3V_EVCANFD: start 35, 1 bit, little-endian, data-type-policy=OVERRIDE, i-signal-type=PRIMITIVE, init-value=0, base-type=BT_BCM1_AFS_Lampe, compu {0=Cx0_Aus (CM_BCM1_AFS_Lampe_Cx0_Aus), 1=Cx1_Ein (CM_BCM1_AFS_Lampe_Cx1_Ein)}, range raw 0..1, transfer-property=TRIGGERED-ON-CHANGE-WITHOUT-REPETITION  # Ansteuerung der AFS-Fehlermeldung im Kombi
          signal BCM1_Reisemodus_Texte_XIX_BCM_01_XIX_E3V_EVCANFD: start 36, 2 bit, little-endian, data-type-policy=OVERRIDE, i-signal-type=PRIMITIVE, init-value=0, base-type=BT_BCM1_Reisemodus_Texte, compu {0=Cx0_keine_Anzeige (CM_BCM1_Reisemodus_Texte_Cx0_keine_Anzeige), 1=Cx1_Umschaltung_auf_Linksverkehr_aktiv (CM_BCM1_Reisemodus_Texte_Cx1_Umschaltung_auf_Linksverkehr_aktiv), 2=Cx2_Umschaltung_auf_Rechtsverkehr_aktiv (CM_BCM1_Reisemodus_Texte_Cx2_Umschaltung_auf_Rechtsverkehr_aktiv)}, range raw 0..2, transfer-property=TRIGGERED-ON-CHANGE-WITHOUT-REPETITION  # Ansteuerung der Reisemodus-Texte im Kombi
          signal Gong_TFL_Umschaltung_XIX_BCM_01_XIX_E3V_EVCANFD: start 40, 1 bit, little-endian, data-type-policy=OVERRIDE, i-signal-type=PRIMITIVE, init-value=0, base-type=BT_Gong_TFL_Umschaltung, compu {0=Cx0_kein_Gong (CM_Gong_TFL_Umschaltung_Cx0_kein_Gong), 1=Cx1_Gong_einmalig (CM_Gong_TFL_Umschaltung_Cx1_Gong_einmalig)}, range raw 0..1, transfer-property=TRIGGERED-ON-CHANGE-WITHOUT-REPETITION  # Aktivierung / Deaktivierung des TFL per Affengriff wird mit einem Gong im Kombi quittiert.
          signal BCM_ValetTaster_Fkts_LED_XIX_BCM_01_XIX_E3V_EVCANFD: start 42, 1 bit, little-endian, data-type-policy=OVERRIDE, i-signal-type=PRIMITIVE, init-value=0, base-type=BT_BCM_ValetTaster_Fkts_LED, compu {0=Cx0_LED_aus (CM_BCM_ValetTaster_Fkts_LED_Cx0_LED_aus), 1=Cx1_LED_ein (CM_BCM_ValetTaster_Fkts_LED_Cx1_LED_ein)}, range raw 0..1, transfer-property=TRIGGERED-ON-CHANGE  # Im MQB beschreibt das Signal nur den Zustand der Funktion Valet Parking (aktiv/ inaktiv) Im MLBevo wird über das Signal zusätzlich die ValetTaster_Fkts_LED (an/ aus) gesteuert
          signal LRH_Taster_XIX_BCM_01_XIX_E3V_EVCANFD: start 43, 1 bit, little-endian, data-type-policy=OVERRIDE, i-signal-type=PRIMITIVE, init-value=0, base-type=BT_LRH_Taster, compu {0=Cx0_nicht_betaetigt (CM_LRH_Taster_Cx0_nicht_betaetigt), 1=Cx1_betaetigt (CM_LRH_Taster_Cx1_betaetigt)}, range raw 0..1, transfer-property=TRIGGERED-ON-CHANGE-WITHOUT-REPETITION  # Tasterbetätigung Lenkradheizung
          signal APS_Tongeber_defekt_XIX_BCM_01_XIX_E3V_EVCANFD: start 44, 1 bit, little-endian, data-type-policy=OVERRIDE, i-signal-type=PRIMITIVE, init-value=0, base-type=BT_APS_Tongeber_defekt, compu {0=Cx0_iO (CM_APS_Tongeber_defekt_Cx0_iO), 1=Cx1_defekt (CM_APS_Tongeber_defekt_Cx1_defekt)}, range raw 0..1, transfer-property=TRIGGERED-ON-CHANGE-WITHOUT-REPETITION  # Status APS-Tongeber zur HMI-Ansteuerng der RCTA-Funktion
          signal BCM1_EasyEntry_Status_XIX_BCM_01_XIX_E3V_EVCANFD: start 45, 1 bit, little-endian, data-type-policy=OVERRIDE, i-signal-type=PRIMITIVE, init-value=0, base-type=BT_BCM1_EasyEntry_Status, compu {0=Cx0_Aus (CM_BCM1_EasyEntry_Status_Cx0_Aus), 1=Cx1_Ein (CM_BCM1_EasyEntry_Status_Cx1_Ein)}, range raw 0..1, transfer-property=TRIGGERED-ON-CHANGE-WITHOUT-REPETITION  # Status EasyEntry für Lenksäule (wird auch von IVB verwendet)
          signal BCM1_Lenksaeule_aktiv_XIX_BCM_01_XIX_E3V_EVCANFD: start 46, 1 bit, little-endian, data-type-policy=OVERRIDE, i-signal-type=PRIMITIVE, init-value=0, base-type=BT_BCM1_Lenksaeule_aktiv, compu {0=Cx0_Lenksaeulenverstellung_nicht_aktiv (CM_BCM1_Lenksaeule_aktiv_Cx0_Lenksaeulenverstellung_nicht_aktiv) (Lenksaeulenverstellung nicht aktiv), 1=Cx1_Lenksaeulenverstellung_aktiv (CM_BCM1_Lenksaeule_aktiv_Cx1_Lenksaeulenverstellung_aktiv) (Lenksaeulenverstellung aktiv)}, range raw 0..1, transfer-property=TRIGGERED-ON-CHANGE-WITHOUT-REPETITION  # Lenksaeulenverstellung aktiv
          signal BCM1_Spannungs_Anf_XIX_BCM_01_XIX_E3V_EVCANFD: start 47, 2 bit, little-endian, data-type-policy=OVERRIDE, i-signal-type=PRIMITIVE, init-value=0, base-type=BT_BCM1_Spannungs_Anf, compu {0=Cx0_keine_Anforderung (CM_BCM1_Spannungs_Anf_Cx0_keine_Anforderung), 1=Cx1_Anforderung_Stufe_1 (CM_BCM1_Spannungs_Anf_Cx1_Anforderung_Stufe_1), 2=Cx2_Anforderung_Stufe_2 (CM_BCM1_Spannungs_Anf_Cx2_Anforderung_Stufe_2), 3=Cx3_Anforderung_Stufe_3 (CM_BCM1_Spannungs_Anf_Cx3_Anforderung_Stufe_3)}, range raw 0..3, transfer-property=TRIGGERED-ON-CHANGE-WITHOUT-REPETITION  # Forderung des BCM1-SG's zur Spannungsanhebung.
          signal BCM_Anf_AAW_MoLaWa_XIX_BCM_01_XIX_E3V_EVCANFD: start 58, 2 bit, little-endian, data-type-policy=OVERRIDE, i-signal-type=PRIMITIVE, init-value=0, base-type=BT_BCM_Anf_AAW_MoLaWa, compu {0=Cx0_Init (CM_BCM_Anf_AAW_MoLaWa_Cx0_Init), 1=Cx1_AAW_angefordert (CM_BCM_Anf_AAW_MoLaWa_Cx1_AAW_angefordert), 2=Cx2_MoLaWa_angefordert (CM_BCM_Anf_AAW_MoLaWa_Cx2_MoLaWa_angefordert)}, range raw 0..2, transfer-property=TRIGGERED-ON-CHANGE-WITHOUT-REPETITION  # Signal zur Anforderung der Antrieb-Aktiv-Warnung und Motorlaufwarnung. Die Berechnung erfolgt im BCM. Die Ausgabe der Warnungen wird vom Kombiinstrument realisiert
          signal BCM_Handbremse_Hinweis_XIX_BCM_01_XIX_E3V_EVCANFD: start 60, 1 bit, little-endian, data-type-policy=OVERRIDE, i-signal-type=PRIMITIVE, init-value=0, base-type=BT_BCM_Handbremse_Hinweis, compu {0=Cx0_inaktiv (CM_BCM_Handbremse_Hinweis_Cx0_inaktiv), 1=Cx1_aktiv (CM_BCM_Handbremse_Hinweis_Cx1_aktiv)}, range raw 0..1, transfer-property=TRIGGERED-ON-CHANGE  # Infotext fuer das Kombiinstrument zur Oeffnung der elektr. Heckklappe.
          signal BCM_HDF_betaetigt_XIX_BCM_01_XIX_E3V_EVCANFD: start 63, 1 bit, little-endian, data-type-policy=OVERRIDE, i-signal-type=PRIMITIVE, init-value=0, base-type=BT_BCM_HDF_betaetigt, compu {0=Cx0_nicht_betaetigt (CM_BCM_HDF_betaetigt_Cx0_nicht_betaetigt), 1=Cx1_betaetigt (CM_BCM_HDF_betaetigt_Cx1_betaetigt)}, range raw 0..1, transfer-property=TRIGGERED-ON-CHANGE  # Betätigung Taster für Heckdeckelfernentriegelung in Mittelkonsole
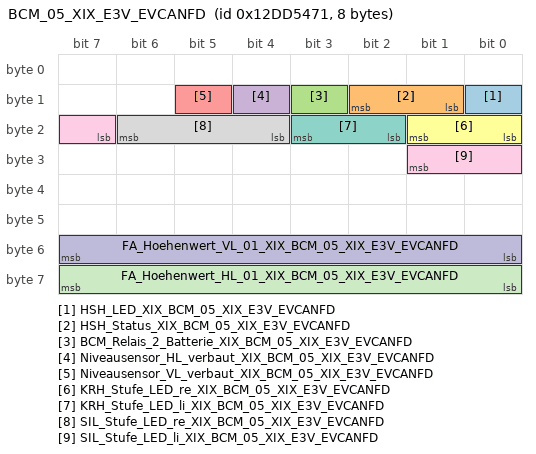
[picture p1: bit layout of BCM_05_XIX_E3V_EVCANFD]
      frame BCM_05_XIX_E3V_EVCANFD: id 0x12DD5471, to Klima, frame-length=8, can-addressing-mode=EXTENDED, can-frame-rx-behavior=CAN-FD, can-frame-tx-behavior=CAN-FD
        pdu BCM_05_XIX_E3V_EVCANFD: length=8, minimum-delay=0.02, transmission-mode-true-timing={cyclic-timing={time-offset=0.0, time-period=0.2}, event-controlled-timing={number-of-repetitions=0, repetition-period=0.0}}, unused-bit-pattern=0
          signal HSH_LED_XIX_BCM_05_XIX_E3V_EVCANFD: start 8, 1 bit, little-endian, data-type-policy=OVERRIDE, i-signal-type=PRIMITIVE, init-value=0, base-type=BT_HSH_LED, compu {0=Cx0_Aus (CM_HSH_LED_Cx0_Aus), 1=Cx1_Ein (CM_HSH_LED_Cx1_Ein)}, range raw 0..1, transfer-property=TRIGGERED-ON-CHANGE-WITHOUT-REPETITION  # LED Ansteuerung Heckscheibenheizung
          signal HSH_Status_XIX_BCM_05_XIX_E3V_EVCANFD: start 9, 2 bit, little-endian, data-type-policy=OVERRIDE, i-signal-type=PRIMITIVE, init-value=0, base-type=BT_HSH_Status, compu {0=Cx0_aus (CM_HSH_Status_Cx0_aus), 1=Cx1_ein (CM_HSH_Status_Cx1_ein), 2=Cx2_tbd (CM_HSH_Status_Cx2_tbd), 3=Cx3_Fehler (CM_HSH_Status_Cx3_Fehler)}, range raw 0..3, transfer-property=PENDING, to Klima(timeout 2 s)  # Status Heckscheibenheizung
          signal BCM_Relais_2_Batterie_XIX_BCM_05_XIX_E3V_EVCANFD: start 11, 1 bit, little-endian, data-type-policy=OVERRIDE, i-signal-type=PRIMITIVE, init-value=0, base-type=BT_BCM_Relais_2_Batterie, compu {0=Cx0_nicht_betaetigt (CM_BCM_Relais_2_Batterie_Cx0_nicht_betaetigt), 1=Cx1_betaetigt (CM_BCM_Relais_2_Batterie_Cx1_betaetigt)}, range raw 0..1, transfer-property=TRIGGERED-ON-CHANGE-WITHOUT-REPETITION  # Zeigt den Zustand des vom BCM bzw KFG angesteuerten Laderelais einer verbauten 2. Batterie an
          signal Niveausensor_HL_verbaut_XIX_BCM_05_XIX_E3V_EVCANFD: start 12, 1 bit, little-endian, data-type-policy=OVERRIDE, i-signal-type=PRIMITIVE, init-value=0, base-type=BT_Niveausensor_HL_verbaut, compu {0=Cx0_nicht_verbaut (CM_Niveausensor_HL_verbaut_Cx0_nicht_verbaut), 1=Cx1_verbaut (CM_Niveausensor_HL_verbaut_Cx1_verbaut)}, range raw 0..1, transfer-property=TRIGGERED-ON-CHANGE-WITHOUT-REPETITION  # Signal wird gesetzt, wenn Niveausensor_hinten codiert wird.
          signal Niveausensor_VL_verbaut_XIX_BCM_05_XIX_E3V_EVCANFD: start 13, 1 bit, little-endian, data-type-policy=OVERRIDE, i-signal-type=PRIMITIVE, init-value=0, base-type=BT_Niveausensor_VL_verbaut, compu {0=Cx0_nicht_verbaut (CM_Niveausensor_VL_verbaut_Cx0_nicht_verbaut), 1=Cx1_verbaut (CM_Niveausensor_VL_verbaut_Cx1_verbaut)}, range raw 0..1, transfer-property=TRIGGERED-ON-CHANGE-WITHOUT-REPETITION  # Signal wird gesetzt, wenn Niveausensor_vorne codiert wird.
          signal KRH_Stufe_LED_re_XIX_BCM_05_XIX_E3V_EVCANFD: start 16, 2 bit, little-endian, data-type-policy=OVERRIDE, i-signal-type=PRIMITIVE, init-value=0, base-type=BT_KRH_Stufe_LED_re, compu {0=Cx0_Aus (CM_KRH_Stufe_LED_re_Cx0_Aus), 1=Cx1_Stufe_1 (CM_KRH_Stufe_LED_re_Cx1_Stufe_1), 2=Cx2_Stufe_2 (CM_KRH_Stufe_LED_re_Cx2_Stufe_2), 3=Cx3_Stufe_3 (CM_KRH_Stufe_LED_re_Cx3_Stufe_3)}, range raw 0..3, transfer-property=TRIGGERED-ON-CHANGE-WITHOUT-REPETITION  # Statusmeldung Kopfraumheizung rechts
          signal KRH_Stufe_LED_li_XIX_BCM_05_XIX_E3V_EVCANFD: start 18, 2 bit, little-endian, data-type-policy=OVERRIDE, i-signal-type=PRIMITIVE, init-value=0, base-type=BT_KRH_Stufe_LED_li, compu {0=Cx0_Aus (CM_KRH_Stufe_LED_li_Cx0_Aus), 1=Cx1_Stufe_1 (CM_KRH_Stufe_LED_li_Cx1_Stufe_1), 2=Cx2_Stufe_2 (CM_KRH_Stufe_LED_li_Cx2_Stufe_2), 3=Cx3_Stufe_3 (CM_KRH_Stufe_LED_li_Cx3_Stufe_3)}, range raw 0..3, transfer-property=TRIGGERED-ON-CHANGE-WITHOUT-REPETITION  # Statusmeldung Kopfraumheizung links
          signal SIL_Stufe_LED_re_XIX_BCM_05_XIX_E3V_EVCANFD: start 20, 3 bit, little-endian, data-type-policy=OVERRIDE, i-signal-type=PRIMITIVE, init-value=0, base-type=BT_SIL_Stufe_LED_re, compu {0=Cx0_Aus (CM_SIL_Stufe_LED_re_Cx0_Aus), 1=Cx1_Stufe_1 (CM_SIL_Stufe_LED_re_Cx1_Stufe_1), 2=Cx2_Stufe_2 (CM_SIL_Stufe_LED_re_Cx2_Stufe_2), 3=Cx3_Stufe_3 (CM_SIL_Stufe_LED_re_Cx3_Stufe_3), 4=Cx4_Stufe_4 (CM_SIL_Stufe_LED_re_Cx4_Stufe_4), 5=Cx5_Stufe_5 (CM_SIL_Stufe_LED_re_Cx5_Stufe_5), 6=Cx6_Stufe_6 (CM_SIL_Stufe_LED_re_Cx6_Stufe_6)}, range raw 0..6, transfer-property=TRIGGERED-ON-CHANGE-WITHOUT-REPETITION, to Klima(timeout 2 s)  # Statusmeldung Sitzlüftung rechts
          signal SIL_Stufe_LED_li_XIX_BCM_05_XIX_E3V_EVCANFD: start 23, 3 bit, little-endian, data-type-policy=OVERRIDE, i-signal-type=PRIMITIVE, init-value=0, base-type=BT_SIL_Stufe_LED_li, compu {0=Cx0_Aus (CM_SIL_Stufe_LED_li_Cx0_Aus), 1=Cx1_Stufe_1 (CM_SIL_Stufe_LED_li_Cx1_Stufe_1), 2=Cx2_Stufe_2 (CM_SIL_Stufe_LED_li_Cx2_Stufe_2), 3=Cx3_Stufe_3 (CM_SIL_Stufe_LED_li_Cx3_Stufe_3), 4=Cx4_Stufe_4 (CM_SIL_Stufe_LED_li_Cx4_Stufe_4), 5=Cx5_Stufe_5 (CM_SIL_Stufe_LED_li_Cx5_Stufe_5), 6=Cx6_Stufe_6 (CM_SIL_Stufe_LED_li_Cx6_Stufe_6)}, range raw 0..6, transfer-property=TRIGGERED-ON-CHANGE-WITHOUT-REPETITION, to Klima(timeout 2 s)  # Statusmeldung Sitzlüftung links
          signal FA_Hoehenwert_VL_01_XIX_BCM_05_XIX_E3V_EVCANFD: start 48, 8 bit, little-endian, data-type-policy=OVERRIDE, i-signal-type=PRIMITIVE, init-value=254, base-type=BT_FA_Hoehenwert_VL_01, invalid-value=Invalid_FA_Hoehenwert_VL_01_XIX_BCM_05_XIX_E3V_EVCANFD:255, compu {phys=raw*0.4 for raw 0..250, 254=Cxfe_nicht_initialisiert (CM_FA_Hoehenwert_VL_01_Cxfe_nicht_initialisiert) (nicht initialisiert), 255=Cxff_Fehler (CM_FA_Hoehenwert_VL_01_Cxff_Fehler); unit Unit_PerCent}, range phys 0..100 Unit_PerCent, raw 0..255, unit=Unit_PerCent, transfer-property=TRIGGERED-ON-CHANGE-WITHOUT-REPETITION  # Aktueller Höhenwert (Rohwerte) Vorne Links; ungefiltertes Signal Einheit, Offset und Faktor sind abhänig von "FA_Hoehenwert_kalibriert"
          signal FA_Hoehenwert_HL_01_XIX_BCM_05_XIX_E3V_EVCANFD: start 56, 8 bit, little-endian, data-type-policy=OVERRIDE, i-signal-type=PRIMITIVE, init-value=254, base-type=BT_FA_Hoehenwert_HL_01, invalid-value=Invalid_FA_Hoehenwert_HL_01_XIX_BCM_05_XIX_E3V_EVCANFD:255, compu {phys=raw*0.4 for raw 0..250, 254=Cxfe_nicht_initialisiert (CM_FA_Hoehenwert_HL_01_Cxfe_nicht_initialisiert) (nicht initialisiert), 255=Cxff_Fehler (CM_FA_Hoehenwert_HL_01_Cxff_Fehler); unit Unit_PerCent}, range phys 0..100 Unit_PerCent, raw 0..255, unit=Unit_PerCent, transfer-property=TRIGGERED-ON-CHANGE-WITHOUT-REPETITION  # Aktueller Höhenwert (Rohwerte) Hinten Links; ungefiltertes Signal Einheit, Offset und Faktor sind abhänig von "FA_Hoehenwert_kalibriert"
      frame BEM_02_XIX_E3V_EVCANFD: id 0x663, to Klima, frame-length=8, can-addressing-mode=STANDARD, can-frame-rx-behavior=CAN-FD, can-frame-tx-behavior=CAN-FD
        pdu BEM_02_XIX_E3V_EVCANFD: length=8, transmission-mode-true-timing=cyclic-timing={time-offset=0.0, time-period=0.1}, unused-bit-pattern=0  # DLC=8 ab D4 gültig
          signal NVEM_Abschaltstufe_XIX_BEM_02_XIX_E3V_EVCANFD: start 0, 2 bit, little-endian, data-type-policy=OVERRIDE, i-signal-type=PRIMITIVE, base-type=BT_NVEM_Abschaltstufe, compu {0=Cx0_Stufe_0_keine_Einschraenkung (CM_NVEM_Abschaltstufe_Cx0_Stufe_0_keine_Einschraenkung), 1=Cx1_Stufe_1 (CM_NVEM_Abschaltstufe_Cx1_Stufe_1), 2=Cx2_Stufe_2 (CM_NVEM_Abschaltstufe_Cx2_Stufe_2), 3=Cx3_Stufe_3 (CM_NVEM_Abschaltstufe_Cx3_Stufe_3)}, range raw 0..3, transfer-property=PENDING, to Klima(timeout 1 s)  # Abschaltstufe aus dem Ruheenergiemanagement Maßnahmen des Empfängers werden im QLAH Ruhestrommanagement definiert
          signal BEM_STH_Zielzeit_XIX_BEM_02_XIX_E3V_EVCANFD: start 3, 4 bit, little-endian, data-type-policy=OVERRIDE, i-signal-type=PRIMITIVE, init-value=14, base-type=BT_BEM_STH_Zielzeit, invalid-value=Invalid_BEM_STH_Zielzeit_XIX_BEM_02_XIX_E3V_EVCANFD:15, compu {phys=raw*5 for raw 0..12, 14=Cxe_Init (CM_BEM_STH_Zielzeit_Cxe_Init), 15=Cxf_Fehler (CM_BEM_STH_Zielzeit_Cxf_Fehler); unit Unit_Minut}, range phys 0..60 Unit_Minut, raw 0..15, unit=Unit_Minut, transfer-property=PENDING  # Maximal mögliche Zeit für den Standheizungsbetrieb, um die Startfähigkeit nicht zu gefährden
          signal BEM_MMI_Vorwarnung_XIX_BEM_02_XIX_E3V_EVCANFD: start 7, 1 bit, little-endian, data-type-policy=OVERRIDE, i-signal-type=PRIMITIVE, init-value=0, base-type=BT_BEM_MMI_Vorwarnung, compu {0=Cx0_keine_Anzeige (CM_BEM_MMI_Vorwarnung_Cx0_keine_Anzeige) (keine Anzeige), 1=Cx1_Anzeige_MMI_Vorwarnung (CM_BEM_MMI_Vorwarnung_Cx1_Anzeige_MMI_Vorwarnung) (Anzeige MMI-Vorwarnung)}, range raw 0..1, transfer-property=PENDING  # Anzeige Vorwarnung MMI-Abschaltung (Initialisierungswert aus EEprom)
          signal BEM_HL_Kontingentierung_XIX_BEM_02_XIX_E3V_EVCANFD: start 8, 6 bit, little-endian, data-type-policy=OVERRIDE, i-signal-type=PRIMITIVE, init-value=0, base-type=BT_BEM_HL_Kontingentierung, compu {phys=raw*50-1000 for raw 0..40; unit Unit_Watt}, range phys -1000..1000 Unit_Watt, raw 0..40, unit=Unit_Watt, transfer-property=PENDING  # Leistungskontingente für Heizsysteme
          signal NVEM_Freigabe_ZusBatt_Laden_XIX_BEM_02_XIX_E3V_EVCANFD: start 14, 1 bit, little-endian, data-type-policy=OVERRIDE, i-signal-type=PRIMITIVE, init-value=0, base-type=BT_NVEM_Freigabe_ZusBatt_Laden, compu {0=Cx0_keine_Freigabe_Laderelais (CM_NVEM_Freigabe_ZusBatt_Laden_Cx0_keine_Freigabe_Laderelais), 1=Cx1_Freigabe_Laderelais_schliessen (CM_NVEM_Freigabe_ZusBatt_Laden_Cx1_Freigabe_Laderelais_schliessen)}, range raw 0..1, transfer-property=PENDING  # NVEM gibt die Freigabe zum Schließen des Laderelais im Ruhebetrieb (z.B. bei Verwendung eines Ladegerätes)
          signal NVEM_Anf_SD_schalten_XIX_BEM_02_XIX_E3V_EVCANFD: start 15, 1 bit, little-endian, data-type-policy=OVERRIDE, i-signal-type=PRIMITIVE, init-value=0, base-type=BT_NVEM_Anf_SD_schalten, compu {0=Cx0_Anf_SD_Nachlauf_nicht_aktiv (CM_NVEM_Anf_SD_schalten_Cx0_Anf_SD_Nachlauf_nicht_aktiv), 1=Cx1_Anf_SD_Nachlauf_aktiv (CM_NVEM_Anf_SD_schalten_Cx1_Anf_SD_Nachlauf_aktiv)}, range raw 0..1, transfer-property=PENDING  # Anforderung Nachlauf für den Steckdosenbetrieb Initialisierungswert aus EEprom
          signal BEM_Generatordiagnose_XIX_BEM_02_XIX_E3V_EVCANFD: start 16, 2 bit, little-endian, data-type-policy=OVERRIDE, i-signal-type=PRIMITIVE, init-value=0, base-type=BT_BEM_Generatordiagnose, compu {0=Cx0_keine_Anzeige (CM_BEM_Generatordiagnose_Cx0_keine_Anzeige) (keine Anzeige), 1=Cx1_Ladekontrollanzeige_ein_Vorhalt (CM_BEM_Generatordiagnose_Cx1_Ladekontrollanzeige_ein_Vorhalt) (Ladekontrollanzeige ein (Vorhalt)), 2=Cx2_rotes_Batteriesymbol_und_Text_Generator_defekt (CM_BEM_Generatordiagnose_Cx2_rotes_Batteriesymbol_und_Text_Generator_defekt) (rotes Batteriesymbol und Text (Generator defekt)), 3=Cx3_Hybrid_DCDC_Wandler_defekt (CM_BEM_Generatordiagnose_Cx3_Hybrid_DCDC_Wandler_defekt)}, range raw 0..3, transfer-property=PENDING  # Ansteuerung Generatorwarnleuchte im Kombi
          signal BEM_Red_Innengeblaese_XIX_BEM_02_XIX_E3V_EVCANFD: start 18, 2 bit, little-endian, data-type-policy=OVERRIDE, i-signal-type=PRIMITIVE, init-value=0, base-type=BT_BEM_Red_Innengeblaese, compu {0=Cx0_keine_Reduzierung (CM_BEM_Red_Innengeblaese_Cx0_keine_Reduzierung) (keine Reduzierung), 1=Cx1_Reduzierung_Stufe_1 (CM_BEM_Red_Innengeblaese_Cx1_Reduzierung_Stufe_1) (Reduzierung Stufe 1), 2=Cx2_Reduzierung_Stufe_2 (CM_BEM_Red_Innengeblaese_Cx2_Reduzierung_Stufe_2) (Reduzierung Stufe 2), 3=Cx3_Reduzierung_Stufe_2_und_Abschaltung_Kompressor (CM_BEM_Red_Innengeblaese_Cx3_Reduzierung_Stufe_2_und_Abschaltung_Kompressor) (Reduzierung Stufe 2 und Abschaltung Kompressor)}, range raw 0..3, transfer-property=PENDING, to Klima(timeout 1 s)  # Reduzierung Innengebläse
          signal BEM_STH_Einschaltverbot_XIX_BEM_02_XIX_E3V_EVCANFD: start 20, 1 bit, little-endian, data-type-policy=OVERRIDE, i-signal-type=PRIMITIVE, init-value=0, base-type=BT_BEM_STH_Einschaltverbot, compu {0=Cx0_volle_Verfuegbarkeit_Standheizung_lueftung (CM_BEM_STH_Einschaltverbot_Cx0_volle_Verfuegbarkeit_Standheizung_lueftung) (volle Verfuegbarkeit Standheizung/-lueftung), 1=Cx1_Standheizung_lueftung_nicht_aktivierbar (CM_BEM_STH_Einschaltverbot_Cx1_Standheizung_lueftung_nicht_aktivierbar) (Standheizung/-lueftung nicht aktivierbar)}, range raw 0..1, transfer-property=PENDING  # Einschränkung Standheizung/-lüftung durch BEM: Setzt der BEM das Bit, dann darf die Standheizung nicht mehr einschalten (Die Standheizung muss aber nicht abschalten, sondern darf weiterbrennen) (Initialisierungswert aus EEprom)
          signal BEM_HL_Regelung_Status_XIX_BEM_02_XIX_E3V_EVCANFD: start 21, 3 bit, little-endian, data-type-policy=OVERRIDE, i-signal-type=PRIMITIVE, init-value=0, base-type=BT_BEM_HL_Regelung_Status, compu {0=Cx0_HL_Regelung_inaktiv_vor_und_waehrend_Motorstart (CM_BEM_HL_Regelung_Status_Cx0_HL_Regelung_inaktiv_vor_und_waehrend_Motorstart) (HL_Regelung_inaktiv_(vor_und_waehrend_Motorstart)), 1=Cx1_HL_Regelung_Stufe_1 (CM_BEM_HL_Regelung_Status_Cx1_HL_Regelung_Stufe_1), 2=Cx2_HL_Regelung_Stufe_2 (CM_BEM_HL_Regelung_Status_Cx2_HL_Regelung_Stufe_2), 3=Cx3_HL_Regelung_Stufe_3 (CM_BEM_HL_Regelung_Status_Cx3_HL_Regelung_Stufe_3), 4=Cx4_Verbrauchernotabschaltung_VNA (CM_BEM_HL_Regelung_Status_Cx4_Verbrauchernotabschaltung_VNA) (Verbrauchernotabschaltung_(VNA)), 5=Cx5_HL_Regelung_Stufe_5 (CM_BEM_HL_Regelung_Status_Cx5_HL_Regelung_Stufe_5), 7=Cx7_Default (CM_BEM_HL_Regelung_Status_Cx7_Default)}, range raw 0..7, transfer-property=PENDING  # Status Regelung Heizleistung
          signal BEM_Ladezustand_XIX_BEM_02_XIX_E3V_EVCANFD: start 24, 4 bit, little-endian, data-type-policy=OVERRIDE, i-signal-type=PRIMITIVE, init-value=14, base-type=BT_BEM_Ladezustand, invalid-value=Invalid_BEM_Ladezustand_XIX_BEM_02_XIX_E3V_EVCANFD:15, compu {phys=raw*10 for raw 0..10, 14=Cxe_Init (CM_BEM_Ladezustand_Cxe_Init), 15=Cxf_Fehler (CM_BEM_Ladezustand_Cxf_Fehler); unit Unit_PerCent}, range phys 0..100 Unit_PerCent, raw 0..15, unit=Unit_PerCent, transfer-property=PENDING  # Ladezustand der Niedervoltbatterie
          signal BEM_Batteriediagnose_XIX_BEM_02_XIX_E3V_EVCANFD: start 28, 3 bit, little-endian, data-type-policy=OVERRIDE, i-signal-type=PRIMITIVE, init-value=0, base-type=BT_BEM_Batteriediagnose, invalid-value=Invalid_BEM_Batteriediagnose_XIX_BEM_02_XIX_E3V_EVCANFD:7, compu {0=Cx0_keine_Anzeige (CM_BEM_Batteriediagnose_Cx0_keine_Anzeige), 1=Cx1_nicht_belegt (CM_BEM_Batteriediagnose_Cx1_nicht_belegt), 2=Cx2_Anzeige_aberkannte_Batterie (CM_BEM_Batteriediagnose_Cx2_Anzeige_aberkannte_Batterie), 3=Cx3_Anzeige_schwache_Batterie (CM_BEM_Batteriediagnose_Cx3_Anzeige_schwache_Batterie), 4=Cx4_Anzeige_Batterie_OK (CM_BEM_Batteriediagnose_Cx4_Anzeige_Batterie_OK), 5=Cx5_Anzeige_Batterie_Laden (CM_BEM_Batteriediagnose_Cx5_Anzeige_Batterie_Laden), 6=Cx6_Anzeige_Batterie_Pruefen (CM_BEM_Batteriediagnose_Cx6_Anzeige_Batterie_Pruefen), 7=Cx7_Fehler (CM_BEM_Batteriediagnose_Cx7_Fehler)}, range raw 0..7, transfer-property=PENDING  # Anzeige von Textwarnungen
          signal MIB_Stromsparmodus_XIX_BEM_02_XIX_E3V_EVCANFD: start 31, 1 bit, little-endian, data-type-policy=OVERRIDE, i-signal-type=PRIMITIVE, init-value=0, base-type=BT_MIB_Stromsparmodus, compu {0=Cx0_inaktiv (CM_MIB_Stromsparmodus_Cx0_inaktiv), 1=Cx1_aktiv (CM_MIB_Stromsparmodus_Cx1_aktiv)}, range raw 0..1, transfer-property=PENDING  # Signal beschreibt die Aktivierung für den Stromsparmodus beim MIB. Bei AUS (= 0) gibt es keine weitere Anforderung an die MIB-Komponenten. Bei EIN (= 1) werden alle MIB Komponenten in einen Stromsparmodus versetzt.
          signal BEM_DFM_XIX_BEM_02_XIX_E3V_EVCANFD: start 32, 5 bit, little-endian, data-type-policy=OVERRIDE, i-signal-type=PRIMITIVE, init-value=0, base-type=BT_BEM_DFM, compu {phys=raw*3.225+0.025 for raw 0..31}, range phys 0.025..100, raw 0..31, transfer-property=PENDING  # Generatorauslastungsgrad, vom Generator über LIN an das Gateway gesandt. Das Motorsteuergerät regelt auf dieses Signal die PTC, das Energiemanagement im BSG/BCM kalkuliert die Bordnetzauslastung
          signal BEM_REK_aktiv_XIX_BEM_02_XIX_E3V_EVCANFD: start 37, 1 bit, little-endian, data-type-policy=OVERRIDE, i-signal-type=PRIMITIVE, init-value=0, base-type=BT_BEM_REK_aktiv, compu {0=Cx0_keine_Rekuperationsfreigabe (CM_BEM_REK_aktiv_Cx0_keine_Rekuperationsfreigabe), 1=Cx1_Rekuperationsfreigabe (CM_BEM_REK_aktiv_Cx1_Rekuperationsfreigabe)}, range raw 0..1, transfer-property=PENDING  # Rekuperationsfreigabe vom Energiemanagement 0x0 = keine Rekuperationsfreigabe 0x1 = Rekuperationsfreigabe
          signal BEM_EMLIN_ungueltig_XIX_BEM_02_XIX_E3V_EVCANFD: start 38, 1 bit, little-endian, data-type-policy=OVERRIDE, i-signal-type=PRIMITIVE, init-value=0, base-type=BT_BEM_EMLIN_ungueltig, compu {0=Cx0_Signale_gueltig (CM_BEM_EMLIN_ungueltig_Cx0_Signale_gueltig), 1=Cx1_Signale_ungueltig (CM_BEM_EMLIN_ungueltig_Cx1_Signale_ungueltig)}, range raw 0..1, transfer-property=PENDING  # Energie-Lin - Signale sind ungültig vom Slave Batteriedatenmodul oder Generator 0 = Signale gültig 1 = Signale ungültig
          signal BEM_Batt_Ab_XIX_BEM_02_XIX_E3V_EVCANFD: start 39, 1 bit, little-endian, data-type-policy=OVERRIDE, i-signal-type=PRIMITIVE, init-value=0, base-type=BT_BEM_Batt_Ab, compu {0=Cx0_verbunden (CM_BEM_Batt_Ab_Cx0_verbunden), 1=Cx1_nicht_verbunden (CM_BEM_Batt_Ab_Cx1_nicht_verbunden)}, range raw 0..1, transfer-property=PENDING  # Batterieverbindungskontrolle: 0x0: Batterie am Bordnetz 0x1: Batterie ab erkannt
          signal BEM_UBDM_XIX_BEM_02_XIX_E3V_EVCANFD: start 40, 8 bit, little-endian, data-type-policy=OVERRIDE, i-signal-type=PRIMITIVE, init-value=0, base-type=BT_BEM_UBDM, invalid-value=Invalid_BEM_UBDM_XIX_BEM_02_XIX_E3V_EVCANFD:255, compu {0=Cx0_Init (CM_BEM_UBDM_Cx0_Init), phys=raw*0.05+5 for raw 1..254, 255=Cxff_Fehler (CM_BEM_UBDM_Cxff_Fehler); unit Unit_Volt}, range phys 5.05..17.7 Unit_Volt, raw 0..255, unit=Unit_Volt, transfer-property=PENDING  # Batteriespannung, gemessen vom Batteriedatenmodul
          signal BEM_UGenSoll_XIX_BEM_02_XIX_E3V_EVCANFD: start 48, 6 bit, little-endian, data-type-policy=OVERRIDE, i-signal-type=PRIMITIVE, init-value=0, base-type=BT_BEM_UGenSoll, compu {phys=raw*0.1+10.6 for raw 0..54; unit Unit_Volt}, range phys 10.6..16 Unit_Volt, raw 0..54, unit=Unit_Volt, transfer-property=PENDING  # Sollspannungsvorgabe an den Generator, beinhaltet temperaturoptimierte Batterieladung und Rekuperation
          signal BEM_Anf_KL15_schalten_XIX_BEM_02_XIX_E3V_EVCANFD: start 54, 2 bit, little-endian, data-type-policy=OVERRIDE, i-signal-type=PRIMITIVE, init-value=0, base-type=BT_BEM_Anf_KL15_schalten, compu {0=Cx0_Keine_Einschraenkung_Kl15 (CM_BEM_Anf_KL15_schalten_Cx0_Keine_Einschraenkung_Kl15), 1=Cx1_Empfehlung_auto_Abschaltung_Kl15 (CM_BEM_Anf_KL15_schalten_Cx1_Empfehlung_auto_Abschaltung_Kl15), 2=Cx2_Veto_auto_Abschaltung_Kl15 (CM_BEM_Anf_KL15_schalten_Cx2_Veto_auto_Abschaltung_Kl15), 3=Cx3_Veto_auto_Abschaltung_Fahrtbetrieb (CM_BEM_Anf_KL15_schalten_Cx3_Veto_auto_Abschaltung_Fahrtbetrieb)}, range raw 0..3, transfer-property=PENDING  # Abschaltempfehlung bzw. Verhinderung der automatischen Abschaltung Kl15 durch das BCM
          signal NVEM_Batterie_Service_XIX_BEM_02_XIX_E3V_EVCANFD: start 56, 2 bit, little-endian, data-type-policy=OVERRIDE, i-signal-type=PRIMITIVE, init-value=0, base-type=BT_NVEM_Batterie_Service, compu {0=Cx0_kein_Service (CM_NVEM_Batterie_Service_Cx0_kein_Service), 1=Cx1_Service_Information1 (CM_NVEM_Batterie_Service_Cx1_Service_Information1), 2=Cx2_Service_Information2 (CM_NVEM_Batterie_Service_Cx2_Service_Information2), 3=Cx3_Service_Information3 (CM_NVEM_Batterie_Service_Cx3_Service_Information3)}, range raw 0..3, transfer-property=PENDING  # Anforderung einer Batterie-Service - Anzeige / Anforderung an die Werkstatt über MOD
          signal NVEM_Freigabe_OnlineUpdate_XIX_BEM_02_XIX_E3V_EVCANFD: start 58, 1 bit, little-endian, data-type-policy=OVERRIDE, i-signal-type=PRIMITIVE, init-value=0, base-type=BT_NVEM_Freigabe_OnlineUpdate, compu {0=Cx0_keine_Freigabe (CM_NVEM_Freigabe_OnlineUpdate_Cx0_keine_Freigabe), 1=Cx1_Freigabe (CM_NVEM_Freigabe_OnlineUpdate_Cx1_Freigabe)}, range raw 0..1, transfer-property=PENDING  # Freigabe für Online-Update durch Energiemanagement
          signal NVEM_Freigabe_ORU4_XIX_BEM_02_XIX_E3V_EVCANFD: start 59, 2 bit, little-endian, data-type-policy=OVERRIDE, i-signal-type=PRIMITIVE, init-value=0, base-type=BT_NVEM_Freigabe_ORU4, compu {0=Cx0_Init (CM_NVEM_Freigabe_ORU4_Cx0_Init), 1=Cx1_keine_Freigabe (CM_NVEM_Freigabe_ORU4_Cx1_keine_Freigabe), 2=Cx2_Freigabe_erteilt (CM_NVEM_Freigabe_ORU4_Cx2_Freigabe_erteilt), 3=Cx3_Veto_Freigabe (CM_NVEM_Freigabe_ORU4_Cx3_Veto_Freigabe)}, range raw 0..3, transfer-property=PENDING  # Bestätigung oder Ablehnung eines konkreten, angefragten Online Updates durch das Energiemanagements
          signal NVEM_Verbraucherabsch_Anz_XIX_BEM_02_XIX_E3V_EVCANFD: start 61, 1 bit, little-endian, data-type-policy=OVERRIDE, i-signal-type=PRIMITIVE, init-value=0, base-type=BT_NVEM_Verbraucherabsch_Anz, compu {0=Cx0_keine_Anzeige (CM_NVEM_Verbraucherabsch_Anz_Cx0_keine_Anzeige), 1=Cx1_Anzeige_aktiv (CM_NVEM_Verbraucherabsch_Anz_Cx1_Anzeige_aktiv)}, range raw 0..1, transfer-property=PENDING  # Information über eine Verbraucherbschaltung durch das Energiemanagement
          signal NVEM_HV_Stuetzung_aktiv_XIX_BEM_02_XIX_E3V_EVCANFD: start 62, 2 bit, little-endian, data-type-policy=OVERRIDE, i-signal-type=PRIMITIVE, init-value=2, base-type=BT_NVEM_HV_Stuetzung_aktiv, invalid-value=Invalid_NVEM_HV_Stuetzung_aktiv_XIX_BEM_02_XIX_E3V_EVCANFD:3, compu {0=Cx0_HV_OFF (CM_NVEM_HV_Stuetzung_aktiv_Cx0_HV_OFF), 1=Cx1_HV_ON (CM_NVEM_HV_Stuetzung_aktiv_Cx1_HV_ON), 2=Cx2_INIT (CM_NVEM_HV_Stuetzung_aktiv_Cx2_INIT), 3=Cx3_Fehler (CM_NVEM_HV_Stuetzung_aktiv_Cx3_Fehler)}, range raw 0..3, transfer-property=PENDING  # signal from ICAS1 to ICAS3 to inform about status of support of HV for NV system
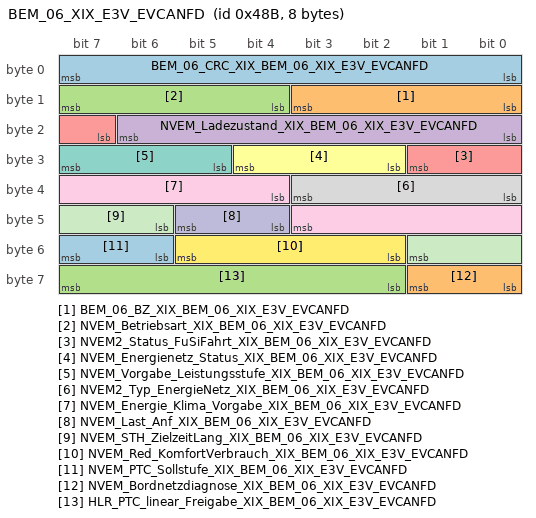
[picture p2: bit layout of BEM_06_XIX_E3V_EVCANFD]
      frame BEM_06_XIX_E3V_EVCANFD: id 0x48B, to Klima, frame-length=8, can-addressing-mode=STANDARD, can-frame-rx-behavior=CAN-FD, can-frame-tx-behavior=CAN-FD
        pdu BEM_06_XIX_E3V_EVCANFD: length=8, transmission-mode-true-timing=cyclic-timing={time-offset=0.0, time-period=0.1}, unused-bit-pattern=0
          signal BEM_06_CRC_XIX_BEM_06_XIX_E3V_EVCANFD: start 0, 8 bit, little-endian, data-type-policy=OVERRIDE, i-signal-type=PRIMITIVE, base-type=BT_BEM_06_CRC, compu {phys=raw for raw 0..255}, range phys 0..255, raw 0..255, transfer-property=PENDING  # Für MLB: Berechnung siehe Lastenheft "Kommunikationsabsicherung für FlexRay und CAN" Ab MQB und MLBevo: Berechnung siehe Lastenheft "End-to-End Kommunikationsabsicherung" Endwerte siehe Begleitdokument "S-PDU Kennungsfolgen"
          signal BEM_06_BZ_XIX_BEM_06_XIX_E3V_EVCANFD: start 8, 4 bit, little-endian, data-type-policy=OVERRIDE, i-signal-type=PRIMITIVE, base-type=BT_BEM_06_BZ, compu {phys=raw for raw 0..15}, range phys 0..15, raw 0..15, transfer-property=PENDING  # 4bit Botschaftszähler, wird mit jeder Sendebotschaft inkrementiert
          signal NVEM_Betriebsart_XIX_BEM_06_XIX_E3V_EVCANFD: start 12, 4 bit, little-endian, data-type-policy=OVERRIDE, i-signal-type=PRIMITIVE, init-value=0, base-type=BT_NVEM_Betriebsart, invalid-value=Invalid_NVEM_Betriebsart_XIX_BEM_06_XIX_E3V_EVCANFD:15, compu {0=Cx0_oKl15_Sing_oVerbr (CM_NVEM_Betriebsart_Cx0_oKl15_Sing_oVerbr), 1=Cx1_oKl15_Red_RedKontingent_oVerbr (CM_NVEM_Betriebsart_Cx1_oKl15_Red_RedKontingent_oVerbr), 2=Cx2_oKl15_Red_HohKontingent_oVerbr (CM_NVEM_Betriebsart_Cx2_oKl15_Red_HohKontingent_oVerbr), 3=Cx3_oKl15_Red_mVerbr (CM_NVEM_Betriebsart_Cx3_oKl15_Red_mVerbr), 4=Cx4_reserved (CM_NVEM_Betriebsart_Cx4_reserved), 5=Cx5_reserved (CM_NVEM_Betriebsart_Cx5_reserved), 6=Cx6_reserved (CM_NVEM_Betriebsart_Cx6_reserved), 7=Cx7_reserved (CM_NVEM_Betriebsart_Cx7_reserved), 8=Cx8_mKl15_Sing_oVerbr (CM_NVEM_Betriebsart_Cx8_mKl15_Sing_oVerbr), 9=Cx9_mKl15_Red_RedKontingent_oVerbr (CM_NVEM_Betriebsart_Cx9_mKl15_Red_RedKontingent_oVerbr), 10=Cxa_mKl15_Red_HohKontingent_oVerbr (CM_NVEM_Betriebsart_Cxa_mKl15_Red_HohKontingent_oVerbr), 11=Cxb_mKl15_Red_mVerbr (CM_NVEM_Betriebsart_Cxb_mKl15_Red_mVerbr), 12=Cxc_Fahrbereitschaft_mVerbr (CM_NVEM_Betriebsart_Cxc_Fahrbereitschaft_mVerbr), 13=Cxd_reserved (CM_NVEM_Betriebsart_Cxd_reserved), 14=Cxe_reserved (CM_NVEM_Betriebsart_Cxe_reserved), 15=Cxf_Fehler (CM_NVEM_Betriebsart_Cxf_Fehler)}, range raw 0..15, transfer-property=PENDING  # Betriebsart des Niedervolt - Energiemanagements
          signal NVEM_Ladezustand_XIX_BEM_06_XIX_E3V_EVCANFD: start 16, 7 bit, little-endian, data-type-policy=OVERRIDE, i-signal-type=PRIMITIVE, init-value=126, base-type=BT_NVEM_Ladezustand, invalid-value=Invalid_NVEM_Ladezustand_XIX_BEM_06_XIX_E3V_EVCANFD:127, compu {phys=raw for raw 0..100, 126=Cx7e_INIT (CM_NVEM_Ladezustand_Cx7e_INIT), 127=Cx7f_Fehler (CM_NVEM_Ladezustand_Cx7f_Fehler); unit Unit_PerCent}, range phys 0..100 Unit_PerCent, raw 0..127, unit=Unit_PerCent, transfer-property=PENDING  # Ladezustand des NV-Hauptspeichers.
          signal NVEM2_Status_FuSiFahrt_XIX_BEM_06_XIX_E3V_EVCANFD: start 23, 3 bit, little-endian, data-type-policy=OVERRIDE, i-signal-type=PRIMITIVE, init-value=0, base-type=BT_NVEM2_Status_FuSiFahrt, invalid-value=Invalid_NVEM2_Status_FuSiFahrt_XIX_BEM_06_XIX_E3V_EVCANFD:7, compu {0=Cx0_Init (CM_NVEM2_Status_FuSiFahrt_Cx0_Init), 1=Cx1_Keine_FuSi_Fahrt (CM_NVEM2_Status_FuSiFahrt_Cx1_Keine_FuSi_Fahrt), 2=Cx2_Qualifikation_FuSi_Fahrt (CM_NVEM2_Status_FuSiFahrt_Cx2_Qualifikation_FuSi_Fahrt), 3=Cx3_FuSi_Fahrt_Aktiv (CM_NVEM2_Status_FuSiFahrt_Cx3_FuSi_Fahrt_Aktiv), 4=Cx4_Qualifikation_Ende_FuSi_Fahrt (CM_NVEM2_Status_FuSiFahrt_Cx4_Qualifikation_Ende_FuSi_Fahrt), 5=Cx5_FuSi_Stand (CM_NVEM2_Status_FuSiFahrt_Cx5_FuSi_Stand), 6=Cx6_FuSi_Nachlauf (CM_NVEM2_Status_FuSiFahrt_Cx6_FuSi_Nachlauf), 7=Cx7_Fehler (CM_NVEM2_Status_FuSiFahrt_Cx7_Fehler)}, range raw 0..7, transfer-property=PENDING  # Status sicherheitsrelevante Diagnosen NVEM
          signal NVEM_Energienetz_Status_XIX_BEM_06_XIX_E3V_EVCANFD: start 26, 3 bit, little-endian, data-type-policy=OVERRIDE, i-signal-type=PRIMITIVE, init-value=6, base-type=BT_NVEM_Energienetz_Status, invalid-value=Invalid_NVEM_Energienetz_Status_XIX_BEM_06_XIX_E3V_EVCANFD:7, compu {0=Cx0_QM (CM_NVEM_Energienetz_Status_Cx0_QM), 1=Cx1_ASIL_A (CM_NVEM_Energienetz_Status_Cx1_ASIL_A), 2=Cx2_ASIL_B (CM_NVEM_Energienetz_Status_Cx2_ASIL_B), 3=Cx3_ASIL_C (CM_NVEM_Energienetz_Status_Cx3_ASIL_C), 6=Cx6_InitWert (CM_NVEM_Energienetz_Status_Cx6_InitWert), 7=Cx7_Fehler (CM_NVEM_Energienetz_Status_Cx7_Fehler)}, range raw 0..7, transfer-property=PENDING  # NVEM kommuniziert abgesichert den Zustand des Energienetzes.
          signal NVEM_Vorgabe_Leistungsstufe_XIX_BEM_06_XIX_E3V_EVCANFD: start 29, 3 bit, little-endian, data-type-policy=OVERRIDE, i-signal-type=PRIMITIVE, init-value=0, base-type=BT_NVEM_Vorgabe_Leistungsstufe, invalid-value=Invalid_NVEM_Vorgabe_Leistungsstufe_XIX_BEM_06_XIX_E3V_EVCANFD:7, compu {0=Cx0_Init (CM_NVEM_Vorgabe_Leistungsstufe_Cx0_Init), 1=Cx1_Leistungsstufe_0 (CM_NVEM_Vorgabe_Leistungsstufe_Cx1_Leistungsstufe_0), 2=Cx2_Leistungsstufe_1 (CM_NVEM_Vorgabe_Leistungsstufe_Cx2_Leistungsstufe_1), 3=Cx3_Leistungsstufe_2 (CM_NVEM_Vorgabe_Leistungsstufe_Cx3_Leistungsstufe_2), 4=Cx4_Leistungsstufe_3 (CM_NVEM_Vorgabe_Leistungsstufe_Cx4_Leistungsstufe_3), 5=Cx5_Leistungsstufe_4 (CM_NVEM_Vorgabe_Leistungsstufe_Cx5_Leistungsstufe_4), 6=Cx6_Leistungsstufe_5 (CM_NVEM_Vorgabe_Leistungsstufe_Cx6_Leistungsstufe_5), 7=Cx7_Fehler (CM_NVEM_Vorgabe_Leistungsstufe_Cx7_Fehler)}, range raw 0..7, transfer-property=PENDING  # Ermittelte Leistungsstufe der Energiequelle
          signal NVEM2_Typ_EnergieNetz_XIX_BEM_06_XIX_E3V_EVCANFD: start 32, 4 bit, little-endian, data-type-policy=OVERRIDE, i-signal-type=PRIMITIVE, init-value=0, base-type=BT_NVEM2_Typ_EnergieNetz, invalid-value=Invalid_NVEM2_Typ_EnergieNetz_XIX_BEM_06_XIX_E3V_EVCANFD:14, compu {0=Cx0_Sp12V_Gen_ICE (CM_NVEM2_Typ_EnergieNetz_Cx0_Sp12V_Gen_ICE), 1=Cx1_Sp12V_BEV (CM_NVEM2_Typ_EnergieNetz_Cx1_Sp12V_BEV), 2=Cx2_Sp12V_PHEV (CM_NVEM2_Typ_EnergieNetz_Cx2_Sp12V_PHEV), 3=Cx3_Sp12V_MHEV (CM_NVEM2_Typ_EnergieNetz_Cx3_Sp12V_MHEV), 4=Cx4_Sp12V_HEV (CM_NVEM2_Typ_EnergieNetz_Cx4_Sp12V_HEV), 5=Cx5_Sp12V_Sp48V_Gen_Insel (CM_NVEM2_Typ_EnergieNetz_Cx5_Sp12V_Sp48V_Gen_Insel), 6=Cx6_Sp12V_Sp12V_RSG_MHEV12V (CM_NVEM2_Typ_EnergieNetz_Cx6_Sp12V_Sp12V_RSG_MHEV12V), 7=Cx7_Sp12V_BEV_ASILC (CM_NVEM2_Typ_EnergieNetz_Cx7_Sp12V_BEV_ASILC), 14=Cxe_Fehler (CM_NVEM2_Typ_EnergieNetz_Cxe_Fehler), 15=Cxf_Init (CM_NVEM2_Typ_EnergieNetz_Cxf_Init)}, range raw 0..15, transfer-property=PENDING  # Identifizierte NV-Energiearchitektur
          signal NVEM_Energie_Klima_Vorgabe_XIX_BEM_06_XIX_E3V_EVCANFD: start 36, 8 bit, little-endian, data-type-policy=OVERRIDE, i-signal-type=PRIMITIVE, init-value=254, base-type=BT_NVEM_Energie_Klima_Vorgabe, invalid-value=Invalid_NVEM_Energie_Klima_Vorgabe_XIX_BEM_06_XIX_E3V_EVCANFD:255, compu {phys=raw*10 for raw 0..253, 254=Cxfe_Init (CM_NVEM_Energie_Klima_Vorgabe_Cxfe_Init), 255=Cxff_Fehler (CM_NVEM_Energie_Klima_Vorgabe_Cxff_Fehler); unit Unit_WattHour}, range phys 0..2530 Unit_WattHour, raw 0..255, unit=Unit_WattHour, transfer-property=PENDING  # NVEM-Energievorgabe für Klima-Vorkonditionierung
          signal NVEM_Last_Anf_XIX_BEM_06_XIX_E3V_EVCANFD: start 44, 2 bit, little-endian, data-type-policy=OVERRIDE, i-signal-type=PRIMITIVE, init-value=0, base-type=BT_NVEM_Last_Anf, compu {0=Cx0_keine_Anforderung (CM_NVEM_Last_Anf_Cx0_keine_Anforderung) (keine Anforderung), 1=Cx1_Verbraucher_Anforderung_Stufe_1 (CM_NVEM_Last_Anf_Cx1_Verbraucher_Anforderung_Stufe_1), 2=Cx2_Verbraucher_Anforderung_Stufe_2 (CM_NVEM_Last_Anf_Cx2_Verbraucher_Anforderung_Stufe_2), 3=Cx3_Verbraucher_Anforderung_Stufe_3 (CM_NVEM_Last_Anf_Cx3_Verbraucher_Anforderung_Stufe_3)}, range raw 0..3, transfer-property=PENDING, to Klima(timeout 1 s)  # Das NVEM fordert für die Batteriediagnose einen Lastimpuls vom Fahrzeug an, der durch kontrollierte Verbraucherzuschaltungen (z. B. Aktivierung Heckscheibenheizung) generiert wird
          signal NVEM_STH_ZielzeitLang_XIX_BEM_06_XIX_E3V_EVCANFD: start 46, 4 bit, little-endian, data-type-policy=OVERRIDE, i-signal-type=PRIMITIVE, init-value=14, base-type=BT_NVEM_STH_ZielzeitLang, invalid-value=Invalid_NVEM_STH_ZielzeitLang_XIX_BEM_06_XIX_E3V_EVCANFD:15, compu {phys=raw*10 for raw 0..12, 14=Cxe_Init (CM_NVEM_STH_ZielzeitLang_Cxe_Init), 15=Cxf_Fehler (CM_NVEM_STH_ZielzeitLang_Cxf_Fehler); unit Unit_Minut}, range phys 0..120 Unit_Minut, raw 0..15, unit=Unit_Minut, transfer-property=PENDING  # Energetisch erlaubte Betriebszeit im Zielzeitkonzept für Standheizungen mit 2 Stunden Laufzeit
          signal NVEM_Red_KomfortVerbrauch_XIX_BEM_06_XIX_E3V_EVCANFD: start 50, 4 bit, little-endian, data-type-policy=OVERRIDE, i-signal-type=PRIMITIVE, init-value=0, base-type=BT_NVEM_Red_KomfortVerbrauch, invalid-value=Invalid_NVEM_Red_KomfortVerbrauch_XIX_BEM_06_XIX_E3V_EVCANFD:15, compu {0=Cx0_keine_Einschraenkung (CM_NVEM_Red_KomfortVerbrauch_Cx0_keine_Einschraenkung), 1=Cx1_Einschraenkung_Stufe_1 (CM_NVEM_Red_KomfortVerbrauch_Cx1_Einschraenkung_Stufe_1), 2=Cx2_Einschraenkung_Stufe_2 (CM_NVEM_Red_KomfortVerbrauch_Cx2_Einschraenkung_Stufe_2), 3=Cx3_Einschraenkung_Stufe_3 (CM_NVEM_Red_KomfortVerbrauch_Cx3_Einschraenkung_Stufe_3), 4=Cx4_Einschraenkung_Stufe_4 (CM_NVEM_Red_KomfortVerbrauch_Cx4_Einschraenkung_Stufe_4), 5=Cx5_Einschraenkung_Stufe_5 (CM_NVEM_Red_KomfortVerbrauch_Cx5_Einschraenkung_Stufe_5), 6=Cx6_Einschraenkung_Stufe_6 (CM_NVEM_Red_KomfortVerbrauch_Cx6_Einschraenkung_Stufe_6), 7=Cx7_Einschraenkung_Stufe_7 (CM_NVEM_Red_KomfortVerbrauch_Cx7_Einschraenkung_Stufe_7), 8=Cx8_Einschraenkung_Stufe_8 (CM_NVEM_Red_KomfortVerbrauch_Cx8_Einschraenkung_Stufe_8), 15=Cxf_Fehler (CM_NVEM_Red_KomfortVerbrauch_Cxf_Fehler)}, range raw 0..15, transfer-property=PENDING  # Master - SubMaster Kommunikation
          signal NVEM_PTC_Sollstufe_XIX_BEM_06_XIX_E3V_EVCANFD: start 54, 2 bit, little-endian, data-type-policy=OVERRIDE, i-signal-type=PRIMITIVE, init-value=0, base-type=BT_NVEM_PTC_Sollstufe, compu {0=Cx0_Aus (CM_NVEM_PTC_Sollstufe_Cx0_Aus), 1=Cx1_Stufe_1 (CM_NVEM_PTC_Sollstufe_Cx1_Stufe_1), 2=Cx2_Stufe_2 (CM_NVEM_PTC_Sollstufe_Cx2_Stufe_2), 3=Cx3_Stufe_3 (CM_NVEM_PTC_Sollstufe_Cx3_Stufe_3)}, range raw 0..3, transfer-property=PENDING  # Vorgabe des BEM an das BCM zur Aktivierung der geforderten PTC - Stufe. Das MSG kopiert dies auf das Signal MO_PTC_Status
          signal NVEM_Bordnetzdiagnose_XIX_BEM_06_XIX_E3V_EVCANFD: start 56, 2 bit, little-endian, data-type-policy=OVERRIDE, i-signal-type=PRIMITIVE, init-value=0, base-type=BT_NVEM_Bordnetzdiagnose, compu {0=Cx0_kein_Fehler (CM_NVEM_Bordnetzdiagnose_Cx0_kein_Fehler), 1=Cx1_Warnung_1 (CM_NVEM_Bordnetzdiagnose_Cx1_Warnung_1), 2=Cx2_Warnung_2 (CM_NVEM_Bordnetzdiagnose_Cx2_Warnung_2), 3=Cx3_Warnung_3 (CM_NVEM_Bordnetzdiagnose_Cx3_Warnung_3)}, range raw 0..3, transfer-property=PENDING  # Wird vom NVEM im NV-Netz ein Bordnetz-Fehler erkannt, so soll dies zu einer mehrstufigen Anzeige führen.
          signal HLR_PTC_linear_Freigabe_XIX_BEM_06_XIX_E3V_EVCANFD: start 58, 6 bit, little-endian, data-type-policy=OVERRIDE, i-signal-type=PRIMITIVE, init-value=0, base-type=BT_HLR_PTC_linear_Freigabe, invalid-value=Invalid_HLR_PTC_linear_Freigabe_XIX_BEM_06_XIX_E3V_EVCANFD:63, compu {phys=raw*50 for raw 0..62, 63=Cx3f_Fehler (CM_HLR_PTC_linear_Freigabe_Cx3f_Fehler); unit Unit_Watt}, range phys 0..3100 Unit_Watt, raw 0..63, unit=Unit_Watt, transfer-property=PENDING  # Freigabe des EEM für den linearen PTC-Zuheizer
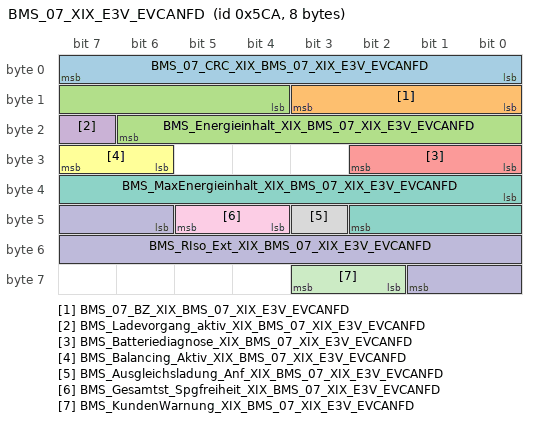
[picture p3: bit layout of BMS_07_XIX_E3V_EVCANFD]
      frame BMS_07_XIX_E3V_EVCANFD: id 0x5CA, to Klima, frame-length=8, can-addressing-mode=STANDARD, can-frame-rx-behavior=CAN-FD, can-frame-tx-behavior=CAN-FD
        pdu BMS_07_XIX_E3V_EVCANFD: length=8, minimum-delay=0.05, transmission-mode-true-timing={cyclic-timing={time-offset=0.0, time-period=0.5}, event-controlled-timing={number-of-repetitions=0, repetition-period=0.0}}, unused-bit-pattern=0
          signal BMS_07_CRC_XIX_BMS_07_XIX_E3V_EVCANFD: start 0, 8 bit, little-endian, data-type-policy=OVERRIDE, i-signal-type=PRIMITIVE, base-type=BT_BMS_07_CRC, compu {phys=raw for raw 0..255}, range phys 0..255, raw 0..255, transfer-property=PENDING  # Für MLB: "Berechnung siehe Lastenheft "Kommunikationsabsicherung für FlexRay und CAN"" Ab MQB und MLBevo: "Berechnung siehe Lastenheft "End-to-End Kommunikationsabsicherung"" Endwerte siehe Begleitdokument "S-PDU Kennungsfolgen"
          signal BMS_07_BZ_XIX_BMS_07_XIX_E3V_EVCANFD: start 8, 4 bit, little-endian, data-type-policy=OVERRIDE, i-signal-type=PRIMITIVE, base-type=BT_BMS_07_BZ, compu {phys=raw for raw 0..15}, range phys 0..15, raw 0..15, transfer-property=PENDING
          signal BMS_Energieinhalt_XIX_BMS_07_XIX_E3V_EVCANFD: start 12, 11 bit, little-endian, data-type-policy=OVERRIDE, i-signal-type=PRIMITIVE, init-value=2046, base-type=BT_BMS_Energieinhalt, invalid-value=Invalid_BMS_Energieinhalt_XIX_BMS_07_XIX_E3V_EVCANFD:2047, compu {phys=raw*50 for raw 0..2045, 2046=Cx7fe_Init (CM_BMS_Energieinhalt_Cx7fe_Init), 2047=Cx7ff_Fehler (CM_BMS_Energieinhalt_Cx7ff_Fehler); unit Unit_WattHour}, range phys 0..102250 Unit_WattHour, raw 0..2047, unit=Unit_WattHour, transfer-property=PENDING  # aktuell nutzbarer Energieinhalt der HV-Batterie (bezogen auf ein definiertes mittleres Belastungsprofil)
          signal BMS_Ladevorgang_aktiv_XIX_BMS_07_XIX_E3V_EVCANFD: start 23, 1 bit, little-endian, data-type-policy=OVERRIDE, i-signal-type=PRIMITIVE, init-value=0, base-type=BT_BMS_Ladevorgang_aktiv, compu {0=Cx0_inaktiv (CM_BMS_Ladevorgang_aktiv_Cx0_inaktiv), 1=Cx1_aktiv (CM_BMS_Ladevorgang_aktiv_Cx1_aktiv)}, range raw 0..1, transfer-property=PENDING  # Signalisiert aktiven Ladevorgang, Ladegerät und DC/DC aktiv. Signal bleibt nach Kl.15 ein aktiv, bis ESP_Stillstandsflag gelöscht. Abhängigkeit zu BMS_Energieinhalt
          signal BMS_Batteriediagnose_XIX_BMS_07_XIX_E3V_EVCANFD: start 24, 3 bit, little-endian, data-type-policy=OVERRIDE, i-signal-type=PRIMITIVE, init-value=1, base-type=BT_BMS_Batteriediagnose, invalid-value=Invalid_BMS_Batteriediagnose_XIX_BMS_07_XIX_E3V_EVCANFD:7, compu {1=Cx1_Anzeige_Batterie (CM_BMS_Batteriediagnose_Cx1_Anzeige_Batterie), 4=Cx4_Anzeige_Batterie_OK (CM_BMS_Batteriediagnose_Cx4_Anzeige_Batterie_OK), 5=Cx5_Anzeige_Batterie_Laden (CM_BMS_Batteriediagnose_Cx5_Anzeige_Batterie_Laden), 6=Cx6_Anzeige_Batterie_Pruefen (CM_BMS_Batteriediagnose_Cx6_Anzeige_Batterie_Pruefen), 7=Cx7_Fehler (CM_BMS_Batteriediagnose_Cx7_Fehler)}, range raw 1..7, transfer-property=TRIGGERED-ON-CHANGE-WITHOUT-REPETITION  # Anzeige von Textwarnungen
          signal BMS_Balancing_Aktiv_XIX_BMS_07_XIX_E3V_EVCANFD: start 30, 2 bit, little-endian, data-type-policy=OVERRIDE, i-signal-type=PRIMITIVE, init-value=0, base-type=BT_BMS_Balancing_Aktiv, compu {0=Cx0_Init (CM_BMS_Balancing_Aktiv_Cx0_Init), 1=Cx1_aktiv (CM_BMS_Balancing_Aktiv_Cx1_aktiv), 2=Cx2_nicht_aktiv (CM_BMS_Balancing_Aktiv_Cx2_nicht_aktiv)}, range raw 0..2, transfer-property=PENDING  # Signal zeigt an, ob mindestens eine Zelle der HV Batterie balanciert wird
          signal BMS_MaxEnergieinhalt_XIX_BMS_07_XIX_E3V_EVCANFD: start 32, 11 bit, little-endian, data-type-policy=OVERRIDE, i-signal-type=PRIMITIVE, init-value=2046, base-type=BT_BMS_MaxEnergieinhalt, invalid-value=Invalid_BMS_MaxEnergieinhalt_XIX_BMS_07_XIX_E3V_EVCANFD:2047, compu {phys=raw*50 for raw 0..2045, 2046=Cx7fe_Init (CM_BMS_MaxEnergieinhalt_Cx7fe_Init), 2047=Cx7ff_Fehler (CM_BMS_MaxEnergieinhalt_Cx7ff_Fehler); unit Unit_WattHour}, range phys 0..102250 Unit_WattHour, raw 0..2047, unit=Unit_WattHour, transfer-property=PENDING  # maximaler nutzbarer Energieinhalt der HV-Batterie (bezogen auf Last KBI_RWDS_Lastprofil bei SOC=100%) Abhängig von KBI_RWDS_Lastprofil
          signal BMS_Ausgleichsladung_Anf_XIX_BMS_07_XIX_E3V_EVCANFD: start 43, 1 bit, little-endian, data-type-policy=OVERRIDE, i-signal-type=PRIMITIVE, init-value=0, base-type=BT_BMS_Ausgleichsladung_Anf, compu {1=Cx1_Balancing_Request (CM_BMS_Ausgleichsladung_Anf_Cx1_Balancing_Request)}, range raw 1, transfer-property=PENDING  # BMS wünscht eine Ausgleichsladung Flag derzeit ungenutzt, da BalancingModus im Detail noch nicht geklärt.
          signal BMS_Gesamtst_Spgfreiheit_XIX_BMS_07_XIX_E3V_EVCANFD: start 44, 2 bit, little-endian, data-type-policy=OVERRIDE, i-signal-type=PRIMITIVE, init-value=0, base-type=BT_BMS_Gesamtst_Spgfreiheit, compu {0=Cx0_Funktion_nicht_aktiviert (CM_BMS_Gesamtst_Spgfreiheit_Cx0_Funktion_nicht_aktiviert), 1=Cx1_HV_System_spannungsfrei (CM_BMS_Gesamtst_Spgfreiheit_Cx1_HV_System_spannungsfrei), 2=Cx2_HV_System_nicht_spannungsfrei (CM_BMS_Gesamtst_Spgfreiheit_Cx2_HV_System_nicht_spannungsfrei), 3=Cx3_Fehler_nicht_spannungsfrei (CM_BMS_Gesamtst_Spgfreiheit_Cx3_Fehler_nicht_spannungsfrei)}, range raw 0..3, transfer-property=TRIGGERED-ON-CHANGE-WITHOUT-REPETITION  # 0 = Funktion nicht aktiviert 1 = HV-System spannungsfrei (U_Zwkr von BMS, LE und Ladegerät < 20V, DCLadestecker nicht gesteckt und Service Disconnect entriegelt) 2 = HV-System nicht spannungsfrei (U_Zwkr von BMS, LE und Ladegerät >= 20V, Ladestecker gesteckt oder Service Disconnect verriegelt) 3 = Fehler (z. B. Fehler in der eigenen Sensorik, ein Signal fehlt oder Fehler in Leistungselektronik oder Ladegerät)
          signal BMS_RIso_Ext_XIX_BMS_07_XIX_E3V_EVCANFD: start 46, 12 bit, little-endian, data-type-policy=OVERRIDE, i-signal-type=PRIMITIVE, init-value=4094, base-type=BT_BMS_RIso_Ext, invalid-value=Invalid_BMS_RIso_Ext_XIX_BMS_07_XIX_E3V_EVCANFD:4095, compu {phys=raw*5 for raw 0..4093, 4094=Cxffe_Init (CM_BMS_RIso_Ext_Cxffe_Init), 4095=Cxfff_Fehler (CM_BMS_RIso_Ext_Cxfff_Fehler); unit Unit_KiloOhm}, range phys 0..20465 Unit_KiloOhm, raw 0..4095, unit=Unit_KiloOhm, transfer-property=PENDING  # Minimum des Isolationswiderstands zwischen Batteriegehäuse und HV+ bzw. Batteriegehäuse und HV- bei geschlossenen Schützen (externe Iso Messung)
          signal BMS_KundenWarnung_XIX_BMS_07_XIX_E3V_EVCANFD: start 58, 2 bit, little-endian, data-type-policy=OVERRIDE, i-signal-type=PRIMITIVE, init-value=0, base-type=BT_BMS_KundenWarnung, compu {0=Cx0_keine_Warnung (CM_BMS_KundenWarnung_Cx0_keine_Warnung), 1=Cx1_Warnung_Temperatur_Level1 (CM_BMS_KundenWarnung_Cx1_Warnung_Temperatur_Level1), 2=Cx2_Warnung_Temperatur_Level2 (CM_BMS_KundenWarnung_Cx2_Warnung_Temperatur_Level2)}, range raw 0..2, transfer-property=TRIGGERED-ON-CHANGE-WITHOUT-REPETITION, to Klima(timeout 5 s)  # Kundenwarnung und Ersatzreaktionen aufgrund von Batteriebrandgefahr
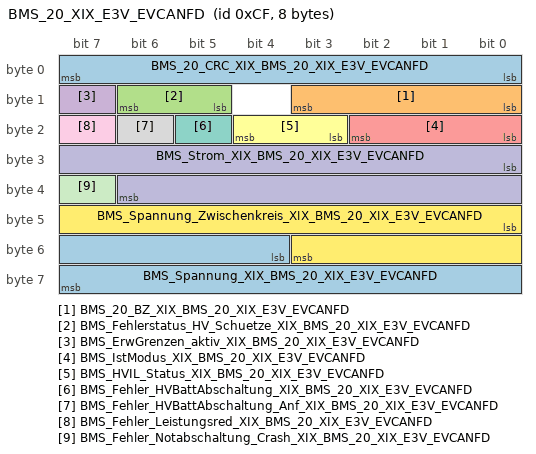
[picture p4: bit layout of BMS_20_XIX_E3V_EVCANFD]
      frame BMS_20_XIX_E3V_EVCANFD: id 0xCF, to Klima, frame-length=8, can-addressing-mode=STANDARD, can-frame-rx-behavior=CAN-FD, can-frame-tx-behavior=CAN-FD
        pdu BMS_20_XIX_E3V_EVCANFD: length=8, transmission-mode-true-timing=cyclic-timing={time-offset=0.0, time-period=0.01}, unused-bit-pattern=0
          signal BMS_20_CRC_XIX_BMS_20_XIX_E3V_EVCANFD: start 0, 8 bit, little-endian, data-type-policy=OVERRIDE, i-signal-type=PRIMITIVE, base-type=BT_BMS_20_CRC, compu {phys=raw for raw 0..255}, range phys 0..255, raw 0..255, transfer-property=PENDING  # Für MLB: Berechnung siehe Lastenheft "Kommunikationsabsicherung für FlexRay und CAN" Ab MQB und MLBevo: Berechnung siehe Lastenheft "End-to-End Kommunikationsabsicherung" Endwerte siehe Begleitdokument "S-PDU Kennungsfolgen"
          signal BMS_20_BZ_XIX_BMS_20_XIX_E3V_EVCANFD: start 8, 4 bit, little-endian, data-type-policy=OVERRIDE, i-signal-type=PRIMITIVE, base-type=BT_BMS_20_BZ, compu {phys=raw for raw 0..15}, range phys 0..15, raw 0..15, transfer-property=PENDING  # 4bit Botschaftszähler, wird mit jeder Sendebotschaft inkrementiert
          signal BMS_Fehlerstatus_HV_Schuetze_XIX_BMS_20_XIX_E3V_EVCANFD: start 13, 2 bit, little-endian, data-type-policy=OVERRIDE, i-signal-type=PRIMITIVE, init-value=0, base-type=BT_BMS_Fehlerstatus_HV_Schuetze, compu {0=Cx0_Init_kein_Diagnoseergebnis (CM_BMS_Fehlerstatus_HV_Schuetze_Cx0_Init_kein_Diagnoseergebnis), 1=Cx1_kein_Schuetz_verschweisst (CM_BMS_Fehlerstatus_HV_Schuetze_Cx1_kein_Schuetz_verschweisst), 2=Cx2_mind_1_Schuetz_verschweisst (CM_BMS_Fehlerstatus_HV_Schuetze_Cx2_mind_1_Schuetz_verschweisst), 3=Cx3_Fehler_Schuetzstatuserkennung (CM_BMS_Fehlerstatus_HV_Schuetze_Cx3_Fehler_Schuetzstatuserkennung)}, range raw 0..3, transfer-property=PENDING  # Fehlerstatus der HV-Schütze, Verschweißt-Erkennung
          signal BMS_ErwGrenzen_aktiv_XIX_BMS_20_XIX_E3V_EVCANFD: start 15, 1 bit, little-endian, data-type-policy=OVERRIDE, i-signal-type=PRIMITIVE, init-value=0, base-type=BT_BMS_ErwGrenzen_aktiv, compu {0=Cx0_Init (CM_BMS_ErwGrenzen_aktiv_Cx0_Init), 1=Cx1_extended_Range (CM_BMS_ErwGrenzen_aktiv_Cx1_extended_Range)}, range raw 0..1, transfer-property=PENDING  # die aktuellen Stromgrenzen der HV-Batterie sind zum Start des Verbrennungsmotors aufgeweitet / Bestätigung der Anforderung
          signal BMS_IstModus_XIX_BMS_20_XIX_E3V_EVCANFD: start 16, 3 bit, little-endian, data-type-policy=OVERRIDE, i-signal-type=PRIMITIVE, init-value=7, base-type=BT_BMS_IstModus, compu {0=Cx0_HV_inaktiv (CM_BMS_IstModus_Cx0_HV_inaktiv), 1=Cx1_Fahren_HV_aktiv (CM_BMS_IstModus_Cx1_Fahren_HV_aktiv), 2=Cx2_stBalancing (CM_BMS_IstModus_Cx2_stBalancing), 3=Cx3_externes_Laden (CM_BMS_IstModus_Cx3_externes_Laden), 4=Cx4_AC_Laden (CM_BMS_IstModus_Cx4_AC_Laden), 5=Cx5_Error_Batt (CM_BMS_IstModus_Cx5_Error_Batt), 6=Cx6_DC_Laden (CM_BMS_IstModus_Cx6_DC_Laden), 7=Cx7_Init (CM_BMS_IstModus_Cx7_Init)}, range raw 0..7, transfer-property=PENDING  # Aktueller Betriebsmodus der Batterie 0: Standby; Schuetze geoeffnet; Kommunikation aktiv 1: Hauptschuetze geschlossen / HV-Netz aktiviert / normaler Fahrbetrieb 2: projektabhaengig belegt (z.B. Balancing, erweitertes DC-Schnelladen) 3: externes Laden ueber Ladegeraet bei unterbrochenem HV-Netz; oder generatorisch ueber MSG (HV-Netz aktiv) 4: AC-Laden / HV Netz aktiv 5: interner Batteriefehler / angeforderter Modus kann nicht eingestellt werden 6: DC-Laden / HV Netz aktiv 7: Initialisierung
          signal BMS_HVIL_Status_XIX_BMS_20_XIX_E3V_EVCANFD: start 19, 2 bit, little-endian, data-type-policy=OVERRIDE, i-signal-type=PRIMITIVE, init-value=0, base-type=BT_BMS_HVIL_Status, invalid-value=Invalid_BMS_HVIL_Status_XIX_BMS_20_XIX_E3V_EVCANFD:3, compu {0=Cx0_Init (CM_BMS_HVIL_Status_Cx0_Init), 1=Cx1_geschlossen (CM_BMS_HVIL_Status_Cx1_geschlossen), 2=Cx2_offen (CM_BMS_HVIL_Status_Cx2_offen), 3=Cx3_Fehler (CM_BMS_HVIL_Status_Cx3_Fehler)}, range raw 0..3, transfer-property=PENDING  # Signalstatus HVIL/Pilotlinie
          signal BMS_Fehler_HVBattAbschaltung_XIX_BMS_20_XIX_E3V_EVCANFD: start 21, 1 bit, little-endian, data-type-policy=OVERRIDE, i-signal-type=PRIMITIVE, init-value=0, base-type=BT_BMS_Fehler_HVBattAbschaltung, compu {1=Cx1_Err_ShutOff (CM_BMS_Fehler_HVBattAbschaltung_Cx1_Err_ShutOff)}, range raw 1, transfer-property=PENDING  # Fehler: Fehlerzustand, erfordert das Öffnen der Batterieschütze interner Batteriefehler, Batterieschütze ohne Vorankündigung durch das BMS geöffnet
          signal BMS_Fehler_HVBattAbschaltung_Anf_XIX_BMS_20_XIX_E3V_EVCANFD: start 22, 1 bit, little-endian, data-type-policy=OVERRIDE, i-signal-type=PRIMITIVE, init-value=0, base-type=BT_BMS_Fehler_HVBattAbschaltung_Anf, compu {1=Cx1_Err_ShutOffRequest (CM_BMS_Fehler_HVBattAbschaltung_Anf_Cx1_Err_ShutOffRequest)}, range raw 1, transfer-property=PENDING  # Fehler: Fehlerzustand, erfordert das Öffnen der Batterieschütze interner Batteriefehler; Vorankündigung eines bevorstehenden Öffnens der Batterieschütze durch das BMS
          signal BMS_Fehler_Leistungsred_XIX_BMS_20_XIX_E3V_EVCANFD: start 23, 1 bit, little-endian, data-type-policy=OVERRIDE, i-signal-type=PRIMITIVE, init-value=0, base-type=BT_BMS_Fehler_Leistungsred, compu {0=Cx0_keine_Leistungseinschraenkung (CM_BMS_Fehler_Leistungsred_Cx0_keine_Leistungseinschraenkung), 1=Cx1_Leistungseinschraenkung (CM_BMS_Fehler_Leistungsred_Cx1_Leistungseinschraenkung)}, range raw 0..1, transfer-property=PENDING  # Fehler: Leistungsfähigkeit der Batterie ist eingeschränkt (z.B. aufgrund des Ausfalls von Sensoren oder des Lüfters)
          signal BMS_Strom_XIX_BMS_20_XIX_E3V_EVCANFD: start 24, 15 bit, little-endian, data-type-policy=OVERRIDE, i-signal-type=PRIMITIVE, init-value=32766, base-type=BT_BMS_Strom, invalid-value=Invalid_BMS_Strom_XIX_BMS_20_XIX_E3V_EVCANFD:32767, compu {phys=raw*0.1-1630 for raw 0..32600, 32765=Cx7ffd_nicht_messbar (CM_BMS_Strom_Cx7ffd_nicht_messbar), 32766=Cx7ffe_Init (CM_BMS_Strom_Cx7ffe_Init), 32767=Cx7fff_Fehler (CM_BMS_Strom_Cx7fff_Fehler); unit Unit_Amper}, range phys -1630..1630 Unit_Amper, raw 0..32767, unit=Unit_Amper, transfer-property=PENDING, to Klima(timeout 0.5 s)  # Aktueller Strom der Batterie. Stromrichtung: Ladestrom wird mit positiven, Entladestrom mit negativen Werten angegeben.
          signal BMS_Fehler_Notabschaltung_Crash_XIX_BMS_20_XIX_E3V_EVCANFD: start 39, 1 bit, little-endian, data-type-policy=OVERRIDE, i-signal-type=PRIMITIVE, init-value=0, base-type=BT_BMS_Fehler_Notabschaltung_Crash, compu {1=Cx1_Err_EmergcyShtOffCrash (CM_BMS_Fehler_Notabschaltung_Crash_Cx1_Err_EmergcyShtOffCrash)}, range raw 1, transfer-property=PENDING  # Fehler: Sicherheitskritischer Fehler (Crash-Erkennung) Batterieschütze sind bereits geöffnet / werden sofort geöffnet Signal wird direkt vom EMS gelesen und initiiert einen AKS des PWR und eine aktive Entladung des Zwischenkreises
          signal BMS_Spannung_Zwischenkreis_XIX_BMS_20_XIX_E3V_EVCANFD: start 40, 12 bit, little-endian, data-type-policy=OVERRIDE, i-signal-type=PRIMITIVE, init-value=4094, base-type=BT_BMS_Spannung_Zwischenkreis, invalid-value=Invalid_BMS_Spannung_Zwischenkreis_XIX_BMS_20_XIX_E3V_EVCANFD:4095, compu {phys=raw*0.5-1000 for raw 0..4000, 4093=Cxffd_nicht_messbar (CM_BMS_Spannung_Zwischenkreis_Cxffd_nicht_messbar), 4094=Cxffe_Init (CM_BMS_Spannung_Zwischenkreis_Cxffe_Init), 4095=Cxfff_Fehler (CM_BMS_Spannung_Zwischenkreis_Cxfff_Fehler); unit Unit_Volt}, range phys -1000..1000 Unit_Volt, raw 0..4095, unit=Unit_Volt, transfer-property=PENDING  # Aktuelle Spannung an den Batterie-HV-Anschlüssen; Abgang der Batterie zum Zwischenkreis / HV-Bordnetz / zur Leistungselektronik.
          signal BMS_Spannung_XIX_BMS_20_XIX_E3V_EVCANFD: start 52, 12 bit, little-endian, data-type-policy=OVERRIDE, i-signal-type=PRIMITIVE, init-value=4094, base-type=BT_BMS_Spannung, invalid-value=Invalid_BMS_Spannung_XIX_BMS_20_XIX_E3V_EVCANFD:4095, compu {phys=raw*0.25 for raw 0..4000, 4093=Cxffd_nicht_messbar (CM_BMS_Spannung_Cxffd_nicht_messbar), 4094=Cxffe_Init (CM_BMS_Spannung_Cxffe_Init), 4095=Cxfff_Fehler (CM_BMS_Spannung_Cxfff_Fehler); unit Unit_Volt}, range phys 0..1000 Unit_Volt, raw 0..4095, unit=Unit_Volt, transfer-property=PENDING, to Klima(timeout 0.5 s)  # Aktuelle Spannung der Batterie. Innerhalb der Batterie an den Zellmodulen gemessen, also _vor_ den Schützen und der Sicherung.
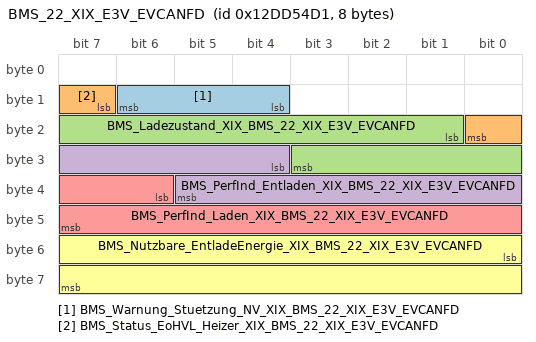
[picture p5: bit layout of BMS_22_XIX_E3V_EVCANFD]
      frame BMS_22_XIX_E3V_EVCANFD: id 0x12DD54D1, to Klima, frame-length=8, can-addressing-mode=EXTENDED, can-frame-rx-behavior=CAN-FD, can-frame-tx-behavior=CAN-FD
        pdu BMS_22_XIX_E3V_EVCANFD: length=8, transmission-mode-true-timing=cyclic-timing={time-offset=0.0, time-period=0.1}, unused-bit-pattern=0
          signal BMS_Warnung_Stuetzung_NV_XIX_BMS_22_XIX_E3V_EVCANFD: start 12, 3 bit, little-endian, data-type-policy=OVERRIDE, i-signal-type=PRIMITIVE, init-value=6, base-type=BT_BMS_Warnung_Stuetzung_NV, invalid-value=Invalid_BMS_Warnung_Stuetzung_NV_XIX_BMS_22_XIX_E3V_EVCANFD:7, compu {0=Cx0_Stuetzung_iO (CM_BMS_Warnung_Stuetzung_NV_Cx0_Stuetzung_iO), 1=Cx1_Stuetzung_niO (CM_BMS_Warnung_Stuetzung_NV_Cx1_Stuetzung_niO), 6=Cx6_Init (CM_BMS_Warnung_Stuetzung_NV_Cx6_Init), 7=Cx7_Fehler (CM_BMS_Warnung_Stuetzung_NV_Cx7_Fehler)}, range raw 0..7, transfer-property=PENDING  # Warnung an das Energiemanagement zur Verfügbarkeit der sicherheitsrelevanten NV-Stützung. Bei Stuetzung_iO kann die HV-Batterie zum aktuellen Zeitpunkt für die vorgegebene Dauer die notwendige Leistung/Energie zur Stützung des NV-Systems zur Verfügung stellen. Kann die Stützung nicht garantiert/sichergestellt werden, so wird dies über Stuetzung_niO angezeigt.
          signal BMS_Status_EoHVL_Heizer_XIX_BMS_22_XIX_E3V_EVCANFD: start 15, 2 bit, little-endian, data-type-policy=OVERRIDE, i-signal-type=PRIMITIVE, init-value=0, base-type=BT_BMS_Status_EoHVL_Heizer, invalid-value=Invalid_BMS_Status_EoHVL_Heizer_XIX_BMS_22_XIX_E3V_EVCANFD:3, compu {0=Cx0_Init (CM_BMS_Status_EoHVL_Heizer_Cx0_Init), 1=Cx1_Keine_offene_HV_Leitung_erkannt (CM_BMS_Status_EoHVL_Heizer_Cx1_Keine_offene_HV_Leitung_erkannt), 2=Cx2_offene_HV_Leitung_erkannt (CM_BMS_Status_EoHVL_Heizer_Cx2_offene_HV_Leitung_erkannt), 3=Cx3_Fehler (CM_BMS_Status_EoHVL_Heizer_Cx3_Fehler)}, range raw 0..3, transfer-property=PENDING  # Status Erkennung offener HV-Leitung (EoHVL) / offene Steckverbindung zum HV-Batterieheizer (PTC): 0=Init 1=Keine offene HV-Leitung erkannt 2=offene HV-Leitung erkannt 3=Fehler
          signal BMS_Ladezustand_XIX_BMS_22_XIX_E3V_EVCANFD: start 17, 11 bit, little-endian, data-type-policy=OVERRIDE, i-signal-type=PRIMITIVE, init-value=2046, base-type=BT_BMS_Ladezustand, invalid-value=Invalid_BMS_Ladezustand_XIX_BMS_22_XIX_E3V_EVCANFD:2047, compu {phys=raw*0.05 for raw 0..2000, 2046=Cx7fe_Init (CM_BMS_Ladezustand_Cx7fe_Init), 2047=Cx7ff_Fehler (CM_BMS_Ladezustand_Cx7ff_Fehler); unit Unit_PerCent}, range phys 0..100 Unit_PerCent, raw 0..2047, unit=Unit_PerCent, transfer-property=PENDING, to Klima(timeout 1 s)  # Aktueller Ladezustand (SOC) der Batterie. Es handelt sich NICHT um den dem Fahrer angezeigten Füllstand der Batterie, sondern um den technisch ermittelten, batterie-internen Ladezustand, bezogen auf die Brutto-Kapazität der Batterie.
          signal BMS_PerfInd_Entladen_XIX_BMS_22_XIX_E3V_EVCANFD: start 28, 10 bit, little-endian, data-type-policy=OVERRIDE, i-signal-type=PRIMITIVE, init-value=1022, base-type=BT_BMS_PerfInd_Entladen, compu {phys=raw*0.2 for raw 0..1000, 1022=Cx3fe_Init (CM_BMS_PerfInd_Entladen_Cx3fe_Init); unit Unit_PerCent}, range phys 0..200 Unit_PerCent, raw 0..1022, unit=Unit_PerCent, transfer-property=PENDING  # Leistungsindikation in Entladerichtung. Der Bereich 100...200% beschreibt die verbleibende Reserve, bis ein Derating der maximalen Entladeleistungsgrenze eintritt. Werte von 0 bis 100% beschreiben, auf welchen Teil der potentiell möglichen maximalen Entladeleistung die Entladeleistungsgrenze zurückgefahren worden ist.
          signal BMS_PerfInd_Laden_XIX_BMS_22_XIX_E3V_EVCANFD: start 38, 10 bit, little-endian, data-type-policy=OVERRIDE, i-signal-type=PRIMITIVE, init-value=1022, base-type=BT_BMS_PerfInd_Laden, compu {phys=raw*0.2 for raw 0..1000, 1022=Cx3fe_Init (CM_BMS_PerfInd_Laden_Cx3fe_Init); unit Unit_PerCent}, range phys 0..200 Unit_PerCent, raw 0..1022, unit=Unit_PerCent, transfer-property=PENDING  # Leistungsindikation in Laderichtung. Der Bereich 100...200% beschreibt die verbleibende Reserve, bis ein Derating der maximalen Ladeleistungsgrenze eintritt. Werte von 0 bis 100% beschreiben, auf welchen Teil der potentiell möglichen maximalen Ladeleistung die Ladeleistungsgrenze zurückgefahren worden ist.
          signal BMS_Nutzbare_EntladeEnergie_XIX_BMS_22_XIX_E3V_EVCANFD: start 48, 16 bit, little-endian, data-type-policy=OVERRIDE, i-signal-type=PRIMITIVE, init-value=65534, base-type=BT_BMS_Nutzbare_EntladeEnergie, invalid-value=Invalid_BMS_Nutzbare_EntladeEnergie_XIX_BMS_22_XIX_E3V_EVCANFD:65535, compu {phys=raw*5 for raw 0..65480, 65534=Cxfffe_Init (CM_BMS_Nutzbare_EntladeEnergie_Cxfffe_Init), 65535=Cxffff_Fehler (CM_BMS_Nutzbare_EntladeEnergie_Cxffff_Fehler); unit Unit_WattHour}, range phys 0..327400 Unit_WattHour, raw 0..65535, unit=Unit_WattHour, transfer-property=PENDING  # Aktuelle, verbleibende Energiemenge, die noch aus der Batterie entladen werden kann. Diese hängt in erster Linie vom aktuellen Ladezustand der Batterie ab. Projektabhängig kann die Energiemenge noch vom variablen SOC-Fenster, dem Alterungszustand, dem aktuellen Lastprofil sowie der Batterietemperatur abhängen.
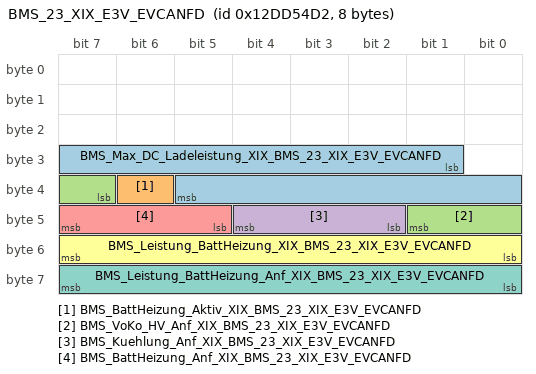
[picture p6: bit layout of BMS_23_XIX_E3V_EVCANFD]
      frame BMS_23_XIX_E3V_EVCANFD: id 0x12DD54D2, to Klima, frame-length=8, can-addressing-mode=EXTENDED, can-frame-rx-behavior=CAN-FD, can-frame-tx-behavior=CAN-FD
        pdu BMS_23_XIX_E3V_EVCANFD: length=8, transmission-mode-true-timing=cyclic-timing={time-offset=0.0, time-period=0.1}, unused-bit-pattern=0
          signal BMS_Max_DC_Ladeleistung_XIX_BMS_23_XIX_E3V_EVCANFD: start 25, 13 bit, little-endian, data-type-policy=OVERRIDE, i-signal-type=PRIMITIVE, init-value=8190, base-type=BT_BMS_Max_DC_Ladeleistung, compu {phys=raw*100 for raw 0..8180, 8190=Cx1ffe_Init (CM_BMS_Max_DC_Ladeleistung_Cx1ffe_Init); unit Unit_Watt}, range phys 0..818000 Unit_Watt, raw 0..8190, unit=Unit_Watt, transfer-property=PENDING  # Maximale Leistung, mit der die Batterie aktuell in einem DC-Lademodus geladen werden darf (Dauer-Ladeleistung). Wird auch im Fahrbetrieb berechnet und ausgegeben, so daß im Fahrbetrieb bereits über die Auswahl einer geeigneten Schnellademöglichkeit entschieden werden kann. Diese maximale DC-Ladeleistung kann im Fahrbetrieb einen anderen Wert einnehmen als die zugelassene maximale Rekuperationsleistung, die über Signal 'BMS_Max_Ladeleistung" kommuniziert wird.
          signal BMS_BattHeizung_Aktiv_XIX_BMS_23_XIX_E3V_EVCANFD: start 38, 1 bit, little-endian, data-type-policy=OVERRIDE, i-signal-type=PRIMITIVE, init-value=0, base-type=BT_BMS_BattHeizung_Aktiv, compu {0=Cx0_BMS_Heizer_inaktiv (CM_BMS_BattHeizung_Aktiv_Cx0_BMS_Heizer_inaktiv), 1=Cx1_BMS_Heizer_aktiv (CM_BMS_BattHeizung_Aktiv_Cx1_BMS_Heizer_aktiv)}, range raw 0..1, transfer-property=PENDING  # Aktivität des Batterieheizers
          signal BMS_VoKo_HV_Anf_XIX_BMS_23_XIX_E3V_EVCANFD: start 39, 3 bit, little-endian, data-type-policy=OVERRIDE, i-signal-type=PRIMITIVE, init-value=0, base-type=BT_BMS_VoKo_HV_Anf, compu {0=Cx0_keine_HV_Anf_Init (CM_BMS_VoKo_HV_Anf_Cx0_keine_HV_Anf_Init), 1=Cx1_HV_Anforderung_VK_Batterie (CM_BMS_VoKo_HV_Anf_Cx1_HV_Anforderung_VK_Batterie)}, range raw 0..1, transfer-property=PENDING  # Die HV-Batterie fordert die Aktivierung des HV-Netzes (beim HVEM) an, zur Durchführung der Batterie-Vorkonditionierung (Heizen oder Kühlen).
          signal BMS_Kuehlung_Anf_XIX_BMS_23_XIX_E3V_EVCANFD: start 42, 3 bit, little-endian, data-type-policy=OVERRIDE, i-signal-type=PRIMITIVE, init-value=0, base-type=BT_BMS_Kuehlung_Anf, compu {0=Cx0_keine_Batteriekuehlung (CM_BMS_Kuehlung_Anf_Cx0_keine_Batteriekuehlung), 1=Cx1_leichte_BattKuehl_InnenraumPrio (CM_BMS_Kuehlung_Anf_Cx1_leichte_BattKuehl_InnenraumPrio), 2=Cx2_hoehere_Batteriekuehlung (CM_BMS_Kuehlung_Anf_Cx2_hoehere_Batteriekuehlung), 3=Cx3_hohe_sofortige_Batteriekuehlung (CM_BMS_Kuehlung_Anf_Cx3_hohe_sofortige_Batteriekuehlung), 4=Cx4_Notfallkuehlung_Innenraumabwurf (CM_BMS_Kuehlung_Anf_Cx4_Notfallkuehlung_Innenraumabwurf), 5=Cx5_Kuehlen_ohne_Leistungseinsatz (CM_BMS_Kuehlung_Anf_Cx5_Kuehlen_ohne_Leistungseinsatz)}, range raw 0..5, transfer-property=PENDING, to Klima(timeout 1 s)  # Kühlungs-Anforderung der HV-Batterie, incl. Priorisierungsanforderung gegenüber Innenraumkühlung
          signal BMS_BattHeizung_Anf_XIX_BMS_23_XIX_E3V_EVCANFD: start 45, 3 bit, little-endian, data-type-policy=OVERRIDE, i-signal-type=PRIMITIVE, init-value=0, base-type=BT_BMS_BattHeizung_Anf, compu {0=Cx0_keine_Batterieheizung_Init (CM_BMS_BattHeizung_Anf_Cx0_keine_Batterieheizung_Init) (keine_Batterieheizung__Init), 1=Cx1_leichte_BattHeizung_Temp_halten (CM_BMS_BattHeizung_Anf_Cx1_leichte_BattHeizung_Temp_halten) (leichte_BattHeizung__Temp_halten), 2=Cx2_hoeherer_Batterieheizbedarf (CM_BMS_BattHeizung_Anf_Cx2_hoeherer_Batterieheizbedarf), 3=Cx3_hoher_sofortiger_Heizbedarf (CM_BMS_BattHeizung_Anf_Cx3_hoher_sofortiger_Heizbedarf)}, range raw 0..3, transfer-property=PENDING, to Klima(timeout 1 s)  # Heizungs-Anforderung der HV-Batterie, incl. einer Priorisierungsanforderung. 1 = leichte Abweichung von der "Wohlfühltemperatur", weiteres auskühlen verhindern. Leistungskontingent bereitstellen, falls Überschuss verfügbar. 2 = Fahrperformance-Einschränkungen sind zu erwarten, daher sollte der Batterie ein Heizleistungskontingent mit höherer Priorität bereitgestellt werden. 3 = Fahrzeugstart, Fahr- oder Ladebetrieb droht kritisch zu werden. Sofortige Batterieheizung, Priorität gegenüber Komfortfunktionen soll bereitgestellt werden.
          signal BMS_Leistung_BattHeizung_XIX_BMS_23_XIX_E3V_EVCANFD: start 48, 8 bit, little-endian, data-type-policy=OVERRIDE, i-signal-type=PRIMITIVE, init-value=254, base-type=BT_BMS_Leistung_BattHeizung, invalid-value=Invalid_BMS_Leistung_BattHeizung_XIX_BMS_23_XIX_E3V_EVCANFD:255, compu {phys=raw*50 for raw 0..250, 253=Cxfd_nicht_verbaut (CM_BMS_Leistung_BattHeizung_Cxfd_nicht_verbaut), 254=Cxfe_Init (CM_BMS_Leistung_BattHeizung_Cxfe_Init), 255=Cxff_Fehler (CM_BMS_Leistung_BattHeizung_Cxff_Fehler); unit Unit_Watt}, range phys 0..12500 Unit_Watt, raw 0..255, unit=Unit_Watt, transfer-property=PENDING  # aktuelle elektrische Leistung des vom BMS angesteuerten Batterieheizers
          signal BMS_Leistung_BattHeizung_Anf_XIX_BMS_23_XIX_E3V_EVCANFD: start 56, 8 bit, little-endian, data-type-policy=OVERRIDE, i-signal-type=PRIMITIVE, init-value=254, base-type=BT_BMS_Leistung_BattHeizung_Anf, invalid-value=Invalid_BMS_Leistung_BattHeizung_Anf_XIX_BMS_23_XIX_E3V_EVCANFD:255, compu {phys=raw*50 for raw 0..250, 253=Cxfd_nicht_berechnet (CM_BMS_Leistung_BattHeizung_Anf_Cxfd_nicht_berechnet), 254=Cxfe_Init (CM_BMS_Leistung_BattHeizung_Anf_Cxfe_Init), 255=Cxff_Fehler (CM_BMS_Leistung_BattHeizung_Anf_Cxff_Fehler); unit Unit_Watt}, range phys 0..12500 Unit_Watt, raw 0..255, unit=Unit_Watt, transfer-property=PENDING  # Wunsch-Leistungsbedarf der Batterieheizung
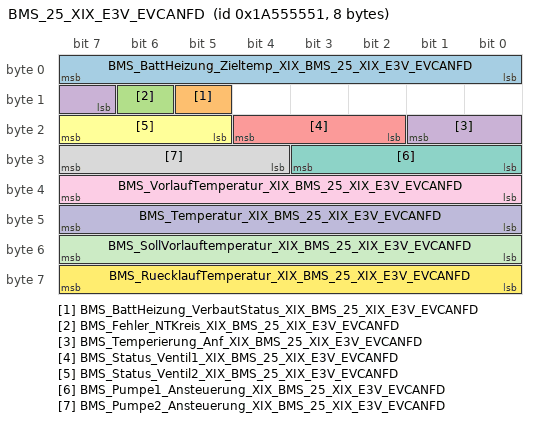
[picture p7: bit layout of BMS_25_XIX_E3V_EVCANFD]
      frame BMS_25_XIX_E3V_EVCANFD: id 0x1A555551, to Klima, frame-length=8, can-addressing-mode=EXTENDED, can-frame-rx-behavior=CAN-FD, can-frame-tx-behavior=CAN-FD
        pdu BMS_25_XIX_E3V_EVCANFD: length=8, transmission-mode-true-timing=cyclic-timing={time-offset=0.0, time-period=0.5}, unused-bit-pattern=0
          signal BMS_BattHeizung_Zieltemp_XIX_BMS_25_XIX_E3V_EVCANFD: start 0, 8 bit, little-endian, data-type-policy=OVERRIDE, i-signal-type=PRIMITIVE, init-value=254, base-type=BT_BMS_BattHeizung_Zieltemp, compu {phys=raw*0.5-40 for raw 0..250, 253=Cxfd_nicht_berechnet (CM_BMS_BattHeizung_Zieltemp_Cxfd_nicht_berechnet), 254=Cxfe_Init (CM_BMS_BattHeizung_Zieltemp_Cxfe_Init); unit Unit_DegreCelsi}, range phys -40..85 Unit_DegreCelsi, raw 0..254, unit=Unit_DegreCelsi, transfer-property=PENDING  # Zieltemperatur, auf die im aktuellen Betriebsmodus die HV-Batterie geheizt werden soll.
          signal BMS_BattHeizung_VerbautStatus_XIX_BMS_25_XIX_E3V_EVCANFD: start 13, 1 bit, little-endian, data-type-policy=OVERRIDE, i-signal-type=PRIMITIVE, init-value=0, base-type=BT_BMS_BattHeizung_VerbautStatus, compu {0=Cx0_nicht_verbaut (CM_BMS_BattHeizung_VerbautStatus_Cx0_nicht_verbaut), 1=Cx1_verbaut (CM_BMS_BattHeizung_VerbautStatus_Cx1_verbaut)}, range raw 0..1, transfer-property=PENDING  # Verbausignalisierung der optionalen HV-Batterieheizung
          signal BMS_Fehler_NTKreis_XIX_BMS_25_XIX_E3V_EVCANFD: start 14, 1 bit, little-endian, data-type-policy=OVERRIDE, i-signal-type=PRIMITIVE, init-value=0, base-type=BT_BMS_Fehler_NTKreis, invalid-value=Invalid_BMS_Fehler_NTKreis_XIX_BMS_25_XIX_E3V_EVCANFD:1, compu {0=Cx0_kein_Fehler (CM_BMS_Fehler_NTKreis_Cx0_kein_Fehler), 1=Cx1_Fehler (CM_BMS_Fehler_NTKreis_Cx1_Fehler)}, range raw 0..1, transfer-property=PENDING, to Klima(timeout 5 s)  # Fehler im NTKreis, HV-Batterie wird nicht klimatisiert (Fehler, Fehlerfrei)
          signal BMS_Temperierung_Anf_XIX_BMS_25_XIX_E3V_EVCANFD: start 15, 3 bit, little-endian, data-type-policy=OVERRIDE, i-signal-type=PRIMITIVE, init-value=3, base-type=BT_BMS_Temperierung_Anf, compu {0=Cx0_hoher_Kuehlbedarf (CM_BMS_Temperierung_Anf_Cx0_hoher_Kuehlbedarf), 1=Cx1_mittlerer_Kuehlbedarf (CM_BMS_Temperierung_Anf_Cx1_mittlerer_Kuehlbedarf), 2=Cx2_niedriger_Kuehlbedarf (CM_BMS_Temperierung_Anf_Cx2_niedriger_Kuehlbedarf), 3=Cx3_kein_Temperierungsbedarf_Init (CM_BMS_Temperierung_Anf_Cx3_kein_Temperierungsbedarf_Init), 4=Cx4_niedriger_Heizbedarf (CM_BMS_Temperierung_Anf_Cx4_niedriger_Heizbedarf), 5=Cx5_mittlerer_Heizbedarf (CM_BMS_Temperierung_Anf_Cx5_mittlerer_Heizbedarf), 6=Cx6_hoher_Heizbedarf (CM_BMS_Temperierung_Anf_Cx6_hoher_Heizbedarf), 7=Cx7_Umwaelzungsbedarf (CM_BMS_Temperierung_Anf_Cx7_Umwaelzungsbedarf)}, range raw 0..7, transfer-property=PENDING, to Klima(timeout 5 s)  # Temperierungsbedarf der HV-Batterie
          signal BMS_Status_Ventil1_XIX_BMS_25_XIX_E3V_EVCANFD: start 18, 3 bit, little-endian, data-type-policy=OVERRIDE, i-signal-type=PRIMITIVE, init-value=6, base-type=BT_BMS_Status_Ventil1, invalid-value=Invalid_BMS_Status_Ventil1_XIX_BMS_25_XIX_E3V_EVCANFD:7, compu {0=Cx0_Ventil_nicht_angesteuert (CM_BMS_Status_Ventil1_Cx0_Ventil_nicht_angesteuert), 1=Cx1_Ventil_angesteuert (CM_BMS_Status_Ventil1_Cx1_Ventil_angesteuert), 2=Cx2_reserviert (CM_BMS_Status_Ventil1_Cx2_reserviert), 3=Cx3_reserviert (CM_BMS_Status_Ventil1_Cx3_reserviert), 4=Cx4_reserviert (CM_BMS_Status_Ventil1_Cx4_reserviert), 5=Cx5_Ventil_nicht_verbaut (CM_BMS_Status_Ventil1_Cx5_Ventil_nicht_verbaut), 6=Cx6_Init (CM_BMS_Status_Ventil1_Cx6_Init), 7=Cx7_Fehler (CM_BMS_Status_Ventil1_Cx7_Fehler)}, range raw 0..7, transfer-property=PENDING, to Klima(timeout 5 s)  # Status Ventil; wassergekühltes Batteriesystem. Batteriekreis-Absperrventil. nicht-angesteuert = Batterie im kleinen Kühlkreislauf, abgetrennt vom restlichen Kühlsystem angesteuert = Batterie eingeschleift in großen Kühlkreislauf (Niedertemperatur-Kühlkreis)
          signal BMS_Status_Ventil2_XIX_BMS_25_XIX_E3V_EVCANFD: start 21, 3 bit, little-endian, data-type-policy=OVERRIDE, i-signal-type=PRIMITIVE, init-value=6, base-type=BT_BMS_Status_Ventil2, invalid-value=Invalid_BMS_Status_Ventil2_XIX_BMS_25_XIX_E3V_EVCANFD:7, compu {0=Cx0_Ventil_nicht_angesteuert (CM_BMS_Status_Ventil2_Cx0_Ventil_nicht_angesteuert), 1=Cx1_Ventil_angesteuert (CM_BMS_Status_Ventil2_Cx1_Ventil_angesteuert), 2=Cx2_reserviert (CM_BMS_Status_Ventil2_Cx2_reserviert), 3=Cx3_reserviert (CM_BMS_Status_Ventil2_Cx3_reserviert), 4=Cx4_reserviert (CM_BMS_Status_Ventil2_Cx4_reserviert), 5=Cx5_Ventil_nicht_verbaut (CM_BMS_Status_Ventil2_Cx5_Ventil_nicht_verbaut), 6=Cx6_Init (CM_BMS_Status_Ventil2_Cx6_Init), 7=Cx7_Fehler (CM_BMS_Status_Ventil2_Cx7_Fehler)}, range raw 0..7, transfer-property=PENDING, to Klima(timeout 5 s)  # Status des zweiten Ventils; wassergekühltes Batteriesystem. Für Systeme, wo die Batterie ein zweites Ventil ansteuert. Belegung projektabhängig. nicht-angesteuert = großer Kühlkreislauf (Niedertemperatur-Kühlkreis) abgetrennt vom Batteriesystem oder Wärmetauscher angesteuert = Batterie oder Wärmetauscher eingeschleift in großen Kühlkreislauf (Niedertemperatur-Kühlkreis)
          signal BMS_Pumpe1_Ansteuerung_XIX_BMS_25_XIX_E3V_EVCANFD: start 24, 4 bit, little-endian, data-type-policy=OVERRIDE, i-signal-type=PRIMITIVE, init-value=14, base-type=BT_BMS_Pumpe1_Ansteuerung, invalid-value=Invalid_BMS_Pumpe1_Ansteuerung_XIX_BMS_25_XIX_E3V_EVCANFD:15, compu {phys=raw*10 for raw 0..10, 13=Cxd_nicht_verbaut (CM_BMS_Pumpe1_Ansteuerung_Cxd_nicht_verbaut), 14=Cxe_Init (CM_BMS_Pumpe1_Ansteuerung_Cxe_Init), 15=Cxf_Fehler (CM_BMS_Pumpe1_Ansteuerung_Cxf_Fehler); unit Unit_PerCent}, range phys 0..100 Unit_PerCent, raw 0..15, unit=Unit_PerCent, transfer-property=PENDING, to Klima(timeout 5 s)  # Ansteuerung der Batterie-Kühlmittelpumpe. 0% = Pumpe abgeschaltet 100% = Pumpe maximal angesteuert
          signal BMS_Pumpe2_Ansteuerung_XIX_BMS_25_XIX_E3V_EVCANFD: start 28, 4 bit, little-endian, data-type-policy=OVERRIDE, i-signal-type=PRIMITIVE, init-value=14, base-type=BT_BMS_Pumpe2_Ansteuerung, invalid-value=Invalid_BMS_Pumpe2_Ansteuerung_XIX_BMS_25_XIX_E3V_EVCANFD:15, compu {phys=raw*10 for raw 0..10, 13=Cxd_nicht_verbaut (CM_BMS_Pumpe2_Ansteuerung_Cxd_nicht_verbaut), 14=Cxe_Init (CM_BMS_Pumpe2_Ansteuerung_Cxe_Init), 15=Cxf_Fehler (CM_BMS_Pumpe2_Ansteuerung_Cxf_Fehler); unit Unit_PerCent}, range phys 0..100 Unit_PerCent, raw 0..15, unit=Unit_PerCent, transfer-property=PENDING, to Klima(timeout 5 s)  # Ansteuerung einer zweiten Kühlmittelpumpe. Projektabhängig für Systeme, die seitens Batterie zwei Pumpen ansteuern. 0% = Pumpe abgeschaltet 100% = Pumpe maximal angesteuert
          signal BMS_VorlaufTemperatur_XIX_BMS_25_XIX_E3V_EVCANFD: start 32, 8 bit, little-endian, data-type-policy=OVERRIDE, i-signal-type=PRIMITIVE, init-value=254, base-type=BT_BMS_VorlaufTemperatur, invalid-value=Invalid_BMS_VorlaufTemperatur_XIX_BMS_25_XIX_E3V_EVCANFD:255, compu {phys=raw*0.5-40 for raw 0..252, 253=Cxfd_nicht_verbaut (CM_BMS_VorlaufTemperatur_Cxfd_nicht_verbaut), 254=Cxfe_Init (CM_BMS_VorlaufTemperatur_Cxfe_Init), 255=Cxff_Fehler (CM_BMS_VorlaufTemperatur_Cxff_Fehler); unit Unit_DegreCelsi}, range phys -40..86 Unit_DegreCelsi, raw 0..255, unit=Unit_DegreCelsi, transfer-property=PENDING, to Klima(timeout 5 s)  # Aktueller Messwert der Kühlmittel-Vorlauftemperatur am Kühlmittel-Einlass des Batteriesystems.
          signal BMS_Temperatur_XIX_BMS_25_XIX_E3V_EVCANFD: start 40, 8 bit, little-endian, data-type-policy=OVERRIDE, i-signal-type=PRIMITIVE, init-value=254, base-type=BT_BMS_Temperatur, invalid-value=Invalid_BMS_Temperatur_XIX_BMS_25_XIX_E3V_EVCANFD:255, compu {phys=raw*0.5-40 for raw 0..253, 254=Cxfe_Init (CM_BMS_Temperatur_Cxfe_Init), 255=Cxff_Fehler (CM_BMS_Temperatur_Cxff_Fehler); unit Unit_DegreCelsi}, range phys -40..86.5 Unit_DegreCelsi, raw 0..255, unit=Unit_DegreCelsi, transfer-property=PENDING, to Klima(timeout 5 s)  # battery temperature / Momentanwert: Temperatur der Traktionsbatterie
          signal BMS_SollVorlauftemperatur_XIX_BMS_25_XIX_E3V_EVCANFD: start 48, 8 bit, little-endian, data-type-policy=OVERRIDE, i-signal-type=PRIMITIVE, init-value=254, base-type=BT_BMS_SollVorlauftemperatur, invalid-value=Invalid_BMS_SollVorlauftemperatur_XIX_BMS_25_XIX_E3V_EVCANFD:255, compu {phys=raw*0.5-40 for raw 0..253, 254=Cxfe_Init (CM_BMS_SollVorlauftemperatur_Cxfe_Init), 255=Cxff_Fehler (CM_BMS_SollVorlauftemperatur_Cxff_Fehler); unit Unit_DegreCelsi}, range phys -40..86.5 Unit_DegreCelsi, raw 0..255, unit=Unit_DegreCelsi, transfer-property=PENDING, to Klima(timeout 5 s)  # Soll_Vorlauftemperatur_Kühlmedium in °C
          signal BMS_RuecklaufTemperatur_XIX_BMS_25_XIX_E3V_EVCANFD: start 56, 8 bit, little-endian, data-type-policy=OVERRIDE, i-signal-type=PRIMITIVE, init-value=254, base-type=BT_BMS_RuecklaufTemperatur, invalid-value=Invalid_BMS_RuecklaufTemperatur_XIX_BMS_25_XIX_E3V_EVCANFD:255, compu {phys=raw*0.5-40 for raw 0..252, 253=Cxfd_nicht_verbaut (CM_BMS_RuecklaufTemperatur_Cxfd_nicht_verbaut), 254=Cxfe_Init (CM_BMS_RuecklaufTemperatur_Cxfe_Init), 255=Cxff_Fehler (CM_BMS_RuecklaufTemperatur_Cxff_Fehler); unit Unit_DegreCelsi}, range phys -40..86 Unit_DegreCelsi, raw 0..255, unit=Unit_DegreCelsi, transfer-property=PENDING, to Klima(timeout 5 s)  # Aktueller Messwert der Kühlmittel-Rücklauftemperatur am Kühlmittel-Auslass des Batteriesystems.
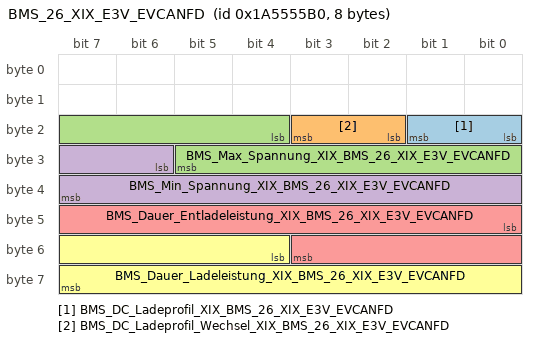
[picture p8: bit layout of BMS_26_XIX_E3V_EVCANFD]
      frame BMS_26_XIX_E3V_EVCANFD: id 0x1A5555B0, to Klima, frame-length=8, can-addressing-mode=EXTENDED, can-frame-rx-behavior=CAN-FD, can-frame-tx-behavior=CAN-FD
        pdu BMS_26_XIX_E3V_EVCANFD: length=8, transmission-mode-true-timing=cyclic-timing={time-offset=0.0, time-period=1.0}, unused-bit-pattern=0
          signal BMS_DC_Ladeprofil_XIX_BMS_26_XIX_E3V_EVCANFD: start 16, 2 bit, little-endian, data-type-policy=OVERRIDE, i-signal-type=PRIMITIVE, init-value=0, base-type=BT_BMS_DC_Ladeprofil, compu {0=Cx0_Init (CM_BMS_DC_Ladeprofil_Cx0_Init), 1=Cx1_DCLaden (CM_BMS_DC_Ladeprofil_Cx1_DCLaden), 2=Cx2_BoostLaden (CM_BMS_DC_Ladeprofil_Cx2_BoostLaden)}, range raw 0..2, transfer-property=PENDING, to Klima(timeout 5 s)  # Akuelles DC-Ladeprofil der HV-Batterie
          signal BMS_DC_Ladeprofil_Wechsel_XIX_BMS_26_XIX_E3V_EVCANFD: start 18, 2 bit, little-endian, data-type-policy=OVERRIDE, i-signal-type=PRIMITIVE, init-value=0, base-type=BT_BMS_DC_Ladeprofil_Wechsel, compu {0=Cx0_Init (CM_BMS_DC_Ladeprofil_Wechsel_Cx0_Init), 1=Cx1_keinWechselMoeglich (CM_BMS_DC_Ladeprofil_Wechsel_Cx1_keinWechselMoeglich), 2=Cx2_WechselMoeglich (CM_BMS_DC_Ladeprofil_Wechsel_Cx2_WechselMoeglich)}, range raw 0..2, transfer-property=PENDING  # Wechselmöglichkeit des DC-Ladeprofils der HV-Batterie
          signal BMS_Max_Spannung_XIX_BMS_26_XIX_E3V_EVCANFD: start 20, 10 bit, little-endian, data-type-policy=OVERRIDE, i-signal-type=PRIMITIVE, init-value=1022, base-type=BT_BMS_Max_Spannung, compu {phys=raw for raw 0..1000, 1022=Cx3fe_Init (CM_BMS_Max_Spannung_Cx3fe_Init); unit Unit_Volt}, range phys 0..1000 Unit_Volt, raw 0..1022, unit=Unit_Volt, transfer-property=PENDING  # Maximal erlaubte Batteriespannung, zwingend einzuhaltender Grenzwert
          signal BMS_Min_Spannung_XIX_BMS_26_XIX_E3V_EVCANFD: start 30, 10 bit, little-endian, data-type-policy=OVERRIDE, i-signal-type=PRIMITIVE, init-value=1022, base-type=BT_BMS_Min_Spannung, compu {phys=raw for raw 0..1000, 1022=Cx3fe_Init (CM_BMS_Min_Spannung_Cx3fe_Init); unit Unit_Volt}, range phys 0..1000 Unit_Volt, raw 0..1022, unit=Unit_Volt, transfer-property=PENDING  # Minimal erlaubte Batteriespannung, zwingend einzuhaltender Grenzwert
          signal BMS_Dauer_Entladeleistung_XIX_BMS_26_XIX_E3V_EVCANFD: start 40, 12 bit, little-endian, data-type-policy=OVERRIDE, i-signal-type=PRIMITIVE, init-value=4094, base-type=BT_BMS_Dauer_Entladeleistung, compu {phys=raw*200 for raw 0..4090, 4094=Cxffe_Init (CM_BMS_Dauer_Entladeleistung_Cxffe_Init); unit Unit_Watt}, range phys 0..818000 Unit_Watt, raw 0..4094, unit=Unit_Watt, transfer-property=PENDING  # ist die aktuelle Dauer-Leistungsfähigkeit der Batterie. Wenn dieser Wert überschritten wird, kann ein zeitliches Derating der maximalen Leistungsgrenzen stattfindet. Die Dauerleistung ändert sich mit Batterietemperatur und Ladezustand.
          signal BMS_Dauer_Ladeleistung_XIX_BMS_26_XIX_E3V_EVCANFD: start 52, 12 bit, little-endian, data-type-policy=OVERRIDE, i-signal-type=PRIMITIVE, init-value=4094, base-type=BT_BMS_Dauer_Ladeleistung, compu {phys=raw*200 for raw 0..4090, 4094=Cxffe_Init (CM_BMS_Dauer_Ladeleistung_Cxffe_Init); unit Unit_Watt}, range phys 0..818000 Unit_Watt, raw 0..4094, unit=Unit_Watt, transfer-property=PENDING  # ist die aktuelle Dauer-Leistungsfähigkeit der Batterie. Wenn dieser Wert überschritten wird, kann ein zeitliches Derating der maximalen Leistungsgrenzen stattfindet. Die Dauerleistung ändert sich mit Batterietemperatur und Ladezustand.
